VERSION "14.1.0"

NS_ :

BS_:

BU_: CUSTOMER_ECU PACMOD

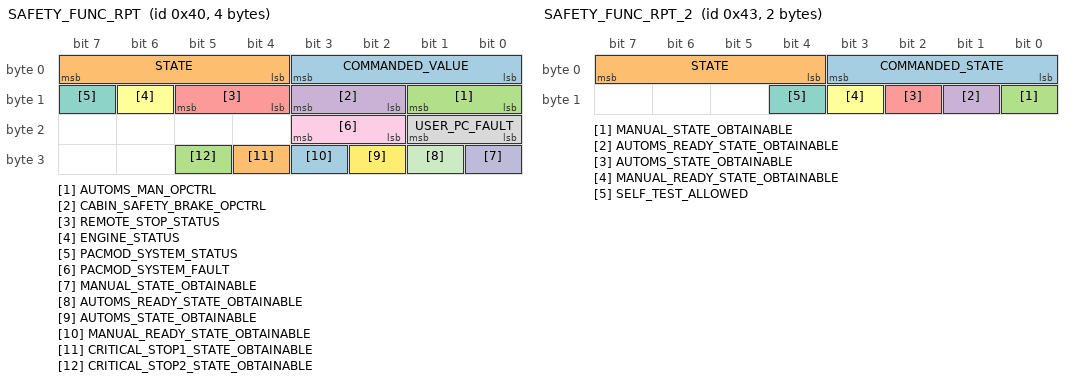
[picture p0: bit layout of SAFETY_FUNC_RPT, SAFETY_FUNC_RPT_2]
BO_ 64 SAFETY_FUNC_RPT: 4 PACMOD
 SG_ COMMANDED_VALUE : 3|4@0+ (1,0) [0|5] ""  CUSTOMER_ECU
 SG_ STATE : 7|4@0+ (1,0) [0|8] ""  CUSTOMER_ECU
 SG_ AUTOMS_MAN_OPCTRL : 9|2@0+ (1,0) [0|2] ""  CUSTOMER_ECU
 SG_ CABIN_SAFETY_BRAKE_OPCTRL : 11|2@0+ (1,0) [0|2] ""  CUSTOMER_ECU
 SG_ REMOTE_STOP_STATUS : 13|2@0+ (1,0) [0|2] ""  CUSTOMER_ECU
 SG_ ENGINE_STATUS : 14|1@0+ (1,0) [0|1] ""  CUSTOMER_ECU
 SG_ PACMOD_SYSTEM_STATUS : 15|1@0+ (1,0) [0|1] ""  CUSTOMER_ECU
 SG_ USER_PC_FAULT : 17|2@0+ (1,0) [0|2] ""  CUSTOMER_ECU
 SG_ PACMOD_SYSTEM_FAULT : 19|2@0+ (1,0) [0|2] ""  CUSTOMER_ECU
 SG_ MANUAL_STATE_OBTAINABLE : 24|1@0+ (1,0) [0|1] ""  CUSTOMER_ECU
 SG_ AUTOMS_READY_STATE_OBTAINABLE : 25|1@0+ (1,0) [0|1] ""  CUSTOMER_ECU
 SG_ AUTOMS_STATE_OBTAINABLE : 26|1@0+ (1,0) [0|1] ""  CUSTOMER_ECU
 SG_ MANUAL_READY_STATE_OBTAINABLE : 27|1@0+ (1,0) [0|1] ""  CUSTOMER_ECU
 SG_ CRITICAL_STOP1_STATE_OBTAINABLE : 28|1@0+ (1,0) [0|1] ""  CUSTOMER_ECU
 SG_ CRITICAL_STOP2_STATE_OBTAINABLE : 29|1@0+ (1,0) [0|1] ""  CUSTOMER_ECU

BO_ 67 SAFETY_FUNC_RPT_2: 2 PACMOD
 SG_ COMMANDED_STATE : 3|4@0+ (1,0) [0|3] ""  CUSTOMER_ECU
 SG_ STATE : 7|4@0+ (1,0) [0|15] ""  CUSTOMER_ECU
 SG_ MANUAL_STATE_OBTAINABLE : 8|1@0+ (1,0) [0|1] ""  CUSTOMER_ECU
 SG_ AUTOMS_READY_STATE_OBTAINABLE : 9|1@0+ (1,0) [0|1] ""  CUSTOMER_ECU
 SG_ AUTOMS_STATE_OBTAINABLE : 10|1@0+ (1,0) [0|1] ""  CUSTOMER_ECU
 SG_ MANUAL_READY_STATE_OBTAINABLE : 11|1@0+ (1,0) [0|1] ""  CUSTOMER_ECU
 SG_ SELF_TEST_ALLOWED : 12|1@0+ (1,0) [0|1] ""  CUSTOMER_ECU

BO_ 68 SAFETY_RESPONSE_RPT: 1 PACMOD
 SG_ SAFETY_RESPONSE : 3|4@0+ (1,0) [0|3] ""  CUSTOMER_ECU

BO_ 808 SHIFT_AUX_RPT: 7 PACMOD
 SG_ BETWEEN_GEARS : 0|1@0+ (1,0) [0|1] ""  CUSTOMER_ECU
 SG_ STAY_IN_NEUTRAL_MODE : 1|1@0+ (1,0) [0|1] ""  CUSTOMER_ECU
 SG_ BRAKE_INTERLOCK_ACTIVE : 2|1@0+ (1,0) [0|1] ""  CUSTOMER_ECU
 SG_ SPEED_INTERLOCK_ACTIVE : 3|1@0+ (1,0) [0|1] ""  CUSTOMER_ECU
 SG_ WRITE_TO_CONFIG : 4|1@0+ (1,0) [0|1] ""  CUSTOMER_ECU
 SG_ CALIBRATION_STATUS : 7|3@0+ (1,0) [0|3] ""  CUSTOMER_ECU
 SG_ BETWEEN_GEARS_AVAIL : 8|1@0+ (1,0) [0|1] ""  CUSTOMER_ECU
 SG_ STAY_IN_NEUTRAL_MODE_AVAIL : 9|1@0+ (1,0) [0|1] ""  CUSTOMER_ECU
 SG_ BRAKE_INTERLOCK_ACTIVE_AVAIL : 10|1@0+ (1,0) [0|1] ""  CUSTOMER_ECU
 SG_ SPEED_INTERLOCK_ACTIVE_AVAIL : 11|1@0+ (1,0) [0|1] ""  CUSTOMER_ECU
 SG_ WRITE_TO_CONFIG_IS_VALID : 12|1@0+ (1,0) [0|1] ""  CUSTOMER_ECU
 SG_ GEAR_NUMBER_AVAIL : 13|1@0+ (1,0) [0|1] ""  CUSTOMER_ECU
 SG_ SHIFT_MODE_AVAIL : 14|1@0+ (1,0) [0|1] ""  CUSTOMER_ECU
 SG_ SHIFT_IN_PROGRESS_AVAIL : 15|1@0+ (1,0) [0|1] ""  CUSTOMER_ECU
 SG_ GEAR_NUMBER : 21|6@0- (1,0) [-32|26] ""  CUSTOMER_ECU
 SG_ SHIFT_MODE : 23|2@0+ (1,0) [0|1] ""  CUSTOMER_ECU
 SG_ SHIFT_IN_PROGRESS : 25|2@0+ (1,0) [0|1] ""  CUSTOMER_ECU
 SG_ DRIVELINE_ENGAGED : 27|2@0+ (1,0) [0|1] ""  CUSTOMER_ECU
 SG_ ACTUAL_GEAR_RATIO : 39|16@0+ (0.001,0) [0|65.53] ""  CUSTOMER_ECU
 SG_ DRIVELINE_ENGAGED_AVAIL : 48|1@0+ (1,0) [0|1] ""  CUSTOMER_ECU
 SG_ ACTUAL_GEAR_RATIO_AVAIL : 49|1@0+ (1,0) [0|1] ""  CUSTOMER_ECU

BO_ 296 SHIFT_CMD: 2 CUSTOMER_ECU
 SG_ ENABLE : 0|1@0+ (1,0) [0|1] ""  PACMOD
 SG_ IGNORE_OVERRIDES : 1|1@0+ (1,0) [0|1] ""  PACMOD
 SG_ CLEAR_OVERRIDE : 2|1@0+ (1,0) [0|1] ""  PACMOD
 SG_ SHIFT_CMD : 15|8@0+ (1,0) [0|4] ""  PACMOD

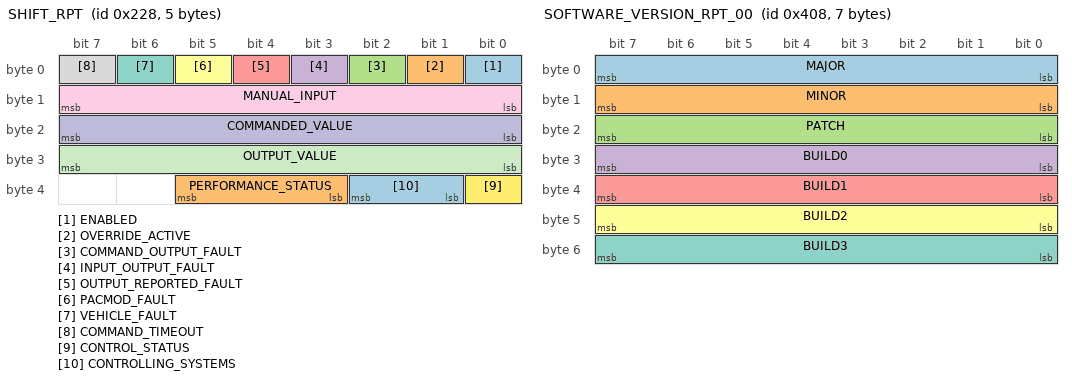
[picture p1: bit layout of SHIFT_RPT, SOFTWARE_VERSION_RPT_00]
BO_ 552 SHIFT_RPT: 5 PACMOD
 SG_ ENABLED : 0|1@0+ (1,0) [0|1] ""  CUSTOMER_ECU
 SG_ OVERRIDE_ACTIVE : 1|1@0+ (1,0) [0|1] ""  CUSTOMER_ECU
 SG_ COMMAND_OUTPUT_FAULT : 2|1@0+ (1,0) [0|1] ""  CUSTOMER_ECU
 SG_ INPUT_OUTPUT_FAULT : 3|1@0+ (1,0) [0|1] ""  CUSTOMER_ECU
 SG_ OUTPUT_REPORTED_FAULT : 4|1@0+ (1,0) [0|1] ""  CUSTOMER_ECU
 SG_ PACMOD_FAULT : 5|1@0+ (1,0) [0|1] ""  CUSTOMER_ECU
 SG_ VEHICLE_FAULT : 6|1@0+ (1,0) [0|1] ""  CUSTOMER_ECU
 SG_ COMMAND_TIMEOUT : 7|1@0+ (1,0) [0|1] ""  CUSTOMER_ECU
 SG_ MANUAL_INPUT : 15|8@0+ (1,0) [0|4] ""  CUSTOMER_ECU
 SG_ COMMANDED_VALUE : 23|8@0+ (1,0) [0|4] ""  CUSTOMER_ECU
 SG_ OUTPUT_VALUE : 31|8@0+ (1,0) [0|4] ""  CUSTOMER_ECU
 SG_ CONTROL_STATUS : 32|1@0+ (1,0) [0|1] ""  CUSTOMER_ECU
 SG_ CONTROLLING_SYSTEMS : 34|2@0+ (1,0) [0|3] ""  CUSTOMER_ECU
 SG_ PERFORMANCE_STATUS : 37|3@0+ (1,0) [0|4] ""  CUSTOMER_ECU

BO_ 1032 SOFTWARE_VERSION_RPT_00: 7 PACMOD
 SG_ MAJOR : 7|8@0+ (1,0) [0|255] ""  CUSTOMER_ECU
 SG_ MINOR : 15|8@0+ (1,0) [0|255] ""  CUSTOMER_ECU
 SG_ PATCH : 23|8@0+ (1,0) [0|255] ""  CUSTOMER_ECU
 SG_ BUILD0 : 31|8@0+ (1,0) [0|255] "ASCII"  CUSTOMER_ECU
 SG_ BUILD1 : 39|8@0+ (1,0) [0|255] "ASCII"  CUSTOMER_ECU
 SG_ BUILD2 : 47|8@0+ (1,0) [0|255] "ASCII"  CUSTOMER_ECU
 SG_ BUILD3 : 55|8@0+ (1,0) [0|255] "ASCII"  CUSTOMER_ECU

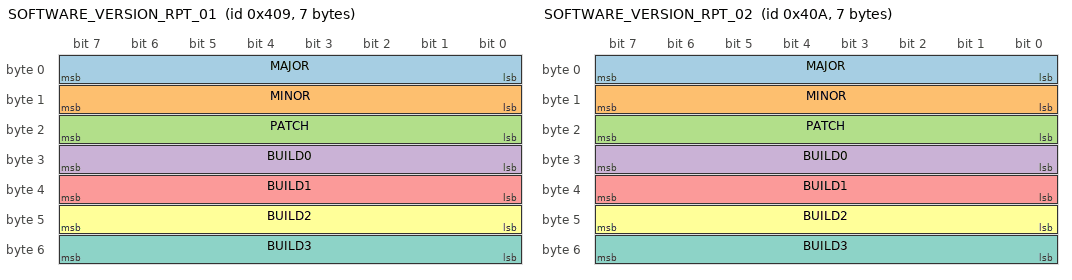
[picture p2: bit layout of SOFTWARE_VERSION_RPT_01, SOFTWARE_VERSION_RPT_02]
BO_ 1033 SOFTWARE_VERSION_RPT_01: 7 PACMOD
 SG_ MAJOR : 7|8@0+ (1,0) [0|255] ""  CUSTOMER_ECU
 SG_ MINOR : 15|8@0+ (1,0) [0|255] ""  CUSTOMER_ECU
 SG_ PATCH : 23|8@0+ (1,0) [0|255] ""  CUSTOMER_ECU
 SG_ BUILD0 : 31|8@0+ (1,0) [0|255] "ASCII"  CUSTOMER_ECU
 SG_ BUILD1 : 39|8@0+ (1,0) [0|255] "ASCII"  CUSTOMER_ECU
 SG_ BUILD2 : 47|8@0+ (1,0) [0|255] "ASCII"  CUSTOMER_ECU
 SG_ BUILD3 : 55|8@0+ (1,0) [0|255] "ASCII"  CUSTOMER_ECU

BO_ 1034 SOFTWARE_VERSION_RPT_02: 7 PACMOD
 SG_ MAJOR : 7|8@0+ (1,0) [0|255] ""  CUSTOMER_ECU
 SG_ MINOR : 15|8@0+ (1,0) [0|255] ""  CUSTOMER_ECU
 SG_ PATCH : 23|8@0+ (1,0) [0|255] ""  CUSTOMER_ECU
 SG_ BUILD0 : 31|8@0+ (1,0) [0|255] "ASCII"  CUSTOMER_ECU
 SG_ BUILD1 : 39|8@0+ (1,0) [0|255] "ASCII"  CUSTOMER_ECU
 SG_ BUILD2 : 47|8@0+ (1,0) [0|255] "ASCII"  CUSTOMER_ECU
 SG_ BUILD3 : 55|8@0+ (1,0) [0|255] "ASCII"  CUSTOMER_ECU

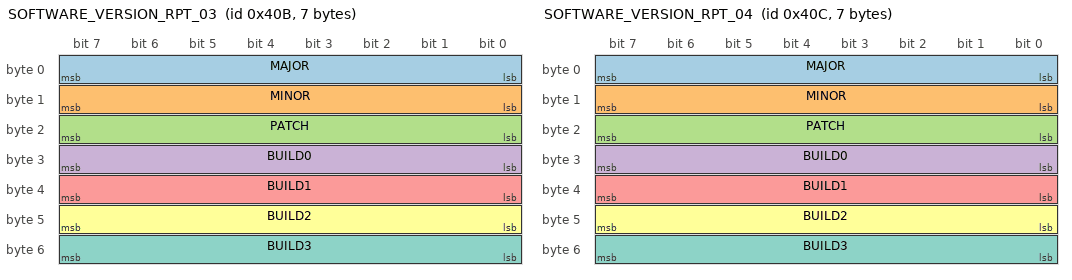
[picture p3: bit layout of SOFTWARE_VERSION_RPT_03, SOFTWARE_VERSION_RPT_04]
BO_ 1035 SOFTWARE_VERSION_RPT_03: 7 PACMOD
 SG_ MAJOR : 7|8@0+ (1,0) [0|255] ""  CUSTOMER_ECU
 SG_ MINOR : 15|8@0+ (1,0) [0|255] ""  CUSTOMER_ECU
 SG_ PATCH : 23|8@0+ (1,0) [0|255] ""  CUSTOMER_ECU
 SG_ BUILD0 : 31|8@0+ (1,0) [0|255] "ASCII"  CUSTOMER_ECU
 SG_ BUILD1 : 39|8@0+ (1,0) [0|255] "ASCII"  CUSTOMER_ECU
 SG_ BUILD2 : 47|8@0+ (1,0) [0|255] "ASCII"  CUSTOMER_ECU
 SG_ BUILD3 : 55|8@0+ (1,0) [0|255] "ASCII"  CUSTOMER_ECU

BO_ 1036 SOFTWARE_VERSION_RPT_04: 7 PACMOD
 SG_ MAJOR : 7|8@0+ (1,0) [0|255] ""  CUSTOMER_ECU
 SG_ MINOR : 15|8@0+ (1,0) [0|255] ""  CUSTOMER_ECU
 SG_ PATCH : 23|8@0+ (1,0) [0|255] ""  CUSTOMER_ECU
 SG_ BUILD0 : 31|8@0+ (1,0) [0|255] "ASCII"  CUSTOMER_ECU
 SG_ BUILD1 : 39|8@0+ (1,0) [0|255] "ASCII"  CUSTOMER_ECU
 SG_ BUILD2 : 47|8@0+ (1,0) [0|255] "ASCII"  CUSTOMER_ECU
 SG_ BUILD3 : 55|8@0+ (1,0) [0|255] "ASCII"  CUSTOMER_ECU

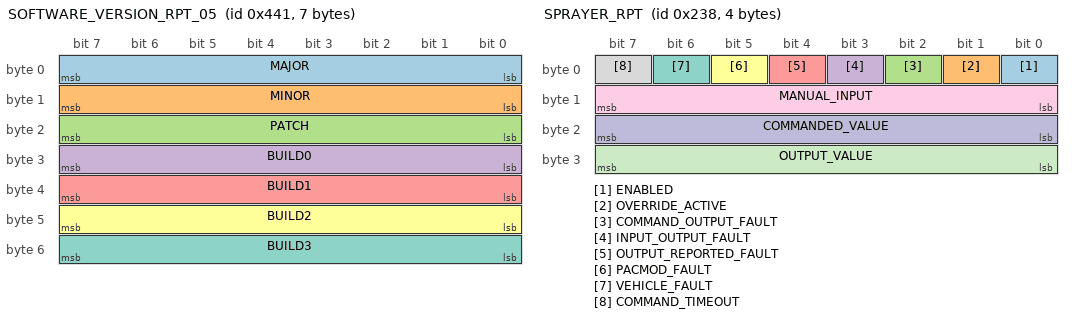
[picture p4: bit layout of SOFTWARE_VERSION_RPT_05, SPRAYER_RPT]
BO_ 1089 SOFTWARE_VERSION_RPT_05: 7 PACMOD
 SG_ MAJOR : 7|8@0+ (1,0) [0|255] ""  CUSTOMER_ECU
 SG_ MINOR : 15|8@0+ (1,0) [0|255] ""  CUSTOMER_ECU
 SG_ PATCH : 23|8@0+ (1,0) [0|255] ""  CUSTOMER_ECU
 SG_ BUILD0 : 31|8@0+ (1,0) [0|255] "ASCII"  CUSTOMER_ECU
 SG_ BUILD1 : 39|8@0+ (1,0) [0|255] "ASCII"  CUSTOMER_ECU
 SG_ BUILD2 : 47|8@0+ (1,0) [0|255] "ASCII"  CUSTOMER_ECU
 SG_ BUILD3 : 55|8@0+ (1,0) [0|255] "ASCII"  CUSTOMER_ECU

BO_ 312 SPRAYER_CMD: 2 CUSTOMER_ECU
 SG_ ENABLE : 0|1@0+ (1,0) [0|1] ""  PACMOD
 SG_ IGNORE_OVERRIDES : 1|1@0+ (1,0) [0|1] ""  PACMOD
 SG_ CLEAR_OVERRIDE : 2|1@0+ (1,0) [0|1] ""  PACMOD
 SG_ SPRAYER_CMD : 8|1@0+ (1,0) [0|1] ""  PACMOD

BO_ 568 SPRAYER_RPT: 4 PACMOD
 SG_ ENABLED : 0|1@0+ (1,0) [0|1] ""  CUSTOMER_ECU
 SG_ OVERRIDE_ACTIVE : 1|1@0+ (1,0) [0|1] ""  CUSTOMER_ECU
 SG_ COMMAND_OUTPUT_FAULT : 2|1@0+ (1,0) [0|1] ""  CUSTOMER_ECU
 SG_ INPUT_OUTPUT_FAULT : 3|1@0+ (1,0) [0|1] ""  CUSTOMER_ECU
 SG_ OUTPUT_REPORTED_FAULT : 4|1@0+ (1,0) [0|1] ""  CUSTOMER_ECU
 SG_ PACMOD_FAULT : 5|1@0+ (1,0) [0|1] ""  CUSTOMER_ECU
 SG_ VEHICLE_FAULT : 6|1@0+ (1,0) [0|1] ""  CUSTOMER_ECU
 SG_ COMMAND_TIMEOUT : 7|1@0+ (1,0) [0|1] ""  CUSTOMER_ECU
 SG_ MANUAL_INPUT : 15|8@0+ (1,0) [0|255] ""  CUSTOMER_ECU
 SG_ COMMANDED_VALUE : 23|8@0+ (1,0) [0|255] ""  CUSTOMER_ECU
 SG_ OUTPUT_VALUE : 31|8@0+ (1,0) [0|255] ""  CUSTOMER_ECU

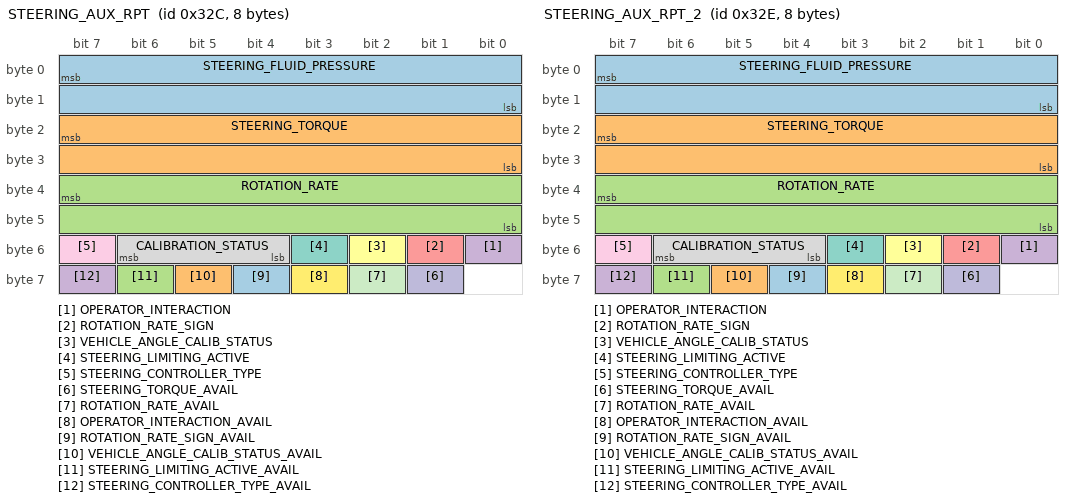
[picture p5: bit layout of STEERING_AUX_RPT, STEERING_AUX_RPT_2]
BO_ 812 STEERING_AUX_RPT: 8 PACMOD
 SG_ STEERING_FLUID_PRESSURE : 7|16@0+ (0.5,0) [0|32765] "kPa"  CUSTOMER_ECU
 SG_ STEERING_TORQUE : 23|16@0- (0.0001,0) [-2|2] "ratio"  CUSTOMER_ECU
 SG_ ROTATION_RATE : 39|16@0+ (0.001,0) [0|65.53] "rad/s"  CUSTOMER_ECU
 SG_ OPERATOR_INTERACTION : 48|1@0+ (1,0) [0|1] ""  CUSTOMER_ECU
 SG_ ROTATION_RATE_SIGN : 49|1@0+ (1,0) [0|1] ""  CUSTOMER_ECU
 SG_ VEHICLE_ANGLE_CALIB_STATUS : 50|1@0+ (1,0) [0|1] ""  CUSTOMER_ECU
 SG_ STEERING_LIMITING_ACTIVE : 51|1@0+ (1,0) [0|1] ""  CUSTOMER_ECU
 SG_ CALIBRATION_STATUS : 54|3@0+ (1,0) [0|3] ""  CUSTOMER_ECU
 SG_ STEERING_CONTROLLER_TYPE : 55|1@0+ (1,0) [0|1] ""  CUSTOMER_ECU
 SG_ STEERING_TORQUE_AVAIL : 57|1@0+ (1,0) [0|1] ""  CUSTOMER_ECU
 SG_ ROTATION_RATE_AVAIL : 58|1@0+ (1,0) [0|1] ""  CUSTOMER_ECU
 SG_ OPERATOR_INTERACTION_AVAIL : 59|1@0+ (1,0) [0|1] ""  CUSTOMER_ECU
 SG_ ROTATION_RATE_SIGN_AVAIL : 60|1@0+ (1,0) [0|1] ""  CUSTOMER_ECU
 SG_ VEHICLE_ANGLE_CALIB_STATUS_AVAIL : 61|1@0+ (1,0) [0|1] ""  CUSTOMER_ECU
 SG_ STEERING_LIMITING_ACTIVE_AVAIL : 62|1@0+ (1,0) [0|1] ""  CUSTOMER_ECU
 SG_ STEERING_CONTROLLER_TYPE_AVAIL : 63|1@0+ (1,0) [0|1] ""  CUSTOMER_ECU

BO_ 814 STEERING_AUX_RPT_2: 8 PACMOD
 SG_ STEERING_FLUID_PRESSURE : 7|16@0+ (0.5,0) [0|32765] "kPa"  CUSTOMER_ECU
 SG_ STEERING_TORQUE : 23|16@0- (0.0001,0) [-2|2] "ratio"  CUSTOMER_ECU
 SG_ ROTATION_RATE : 39|16@0+ (0.001,0) [0|65.53] "rad/s"  CUSTOMER_ECU
 SG_ OPERATOR_INTERACTION : 48|1@0+ (1,0) [0|1] ""  CUSTOMER_ECU
 SG_ ROTATION_RATE_SIGN : 49|1@0+ (1,0) [0|1] ""  CUSTOMER_ECU
 SG_ VEHICLE_ANGLE_CALIB_STATUS : 50|1@0+ (1,0) [0|1] ""  CUSTOMER_ECU
 SG_ STEERING_LIMITING_ACTIVE : 51|1@0+ (1,0) [0|1] ""  CUSTOMER_ECU
 SG_ CALIBRATION_STATUS : 54|3@0+ (1,0) [0|3] ""  CUSTOMER_ECU
 SG_ STEERING_CONTROLLER_TYPE : 55|1@0+ (1,0) [0|1] ""  CUSTOMER_ECU
 SG_ STEERING_TORQUE_AVAIL : 57|1@0+ (1,0) [0|1] ""  CUSTOMER_ECU
 SG_ ROTATION_RATE_AVAIL : 58|1@0+ (1,0) [0|1] ""  CUSTOMER_ECU
 SG_ OPERATOR_INTERACTION_AVAIL : 59|1@0+ (1,0) [0|1] ""  CUSTOMER_ECU
 SG_ ROTATION_RATE_SIGN_AVAIL : 60|1@0+ (1,0) [0|1] ""  CUSTOMER_ECU
 SG_ VEHICLE_ANGLE_CALIB_STATUS_AVAIL : 61|1@0+ (1,0) [0|1] ""  CUSTOMER_ECU
 SG_ STEERING_LIMITING_ACTIVE_AVAIL : 62|1@0+ (1,0) [0|1] ""  CUSTOMER_ECU
 SG_ STEERING_CONTROLLER_TYPE_AVAIL : 63|1@0+ (1,0) [0|1] ""  CUSTOMER_ECU

BO_ 300 STEERING_CMD: 5 CUSTOMER_ECU
 SG_ ENABLE : 0|1@0+ (1,0) [0|1] ""  PACMOD
 SG_ IGNORE_OVERRIDES : 1|1@0+ (1,0) [0|1] ""  PACMOD
 SG_ CLEAR_OVERRIDE : 2|1@0+ (1,0) [0|1] ""  PACMOD
 SG_ POSITION : 15|16@0- (0.001,0) [-32.768|32.767] "rad"  PACMOD
 SG_ ROTATION_RATE : 31|16@0+ (0.001,0) [0|65.535] "rad/s"  PACMOD

BO_ 557 STEERING_CMD_LIMIT_RPT: 8 PACMOD
 SG_ POSITION_CMD_LIMIT : 7|16@0- (0.001,0) [-32.768|32.767] "rad"  CUSTOMER_ECU
 SG_ LIMITED_POSITION_CMD : 23|16@0- (0.001,0) [-32.768|32.767] "rad"  CUSTOMER_ECU
 SG_ ROTATION_RATE_CMD_LIMIT : 39|16@0+ (0.001,0) [0|32.768] "rad/s"  CUSTOMER_ECU
 SG_ LIMITED_ROTATION_RATE : 55|16@0+ (0.001,0) [0|32.768] "rad/s"  CUSTOMER_ECU

BO_ 1028 STEERING_MOTOR_RPT_1: 8 PACMOD
 SG_ MOTOR_CURRENT : 7|32@0- (0.001,0) [-2048.0|2048.0] "amps"  CUSTOMER_ECU
 SG_ SHAFT_POSITION : 39|32@0- (0.001,0) [-2048.0|2048.0] "radians"  CUSTOMER_ECU

BO_ 1029 STEERING_MOTOR_RPT_2: 8 PACMOD
 SG_ ENCODER_TEMPERATURE : 7|16@0- (1,0) [-40|210] "deg_C"  CUSTOMER_ECU
 SG_ MOTOR_TEMPERATURE : 23|16@0- (1,0) [-40|210] "deg_C"  CUSTOMER_ECU
 SG_ ANGULAR_SPEED : 39|32@0- (0.001,0) [-12868.0|12868.0] "rad/s"  CUSTOMER_ECU

BO_ 1030 STEERING_MOTOR_RPT_3: 8 PACMOD
 SG_ TORQUE_OUTPUT : 7|32@0- (0.001,0) [-2048.0|2048.0] "N-m"  CUSTOMER_ECU
 SG_ TORQUE_INPUT : 39|32@0- (0.001,0) [-2048.0|2048.0] "N-m"  CUSTOMER_ECU

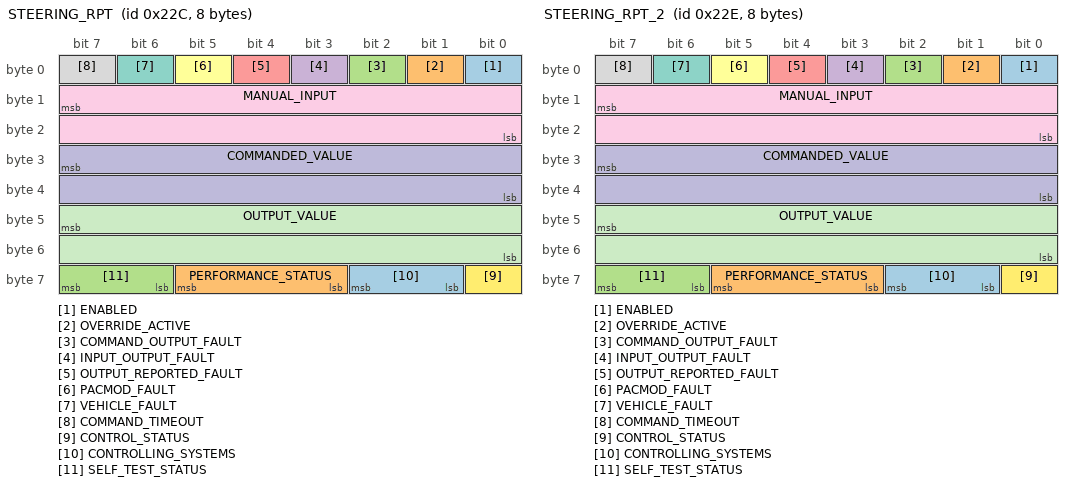
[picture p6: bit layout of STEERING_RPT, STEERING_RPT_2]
BO_ 556 STEERING_RPT: 8 PACMOD
 SG_ ENABLED : 0|1@0+ (1,0) [0|1] ""  CUSTOMER_ECU
 SG_ OVERRIDE_ACTIVE : 1|1@0+ (1,0) [0|1] ""  CUSTOMER_ECU
 SG_ COMMAND_OUTPUT_FAULT : 2|1@0+ (1,0) [0|1] ""  CUSTOMER_ECU
 SG_ INPUT_OUTPUT_FAULT : 3|1@0+ (1,0) [0|1] ""  CUSTOMER_ECU
 SG_ OUTPUT_REPORTED_FAULT : 4|1@0+ (1,0) [0|1] ""  CUSTOMER_ECU
 SG_ PACMOD_FAULT : 5|1@0+ (1,0) [0|1] ""  CUSTOMER_ECU
 SG_ VEHICLE_FAULT : 6|1@0+ (1,0) [0|1] ""  CUSTOMER_ECU
 SG_ COMMAND_TIMEOUT : 7|1@0+ (1,0) [0|1] ""  CUSTOMER_ECU
 SG_ MANUAL_INPUT : 15|16@0- (0.001,0) [-32.768|32.762] "rad"  CUSTOMER_ECU
 SG_ COMMANDED_VALUE : 31|16@0- (0.001,0) [-32.768|32.762] "rad"  CUSTOMER_ECU
 SG_ OUTPUT_VALUE : 47|16@0- (0.001,0) [-32.768|32.762] "rad"  CUSTOMER_ECU
 SG_ CONTROL_STATUS : 56|1@0+ (1,0) [0|1] ""  CUSTOMER_ECU
 SG_ CONTROLLING_SYSTEMS : 58|2@0+ (1,0) [0|3] ""  CUSTOMER_ECU
 SG_ PERFORMANCE_STATUS : 61|3@0+ (1,0) [0|4] ""  CUSTOMER_ECU
 SG_ SELF_TEST_STATUS : 63|2@0+ (1,0) [0|3] ""  CUSTOMER_ECU

BO_ 558 STEERING_RPT_2: 8 PACMOD
 SG_ ENABLED : 0|1@0+ (1,0) [0|1] ""  CUSTOMER_ECU
 SG_ OVERRIDE_ACTIVE : 1|1@0+ (1,0) [0|1] ""  CUSTOMER_ECU
 SG_ COMMAND_OUTPUT_FAULT : 2|1@0+ (1,0) [0|1] ""  CUSTOMER_ECU
 SG_ INPUT_OUTPUT_FAULT : 3|1@0+ (1,0) [0|1] ""  CUSTOMER_ECU
 SG_ OUTPUT_REPORTED_FAULT : 4|1@0+ (1,0) [0|1] ""  CUSTOMER_ECU
 SG_ PACMOD_FAULT : 5|1@0+ (1,0) [0|1] ""  CUSTOMER_ECU
 SG_ VEHICLE_FAULT : 6|1@0+ (1,0) [0|1] ""  CUSTOMER_ECU
 SG_ COMMAND_TIMEOUT : 7|1@0+ (1,0) [0|1] ""  CUSTOMER_ECU
 SG_ MANUAL_INPUT : 15|16@0- (0.001,0) [-32.768|32.762] "rad"  CUSTOMER_ECU
 SG_ COMMANDED_VALUE : 31|16@0- (0.001,0) [-32.768|32.762] "rad"  CUSTOMER_ECU
 SG_ OUTPUT_VALUE : 47|16@0- (0.001,0) [-32.768|32.762] "rad"  CUSTOMER_ECU
 SG_ CONTROL_STATUS : 56|1@0+ (1,0) [0|1] ""  CUSTOMER_ECU
 SG_ CONTROLLING_SYSTEMS : 58|2@0+ (1,0) [0|3] ""  CUSTOMER_ECU
 SG_ PERFORMANCE_STATUS : 61|3@0+ (1,0) [0|4] ""  CUSTOMER_ECU
 SG_ SELF_TEST_STATUS : 63|2@0+ (1,0) [0|3] ""  CUSTOMER_ECU

BO_ 1093 STEERING_TRQ_SENSOR_VOLTAGE_RPT: 8 PACMOD
 SG_ PACMOD_VOLTAGE_IN_1 : 7|16@0+ (0.001,0) [0|65] "V"  CUSTOMER_ECU
 SG_ PACMOD_VOLTAGE_IN_2 : 23|16@0+ (0.001,0) [0|65] "V"  CUSTOMER_ECU
 SG_ PACMOD_VOLTAGE_OUT_1 : 39|16@0+ (0.001,0) [0|65] "V"  CUSTOMER_ECU
 SG_ PACMOD_VOLTAGE_OUT_2 : 55|16@0+ (0.001,0) [0|65] "V"  CUSTOMER_ECU

BO_ 129 SUPERVISORY_CTRL: 2 CUSTOMER_ECU
 SG_ ENABLE : 0|1@0+ (1,0) [0|1] ""  PACMOD
 SG_ COUNTER : 11|4@0+ (1,0) [0|15] "" PACMOD
 SG_ COMPLEMENT : 15|4@0+ (1,0) [0|15] "" PACMOD

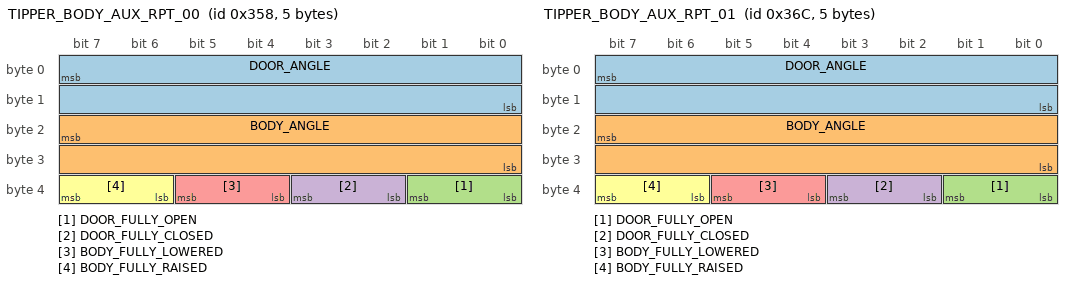
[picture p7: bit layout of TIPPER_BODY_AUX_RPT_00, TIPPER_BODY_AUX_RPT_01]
BO_ 856 TIPPER_BODY_AUX_RPT_00: 5 PACMOD
 SG_ DOOR_ANGLE : 7|16@0- (0.001,0) [-32.768|32.762] "rad"  CUSTOMER_ECU
 SG_ BODY_ANGLE : 23|16@0- (0.001,0) [-32.768|32.762] "rad"  CUSTOMER_ECU
 SG_ DOOR_FULLY_OPEN : 33|2@0+ (1,0) [0|3] ""  CUSTOMER_ECU
 SG_ DOOR_FULLY_CLOSED : 35|2@0+ (1,0) [0|3] ""  CUSTOMER_ECU
 SG_ BODY_FULLY_LOWERED : 37|2@0+ (1,0) [0|3] ""  CUSTOMER_ECU
 SG_ BODY_FULLY_RAISED : 39|2@0+ (1,0) [0|3] ""  CUSTOMER_ECU

BO_ 876 TIPPER_BODY_AUX_RPT_01: 5 PACMOD
 SG_ DOOR_ANGLE : 7|16@0- (0.001,0) [-32.768|32.762] "rad"  CUSTOMER_ECU
 SG_ BODY_ANGLE : 23|16@0- (0.001,0) [-32.768|32.762] "rad"  CUSTOMER_ECU
 SG_ DOOR_FULLY_OPEN : 33|2@0+ (1,0) [0|3] ""  CUSTOMER_ECU
 SG_ DOOR_FULLY_CLOSED : 35|2@0+ (1,0) [0|3] ""  CUSTOMER_ECU
 SG_ BODY_FULLY_LOWERED : 37|2@0+ (1,0) [0|3] ""  CUSTOMER_ECU
 SG_ BODY_FULLY_RAISED : 39|2@0+ (1,0) [0|3] ""  CUSTOMER_ECU

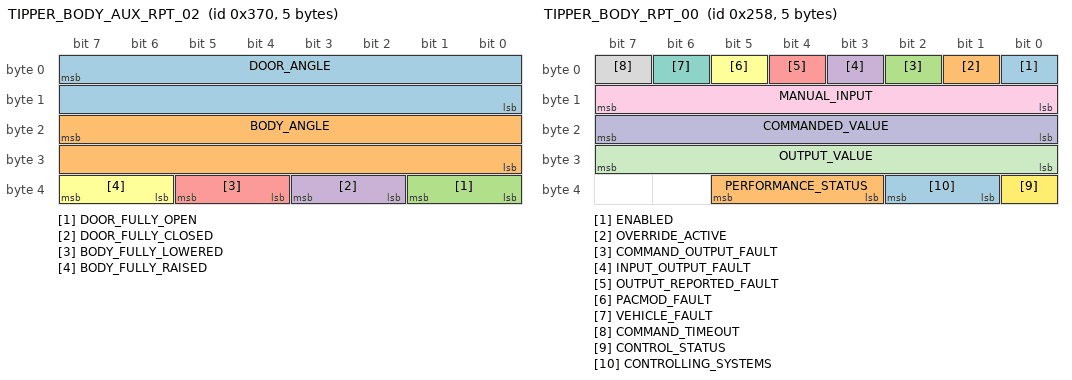
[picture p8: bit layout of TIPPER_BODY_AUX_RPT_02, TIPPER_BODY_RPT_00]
BO_ 880 TIPPER_BODY_AUX_RPT_02: 5 PACMOD
 SG_ DOOR_ANGLE : 7|16@0- (0.001,0) [-32.768|32.762] "rad"  CUSTOMER_ECU
 SG_ BODY_ANGLE : 23|16@0- (0.001,0) [-32.768|32.762] "rad"  CUSTOMER_ECU
 SG_ DOOR_FULLY_OPEN : 33|2@0+ (1,0) [0|3] ""  CUSTOMER_ECU
 SG_ DOOR_FULLY_CLOSED : 35|2@0+ (1,0) [0|3] ""  CUSTOMER_ECU
 SG_ BODY_FULLY_LOWERED : 37|2@0+ (1,0) [0|3] ""  CUSTOMER_ECU
 SG_ BODY_FULLY_RAISED : 39|2@0+ (1,0) [0|3] ""  CUSTOMER_ECU

BO_ 344 TIPPER_BODY_CMD_00: 2 CUSTOMER_ECU
 SG_ ENABLE : 0|1@0+ (1,0) [0|1] ""  PACMOD
 SG_ IGNORE_OVERRIDES : 1|1@0+ (1,0) [0|1] ""  PACMOD
 SG_ CLEAR_OVERRIDE : 2|1@0+ (1,0) [0|1] ""  PACMOD
 SG_ TIPPER_CONTROL_CMD : 15|8@0+ (1,0) [0|2] ""  PACMOD

BO_ 364 TIPPER_BODY_CMD_01: 2 CUSTOMER_ECU
 SG_ ENABLE : 0|1@0+ (1,0) [0|1] ""  PACMOD
 SG_ IGNORE_OVERRIDES : 1|1@0+ (1,0) [0|1] ""  PACMOD
 SG_ CLEAR_OVERRIDE : 2|1@0+ (1,0) [0|1] ""  PACMOD
 SG_ TIPPER_CONTROL_CMD : 15|8@0+ (1,0) [0|2] ""  PACMOD

BO_ 368 TIPPER_BODY_CMD_02: 2 CUSTOMER_ECU
 SG_ ENABLE : 0|1@0+ (1,0) [0|1] ""  PACMOD
 SG_ IGNORE_OVERRIDES : 1|1@0+ (1,0) [0|1] ""  PACMOD
 SG_ CLEAR_OVERRIDE : 2|1@0+ (1,0) [0|1] ""  PACMOD
 SG_ TIPPER_CONTROL_CMD : 15|8@0+ (1,0) [0|2] ""  PACMOD

BO_ 600 TIPPER_BODY_RPT_00: 5 PACMOD
 SG_ ENABLED : 0|1@0+ (1,0) [0|1] ""  CUSTOMER_ECU
 SG_ OVERRIDE_ACTIVE : 1|1@0+ (1,0) [0|1] ""  CUSTOMER_ECU
 SG_ COMMAND_OUTPUT_FAULT : 2|1@0+ (1,0) [0|1] ""  CUSTOMER_ECU
 SG_ INPUT_OUTPUT_FAULT : 3|1@0+ (1,0) [0|1] ""  CUSTOMER_ECU
 SG_ OUTPUT_REPORTED_FAULT : 4|1@0+ (1,0) [0|1] ""  CUSTOMER_ECU
 SG_ PACMOD_FAULT : 5|1@0+ (1,0) [0|1] ""  CUSTOMER_ECU
 SG_ VEHICLE_FAULT : 6|1@0+ (1,0) [0|1] ""  CUSTOMER_ECU
 SG_ COMMAND_TIMEOUT : 7|1@0+ (1,0) [0|1] ""  CUSTOMER_ECU
 SG_ MANUAL_INPUT : 15|8@0+ (1,0) [0|255] ""  CUSTOMER_ECU
 SG_ COMMANDED_VALUE : 23|8@0+ (1,0) [0|255] ""  CUSTOMER_ECU
 SG_ OUTPUT_VALUE : 31|8@0+ (1,0) [0|255] ""  CUSTOMER_ECU
 SG_ CONTROL_STATUS : 32|1@0+ (1,0) [0|1] ""  CUSTOMER_ECU
 SG_ CONTROLLING_SYSTEMS : 34|2@0+ (1,0) [0|3] ""  CUSTOMER_ECU
 SG_ PERFORMANCE_STATUS : 37|3@0+ (1,0) [0|4] ""  CUSTOMER_ECU

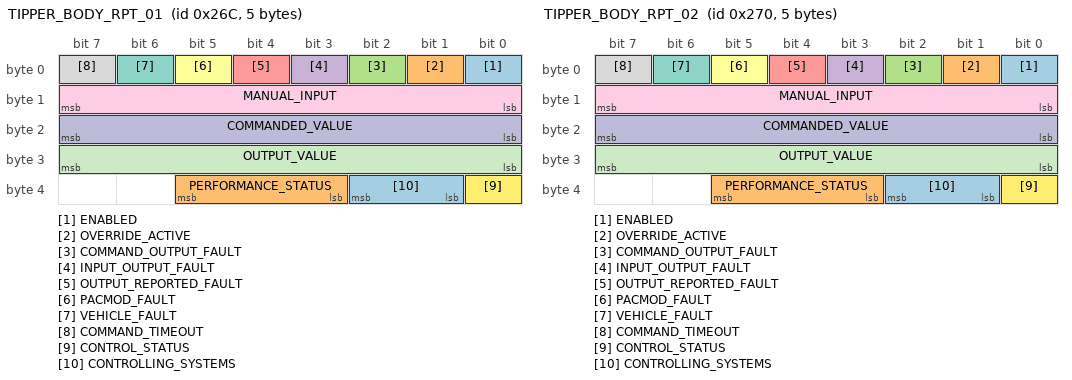
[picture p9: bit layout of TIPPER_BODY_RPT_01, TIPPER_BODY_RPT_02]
BO_ 620 TIPPER_BODY_RPT_01: 5 PACMOD
 SG_ ENABLED : 0|1@0+ (1,0) [0|1] ""  CUSTOMER_ECU
 SG_ OVERRIDE_ACTIVE : 1|1@0+ (1,0) [0|1] ""  CUSTOMER_ECU
 SG_ COMMAND_OUTPUT_FAULT : 2|1@0+ (1,0) [0|1] ""  CUSTOMER_ECU
 SG_ INPUT_OUTPUT_FAULT : 3|1@0+ (1,0) [0|1] ""  CUSTOMER_ECU
 SG_ OUTPUT_REPORTED_FAULT : 4|1@0+ (1,0) [0|1] ""  CUSTOMER_ECU
 SG_ PACMOD_FAULT : 5|1@0+ (1,0) [0|1] ""  CUSTOMER_ECU
 SG_ VEHICLE_FAULT : 6|1@0+ (1,0) [0|1] ""  CUSTOMER_ECU
 SG_ COMMAND_TIMEOUT : 7|1@0+ (1,0) [0|1] ""  CUSTOMER_ECU
 SG_ MANUAL_INPUT : 15|8@0+ (1,0) [0|255] ""  CUSTOMER_ECU
 SG_ COMMANDED_VALUE : 23|8@0+ (1,0) [0|255] ""  CUSTOMER_ECU
 SG_ OUTPUT_VALUE : 31|8@0+ (1,0) [0|255] ""  CUSTOMER_ECU
 SG_ CONTROL_STATUS : 32|1@0+ (1,0) [0|1] ""  CUSTOMER_ECU
 SG_ CONTROLLING_SYSTEMS : 34|2@0+ (1,0) [0|3] ""  CUSTOMER_ECU
 SG_ PERFORMANCE_STATUS : 37|3@0+ (1,0) [0|4] ""  CUSTOMER_ECU

BO_ 624 TIPPER_BODY_RPT_02: 5 PACMOD
 SG_ ENABLED : 0|1@0+ (1,0) [0|1] ""  CUSTOMER_ECU
 SG_ OVERRIDE_ACTIVE : 1|1@0+ (1,0) [0|1] ""  CUSTOMER_ECU
 SG_ COMMAND_OUTPUT_FAULT : 2|1@0+ (1,0) [0|1] ""  CUSTOMER_ECU
 SG_ INPUT_OUTPUT_FAULT : 3|1@0+ (1,0) [0|1] ""  CUSTOMER_ECU
 SG_ OUTPUT_REPORTED_FAULT : 4|1@0+ (1,0) [0|1] ""  CUSTOMER_ECU
 SG_ PACMOD_FAULT : 5|1@0+ (1,0) [0|1] ""  CUSTOMER_ECU
 SG_ VEHICLE_FAULT : 6|1@0+ (1,0) [0|1] ""  CUSTOMER_ECU
 SG_ COMMAND_TIMEOUT : 7|1@0+ (1,0) [0|1] ""  CUSTOMER_ECU
 SG_ MANUAL_INPUT : 15|8@0+ (1,0) [0|255] ""  CUSTOMER_ECU
 SG_ COMMANDED_VALUE : 23|8@0+ (1,0) [0|255] ""  CUSTOMER_ECU
 SG_ OUTPUT_VALUE : 31|8@0+ (1,0) [0|255] ""  CUSTOMER_ECU
 SG_ CONTROL_STATUS : 32|1@0+ (1,0) [0|1] ""  CUSTOMER_ECU
 SG_ CONTROLLING_SYSTEMS : 34|2@0+ (1,0) [0|3] ""  CUSTOMER_ECU
 SG_ PERFORMANCE_STATUS : 37|3@0+ (1,0) [0|4] ""  CUSTOMER_ECU

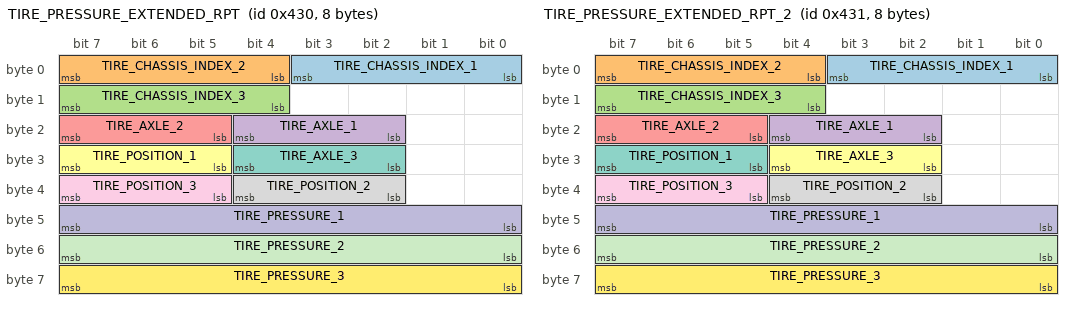
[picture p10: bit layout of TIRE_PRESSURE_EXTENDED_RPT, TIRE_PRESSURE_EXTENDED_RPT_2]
BO_ 1072 TIRE_PRESSURE_EXTENDED_RPT: 8 PACMOD
 SG_ TIRE_CHASSIS_INDEX_1 : 3|4@0+ (1,0) [0|15] ""  CUSTOMER_ECU
 SG_ TIRE_CHASSIS_INDEX_2 : 7|4@0+ (1,0) [0|15] ""  CUSTOMER_ECU
 SG_ TIRE_CHASSIS_INDEX_3 : 15|4@0+ (1,0) [0|15] ""  CUSTOMER_ECU
 SG_ TIRE_AXLE_1 : 20|3@0+ (1,0) [0|7] ""  CUSTOMER_ECU
 SG_ TIRE_AXLE_2 : 23|3@0+ (1,0) [0|7] ""  CUSTOMER_ECU
 SG_ TIRE_POSITION_1 : 31|3@0+ (1,0) [0|7] ""  CUSTOMER_ECU
 SG_ TIRE_AXLE_3 : 28|3@0+ (1,0) [0|7] ""  CUSTOMER_ECU
 SG_ TIRE_POSITION_2 : 36|3@0+ (1,0) [0|7] ""  CUSTOMER_ECU
 SG_ TIRE_POSITION_3 : 39|3@0+ (1,0) [0|7] ""  CUSTOMER_ECU
 SG_ TIRE_PRESSURE_1 : 47|8@0+ (10,0) [0|2500] "kPa"  CUSTOMER_ECU
 SG_ TIRE_PRESSURE_2 : 55|8@0+ (10,0) [0|2500] "kPa"  CUSTOMER_ECU
 SG_ TIRE_PRESSURE_3 : 63|8@0+ (10,0) [0|2500] "kPa"  CUSTOMER_ECU

BO_ 1073 TIRE_PRESSURE_EXTENDED_RPT_2: 8 PACMOD
 SG_ TIRE_CHASSIS_INDEX_1 : 3|4@0+ (1,0) [0|15] ""  CUSTOMER_ECU
 SG_ TIRE_CHASSIS_INDEX_2 : 7|4@0+ (1,0) [0|15] ""  CUSTOMER_ECU
 SG_ TIRE_CHASSIS_INDEX_3 : 15|4@0+ (1,0) [0|15] ""  CUSTOMER_ECU
 SG_ TIRE_AXLE_1 : 20|3@0+ (1,0) [0|7] ""  CUSTOMER_ECU
 SG_ TIRE_AXLE_2 : 23|3@0+ (1,0) [0|7] ""  CUSTOMER_ECU
 SG_ TIRE_AXLE_3 : 28|3@0+ (1,0) [0|7] ""  CUSTOMER_ECU
 SG_ TIRE_POSITION_1 : 31|3@0+ (1,0) [0|7] ""  CUSTOMER_ECU
 SG_ TIRE_POSITION_2 : 36|3@0+ (1,0) [0|7] ""  CUSTOMER_ECU
 SG_ TIRE_POSITION_3 : 39|3@0+ (1,0) [0|7] ""  CUSTOMER_ECU
 SG_ TIRE_PRESSURE_1 : 47|8@0+ (10,0) [0|2500] "kPa"  CUSTOMER_ECU
 SG_ TIRE_PRESSURE_2 : 55|8@0+ (10,0) [0|2500] "kPa"  CUSTOMER_ECU
 SG_ TIRE_PRESSURE_3 : 63|8@0+ (10,0) [0|2500] "kPa"  CUSTOMER_ECU

BO_ 1054 TIRE_PRESSURE_RPT: 4 PACMOD
 SG_ FRONT_LEFT_TIRE_PRESSURE : 7|8@0+ (4,0) [0|1020] "kPa"  CUSTOMER_ECU
 SG_ FRONT_RIGHT_TIRE_PRESSURE : 15|8@0+ (4,0) [0|1020] "kPa"  CUSTOMER_ECU
 SG_ REAR_LEFT_TIRE_PRESSURE : 23|8@0+ (4,0) [0|1020] "kPa"  CUSTOMER_ECU
 SG_ REAR_RIGHT_TIRE_PRESSURE : 31|8@0+ (4,0) [0|1020] "kPa"  CUSTOMER_ECU

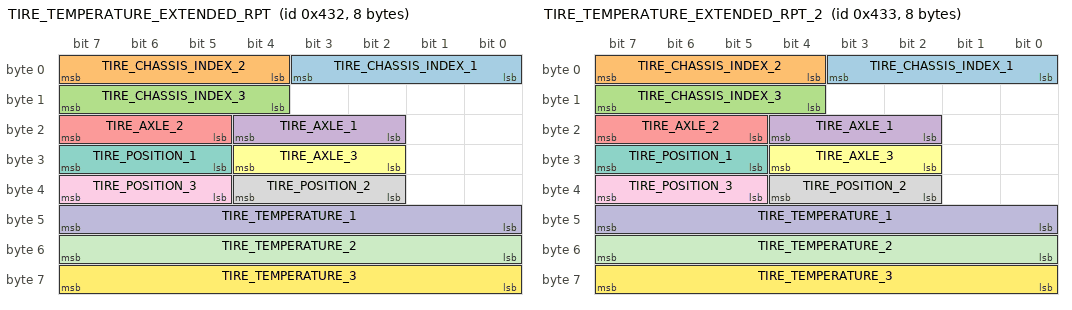
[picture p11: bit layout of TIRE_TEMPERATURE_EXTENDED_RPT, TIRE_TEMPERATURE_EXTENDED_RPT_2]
BO_ 1074 TIRE_TEMPERATURE_EXTENDED_RPT: 8 PACMOD
 SG_ TIRE_CHASSIS_INDEX_1 : 3|4@0+ (1,0) [0|15] ""  CUSTOMER_ECU
 SG_ TIRE_CHASSIS_INDEX_2 : 7|4@0+ (1,0) [0|15] ""  CUSTOMER_ECU
 SG_ TIRE_CHASSIS_INDEX_3 : 15|4@0+ (1,0) [0|15] ""  CUSTOMER_ECU
 SG_ TIRE_AXLE_1 : 20|3@0+ (1,0) [0|7] ""  CUSTOMER_ECU
 SG_ TIRE_AXLE_2 : 23|3@0+ (1,0) [0|7] ""  CUSTOMER_ECU
 SG_ TIRE_AXLE_3 : 28|3@0+ (1,0) [0|7] ""  CUSTOMER_ECU
 SG_ TIRE_POSITION_1 : 31|3@0+ (1,0) [0|7] ""  CUSTOMER_ECU
 SG_ TIRE_POSITION_2 : 36|3@0+ (1,0) [0|7] ""  CUSTOMER_ECU
 SG_ TIRE_POSITION_3 : 39|3@0+ (1,0) [0|7] ""  CUSTOMER_ECU
 SG_ TIRE_TEMPERATURE_1 : 47|8@0+ (1,-50) [0|200] "C"  CUSTOMER_ECU
 SG_ TIRE_TEMPERATURE_2 : 55|8@0+ (1,-50) [0|200] "C"  CUSTOMER_ECU
 SG_ TIRE_TEMPERATURE_3 : 63|8@0+ (1,-50) [0|200] "C"  CUSTOMER_ECU

BO_ 1075 TIRE_TEMPERATURE_EXTENDED_RPT_2: 8 PACMOD
 SG_ TIRE_CHASSIS_INDEX_1 : 3|4@0+ (1,0) [0|15] ""  CUSTOMER_ECU
 SG_ TIRE_CHASSIS_INDEX_2 : 7|4@0+ (1,0) [0|15] ""  CUSTOMER_ECU
 SG_ TIRE_CHASSIS_INDEX_3 : 15|4@0+ (1,0) [0|15] ""  CUSTOMER_ECU
 SG_ TIRE_AXLE_1 : 20|3@0+ (1,0) [0|7] ""  CUSTOMER_ECU
 SG_ TIRE_AXLE_2 : 23|3@0+ (1,0) [0|7] ""  CUSTOMER_ECU
 SG_ TIRE_AXLE_3 : 28|3@0+ (1,0) [0|7] ""  CUSTOMER_ECU
 SG_ TIRE_POSITION_1 : 31|3@0+ (1,0) [0|7] ""  CUSTOMER_ECU
 SG_ TIRE_POSITION_2 : 36|3@0+ (1,0) [0|7] ""  CUSTOMER_ECU
 SG_ TIRE_POSITION_3 : 39|3@0+ (1,0) [0|7] ""  CUSTOMER_ECU
 SG_ TIRE_TEMPERATURE_1 : 47|8@0+ (1,-50) [0|200] "C"  CUSTOMER_ECU
 SG_ TIRE_TEMPERATURE_2 : 55|8@0+ (1,-50) [0|200] "C"  CUSTOMER_ECU
 SG_ TIRE_TEMPERATURE_3 : 63|8@0+ (1,-50) [0|200] "C"  CUSTOMER_ECU

BO_ 356 TRAILER_AIR_SUPPLY_CMD: 2 CUSTOMER_ECU
 SG_ ENABLE : 0|1@0+ (1,0) [0|1] ""  PACMOD
 SG_ IGNORE_OVERRIDES : 1|1@0+ (1,0) [0|1] ""  PACMOD
 SG_ CLEAR_OVERRIDE : 2|1@0+ (1,0) [0|1] ""  PACMOD
 SG_ TRAILER_AIR_SUPPLY_CMD : 8|1@0+ (1,0) [0|1] ""  PACMOD

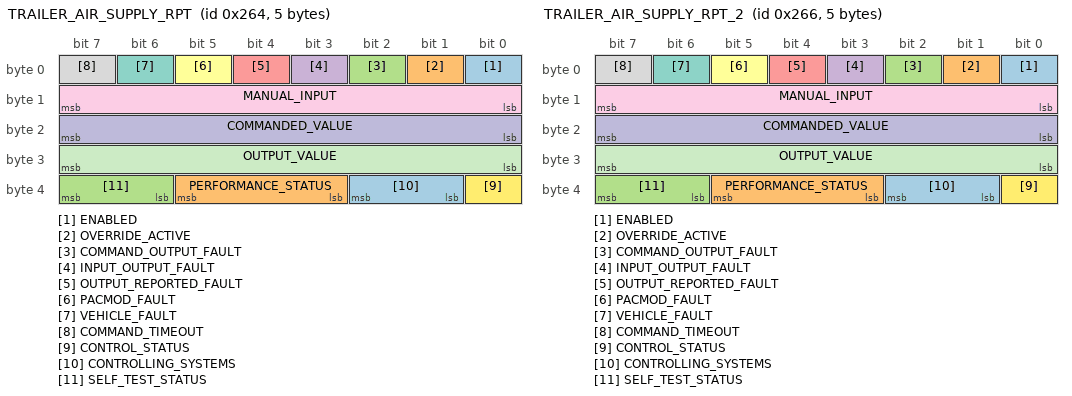
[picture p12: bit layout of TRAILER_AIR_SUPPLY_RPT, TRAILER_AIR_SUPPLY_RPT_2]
BO_ 612 TRAILER_AIR_SUPPLY_RPT: 5 PACMOD
 SG_ ENABLED : 0|1@0+ (1,0) [0|1] ""  CUSTOMER_ECU
 SG_ OVERRIDE_ACTIVE : 1|1@0+ (1,0) [0|1] ""  CUSTOMER_ECU
 SG_ COMMAND_OUTPUT_FAULT : 2|1@0+ (1,0) [0|1] ""  CUSTOMER_ECU
 SG_ INPUT_OUTPUT_FAULT : 3|1@0+ (1,0) [0|1] ""  CUSTOMER_ECU
 SG_ OUTPUT_REPORTED_FAULT : 4|1@0+ (1,0) [0|1] ""  CUSTOMER_ECU
 SG_ PACMOD_FAULT : 5|1@0+ (1,0) [0|1] ""  CUSTOMER_ECU
 SG_ VEHICLE_FAULT : 6|1@0+ (1,0) [0|1] ""  CUSTOMER_ECU
 SG_ COMMAND_TIMEOUT : 7|1@0+ (1,0) [0|1] ""  CUSTOMER_ECU
 SG_ MANUAL_INPUT : 15|8@0+ (1,0) [0|255] ""  CUSTOMER_ECU
 SG_ COMMANDED_VALUE : 23|8@0+ (1,0) [0|255] ""  CUSTOMER_ECU
 SG_ OUTPUT_VALUE : 31|8@0+ (1,0) [0|255] ""  CUSTOMER_ECU
 SG_ CONTROL_STATUS : 32|1@0+ (1,0) [0|1] ""  CUSTOMER_ECU
 SG_ CONTROLLING_SYSTEMS : 34|2@0+ (1,0) [0|3] ""  CUSTOMER_ECU
 SG_ PERFORMANCE_STATUS : 37|3@0+ (1,0) [0|4] ""  CUSTOMER_ECU
 SG_ SELF_TEST_STATUS : 39|2@0+ (1,0) [0|3] ""  CUSTOMER_ECU

BO_ 614 TRAILER_AIR_SUPPLY_RPT_2: 5 PACMOD
 SG_ ENABLED : 0|1@0+ (1,0) [0|1] ""  CUSTOMER_ECU
 SG_ OVERRIDE_ACTIVE : 1|1@0+ (1,0) [0|1] ""  CUSTOMER_ECU
 SG_ COMMAND_OUTPUT_FAULT : 2|1@0+ (1,0) [0|1] ""  CUSTOMER_ECU
 SG_ INPUT_OUTPUT_FAULT : 3|1@0+ (1,0) [0|1] ""  CUSTOMER_ECU
 SG_ OUTPUT_REPORTED_FAULT : 4|1@0+ (1,0) [0|1] ""  CUSTOMER_ECU
 SG_ PACMOD_FAULT : 5|1@0+ (1,0) [0|1] ""  CUSTOMER_ECU
 SG_ VEHICLE_FAULT : 6|1@0+ (1,0) [0|1] ""  CUSTOMER_ECU
 SG_ COMMAND_TIMEOUT : 7|1@0+ (1,0) [0|1] ""  CUSTOMER_ECU
 SG_ MANUAL_INPUT : 15|8@0+ (1,0) [0|255] ""  CUSTOMER_ECU
 SG_ COMMANDED_VALUE : 23|8@0+ (1,0) [0|255] ""  CUSTOMER_ECU
 SG_ OUTPUT_VALUE : 31|8@0+ (1,0) [0|255] ""  CUSTOMER_ECU
 SG_ CONTROL_STATUS : 32|1@0+ (1,0) [0|1] ""  CUSTOMER_ECU
 SG_ CONTROLLING_SYSTEMS : 34|2@0+ (1,0) [0|3] ""  CUSTOMER_ECU
 SG_ PERFORMANCE_STATUS : 37|3@0+ (1,0) [0|4] ""  CUSTOMER_ECU
 SG_ SELF_TEST_STATUS : 39|2@0+ (1,0) [0|3] ""  CUSTOMER_ECU

BO_ 352 TRAILER_BRAKE_CMD: 3 CUSTOMER_ECU
 SG_ ENABLE : 0|1@0+ (1,0) [0|1] ""  PACMOD
 SG_ IGNORE_OVERRIDES : 1|1@0+ (1,0) [0|1] ""  PACMOD
 SG_ CLEAR_OVERRIDE : 2|1@0+ (1,0) [0|1] ""  PACMOD
 SG_ TRAILER_BRAKE_CMD : 15|16@0+ (0.001,0) [0|1] "ratio"  PACMOD

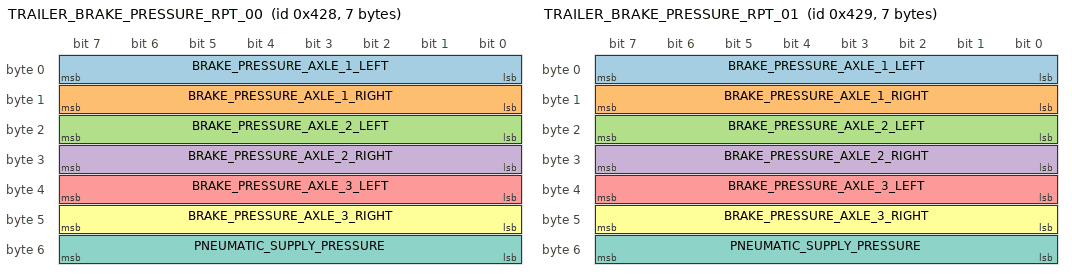
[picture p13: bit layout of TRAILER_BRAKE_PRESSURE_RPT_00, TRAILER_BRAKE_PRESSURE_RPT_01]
BO_ 1064 TRAILER_BRAKE_PRESSURE_RPT_00: 7 PACMOD
 SG_ BRAKE_PRESSURE_AXLE_1_LEFT : 7|8@0+ (5,0) [0|1250] "kPa"  CUSTOMER_ECU
 SG_ BRAKE_PRESSURE_AXLE_1_RIGHT : 15|8@0+ (5,0) [0|1250] "kPa"  CUSTOMER_ECU
 SG_ BRAKE_PRESSURE_AXLE_2_LEFT : 23|8@0+ (5,0) [0|1250] "kPa"  CUSTOMER_ECU
 SG_ BRAKE_PRESSURE_AXLE_2_RIGHT : 31|8@0+ (5,0) [0|1250] "kPa"  CUSTOMER_ECU
 SG_ BRAKE_PRESSURE_AXLE_3_LEFT : 39|8@0+ (5,0) [0|1250] "kPa"  CUSTOMER_ECU
 SG_ BRAKE_PRESSURE_AXLE_3_RIGHT : 47|8@0+ (5,0) [0|1250] "kPa"  CUSTOMER_ECU
 SG_ PNEUMATIC_SUPPLY_PRESSURE : 55|8@0+ (5,0) [0|1250] "kPa"  CUSTOMER_ECU

BO_ 1065 TRAILER_BRAKE_PRESSURE_RPT_01: 7 PACMOD
 SG_ BRAKE_PRESSURE_AXLE_1_LEFT : 7|8@0+ (5,0) [0|1250] "kPa"  CUSTOMER_ECU
 SG_ BRAKE_PRESSURE_AXLE_1_RIGHT : 15|8@0+ (5,0) [0|1250] "kPa"  CUSTOMER_ECU
 SG_ BRAKE_PRESSURE_AXLE_2_LEFT : 23|8@0+ (5,0) [0|1250] "kPa"  CUSTOMER_ECU
 SG_ BRAKE_PRESSURE_AXLE_2_RIGHT : 31|8@0+ (5,0) [0|1250] "kPa"  CUSTOMER_ECU
 SG_ BRAKE_PRESSURE_AXLE_3_LEFT : 39|8@0+ (5,0) [0|1250] "kPa"  CUSTOMER_ECU
 SG_ BRAKE_PRESSURE_AXLE_3_RIGHT : 47|8@0+ (5,0) [0|1250] "kPa"  CUSTOMER_ECU
 SG_ PNEUMATIC_SUPPLY_PRESSURE : 55|8@0+ (5,0) [0|1250] "kPa"  CUSTOMER_ECU

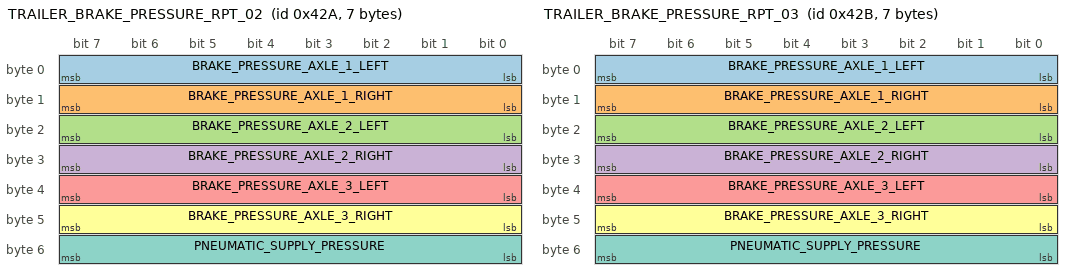
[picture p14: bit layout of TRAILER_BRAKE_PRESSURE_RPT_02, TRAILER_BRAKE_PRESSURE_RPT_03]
BO_ 1066 TRAILER_BRAKE_PRESSURE_RPT_02: 7 PACMOD
 SG_ BRAKE_PRESSURE_AXLE_1_LEFT : 7|8@0+ (5,0) [0|1250] "kPa"  CUSTOMER_ECU
 SG_ BRAKE_PRESSURE_AXLE_1_RIGHT : 15|8@0+ (5,0) [0|1250] "kPa"  CUSTOMER_ECU
 SG_ BRAKE_PRESSURE_AXLE_2_LEFT : 23|8@0+ (5,0) [0|1250] "kPa"  CUSTOMER_ECU
 SG_ BRAKE_PRESSURE_AXLE_2_RIGHT : 31|8@0+ (5,0) [0|1250] "kPa"  CUSTOMER_ECU
 SG_ BRAKE_PRESSURE_AXLE_3_LEFT : 39|8@0+ (5,0) [0|1250] "kPa"  CUSTOMER_ECU
 SG_ BRAKE_PRESSURE_AXLE_3_RIGHT : 47|8@0+ (5,0) [0|1250] "kPa"  CUSTOMER_ECU
 SG_ PNEUMATIC_SUPPLY_PRESSURE : 55|8@0+ (5,0) [0|1250] "kPa"  CUSTOMER_ECU

BO_ 1067 TRAILER_BRAKE_PRESSURE_RPT_03: 7 PACMOD
 SG_ BRAKE_PRESSURE_AXLE_1_LEFT : 7|8@0+ (5,0) [0|1250] "kPa"  CUSTOMER_ECU
 SG_ BRAKE_PRESSURE_AXLE_1_RIGHT : 15|8@0+ (5,0) [0|1250] "kPa"  CUSTOMER_ECU
 SG_ BRAKE_PRESSURE_AXLE_2_LEFT : 23|8@0+ (5,0) [0|1250] "kPa"  CUSTOMER_ECU
 SG_ BRAKE_PRESSURE_AXLE_2_RIGHT : 31|8@0+ (5,0) [0|1250] "kPa"  CUSTOMER_ECU
 SG_ BRAKE_PRESSURE_AXLE_3_LEFT : 39|8@0+ (5,0) [0|1250] "kPa"  CUSTOMER_ECU
 SG_ BRAKE_PRESSURE_AXLE_3_RIGHT : 47|8@0+ (5,0) [0|1250] "kPa"  CUSTOMER_ECU
 SG_ PNEUMATIC_SUPPLY_PRESSURE : 55|8@0+ (5,0) [0|1250] "kPa"  CUSTOMER_ECU

BO_ 1068 TRAILER_BRAKE_PRESSURE_RPT_04: 7 PACMOD
 SG_ BRAKE_PRESSURE_AXLE_1_LEFT : 7|8@0+ (5,0) [0|1250] "kPa"  CUSTOMER_ECU
 SG_ BRAKE_PRESSURE_AXLE_1_RIGHT : 15|8@0+ (5,0) [0|1250] "kPa"  CUSTOMER_ECU
 SG_ BRAKE_PRESSURE_AXLE_2_LEFT : 23|8@0+ (5,0) [0|1250] "kPa"  CUSTOMER_ECU
 SG_ BRAKE_PRESSURE_AXLE_2_RIGHT : 31|8@0+ (5,0) [0|1250] "kPa"  CUSTOMER_ECU
 SG_ BRAKE_PRESSURE_AXLE_3_LEFT : 39|8@0+ (5,0) [0|1250] "kPa"  CUSTOMER_ECU
 SG_ BRAKE_PRESSURE_AXLE_3_RIGHT : 47|8@0+ (5,0) [0|1250] "kPa"  CUSTOMER_ECU
 SG_ PNEUMATIC_SUPPLY_PRESSURE : 55|8@0+ (5,0) [0|1250] "kPa"  CUSTOMER_ECU

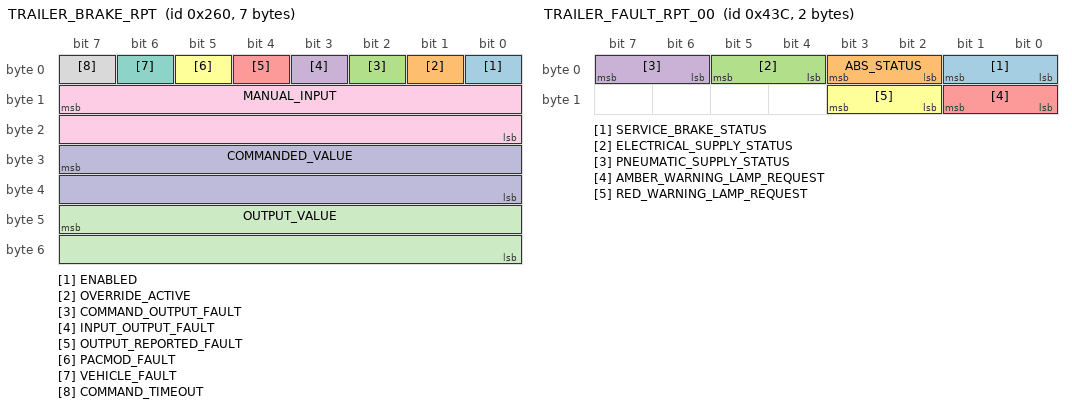
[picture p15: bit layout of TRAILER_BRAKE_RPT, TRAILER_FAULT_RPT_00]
BO_ 608 TRAILER_BRAKE_RPT: 7 PACMOD
 SG_ ENABLED : 0|1@0+ (1,0) [0|1] ""  CUSTOMER_ECU
 SG_ OVERRIDE_ACTIVE : 1|1@0+ (1,0) [0|1] ""  CUSTOMER_ECU
 SG_ COMMAND_OUTPUT_FAULT : 2|1@0+ (1,0) [0|1] ""  CUSTOMER_ECU
 SG_ INPUT_OUTPUT_FAULT : 3|1@0+ (1,0) [0|1] ""  CUSTOMER_ECU
 SG_ OUTPUT_REPORTED_FAULT : 4|1@0+ (1,0) [0|1] ""  CUSTOMER_ECU
 SG_ PACMOD_FAULT : 5|1@0+ (1,0) [0|1] ""  CUSTOMER_ECU
 SG_ VEHICLE_FAULT : 6|1@0+ (1,0) [0|1] ""  CUSTOMER_ECU
 SG_ COMMAND_TIMEOUT : 7|1@0+ (1,0) [0|1] ""  CUSTOMER_ECU
 SG_ MANUAL_INPUT : 15|16@0+ (0.001,0) [0|1] "ratio"  CUSTOMER_ECU
 SG_ COMMANDED_VALUE : 31|16@0+ (0.001,0) [0|1] "ratio"  CUSTOMER_ECU
 SG_ OUTPUT_VALUE : 47|16@0+ (0.001,0) [0|1] "ratio"  CUSTOMER_ECU

BO_ 1084 TRAILER_FAULT_RPT_00: 2 PACMOD
 SG_ SERVICE_BRAKE_STATUS : 1|2@0+ (1,0) [0|3] ""  CUSTOMER_ECU
 SG_ ABS_STATUS : 3|2@0+ (1,0) [0|3] ""  CUSTOMER_ECU
 SG_ ELECTRICAL_SUPPLY_STATUS : 5|2@0+ (1,0) [0|3] ""  CUSTOMER_ECU
 SG_ PNEUMATIC_SUPPLY_STATUS : 7|2@0+ (1,0) [0|3] ""  CUSTOMER_ECU
 SG_ AMBER_WARNING_LAMP_REQUEST : 9|2@0+ (1,0) [0|3] ""  CUSTOMER_ECU
 SG_ RED_WARNING_LAMP_REQUEST : 11|2@0+ (1,0) [0|3] ""  CUSTOMER_ECU

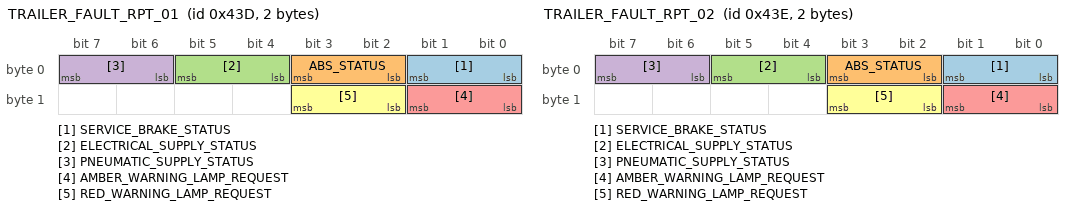
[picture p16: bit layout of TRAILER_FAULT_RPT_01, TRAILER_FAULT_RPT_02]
BO_ 1085 TRAILER_FAULT_RPT_01: 2 PACMOD
 SG_ SERVICE_BRAKE_STATUS : 1|2@0+ (1,0) [0|3] ""  CUSTOMER_ECU
 SG_ ABS_STATUS : 3|2@0+ (1,0) [0|3] ""  CUSTOMER_ECU
 SG_ ELECTRICAL_SUPPLY_STATUS : 5|2@0+ (1,0) [0|3] ""  CUSTOMER_ECU
 SG_ PNEUMATIC_SUPPLY_STATUS : 7|2@0+ (1,0) [0|3] ""  CUSTOMER_ECU
 SG_ AMBER_WARNING_LAMP_REQUEST : 9|2@0+ (1,0) [0|3] ""  CUSTOMER_ECU
 SG_ RED_WARNING_LAMP_REQUEST : 11|2@0+ (1,0) [0|3] ""  CUSTOMER_ECU

BO_ 1086 TRAILER_FAULT_RPT_02: 2 PACMOD
 SG_ SERVICE_BRAKE_STATUS : 1|2@0+ (1,0) [0|3] ""  CUSTOMER_ECU
 SG_ ABS_STATUS : 3|2@0+ (1,0) [0|3] ""  CUSTOMER_ECU
 SG_ ELECTRICAL_SUPPLY_STATUS : 5|2@0+ (1,0) [0|3] ""  CUSTOMER_ECU
 SG_ PNEUMATIC_SUPPLY_STATUS : 7|2@0+ (1,0) [0|3] ""  CUSTOMER_ECU
 SG_ AMBER_WARNING_LAMP_REQUEST : 9|2@0+ (1,0) [0|3] ""  CUSTOMER_ECU
 SG_ RED_WARNING_LAMP_REQUEST : 11|2@0+ (1,0) [0|3] ""  CUSTOMER_ECU

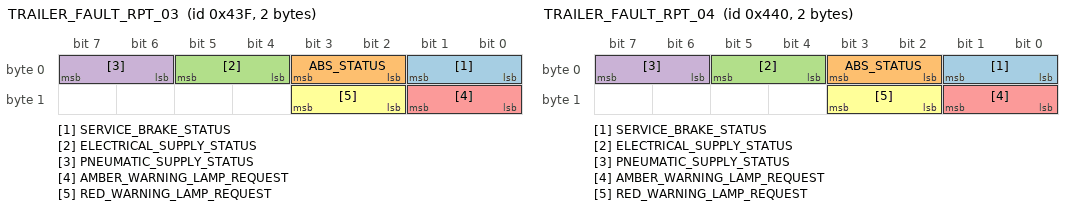
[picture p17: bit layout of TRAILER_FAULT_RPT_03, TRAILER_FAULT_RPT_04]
BO_ 1087 TRAILER_FAULT_RPT_03: 2 PACMOD
 SG_ SERVICE_BRAKE_STATUS : 1|2@0+ (1,0) [0|3] ""  CUSTOMER_ECU
 SG_ ABS_STATUS : 3|2@0+ (1,0) [0|3] ""  CUSTOMER_ECU
 SG_ ELECTRICAL_SUPPLY_STATUS : 5|2@0+ (1,0) [0|3] ""  CUSTOMER_ECU
 SG_ PNEUMATIC_SUPPLY_STATUS : 7|2@0+ (1,0) [0|3] ""  CUSTOMER_ECU
 SG_ AMBER_WARNING_LAMP_REQUEST : 9|2@0+ (1,0) [0|3] ""  CUSTOMER_ECU
 SG_ RED_WARNING_LAMP_REQUEST : 11|2@0+ (1,0) [0|3] ""  CUSTOMER_ECU

BO_ 1088 TRAILER_FAULT_RPT_04: 2 PACMOD
 SG_ SERVICE_BRAKE_STATUS : 1|2@0+ (1,0) [0|3] ""  CUSTOMER_ECU
 SG_ ABS_STATUS : 3|2@0+ (1,0) [0|3] ""  CUSTOMER_ECU
 SG_ ELECTRICAL_SUPPLY_STATUS : 5|2@0+ (1,0) [0|3] ""  CUSTOMER_ECU
 SG_ PNEUMATIC_SUPPLY_STATUS : 7|2@0+ (1,0) [0|3] ""  CUSTOMER_ECU
 SG_ AMBER_WARNING_LAMP_REQUEST : 9|2@0+ (1,0) [0|3] ""  CUSTOMER_ECU
 SG_ RED_WARNING_LAMP_REQUEST : 11|2@0+ (1,0) [0|3] ""  CUSTOMER_ECU

BO_ 1095 TRAILER_IDENTIFIER_RPT_00: 4 PACMOD
 SG_ TRAILER_IDENTIFIER : 7|32@0+ (1,0) [0|4294967295] ""  CUSTOMER_ECU

BO_ 1096 TRAILER_IDENTIFIER_RPT_01: 4 PACMOD
 SG_ TRAILER_IDENTIFIER : 7|32@0+ (1,0) [0|4294967295] ""  CUSTOMER_ECU

BO_ 1097 TRAILER_IDENTIFIER_RPT_02: 4 PACMOD
 SG_ TRAILER_IDENTIFIER : 7|32@0+ (1,0) [0|4294967295] ""  CUSTOMER_ECU

BO_ 1098 TRAILER_IDENTIFIER_RPT_03: 4 PACMOD
 SG_ TRAILER_IDENTIFIER : 7|32@0+ (1,0) [0|4294967295] ""  CUSTOMER_ECU

BO_ 1099 TRAILER_IDENTIFIER_RPT_04: 4 PACMOD
 SG_ TRAILER_IDENTIFIER : 7|32@0+ (1,0) [0|4294967295] ""  CUSTOMER_ECU

BO_ 1106 TRAILER_IDENTIFIER_RPT_05: 4 PACMOD
 SG_ TRAILER_IDENTIFIER : 7|32@0+ (1,0) [0|4294967295] ""  CUSTOMER_ECU

BO_ 1080 TRAILER_PAYLOAD_RPT_02: 8 PACMOD
 SG_ PAYLOAD_00 : 7|16@0- (10,0) [-327680|327610] "Kg"  CUSTOMER_ECU
 SG_ TARE_00 : 23|16@0+ (10,0) [0|655300] "Kg"  CUSTOMER_ECU
 SG_ PAYLOAD_01 : 39|16@0- (10,0) [-327680|327610] "Kg"  CUSTOMER_ECU
 SG_ TARE_01 : 55|16@0+ (10,0) [0|655300] "Kg"  CUSTOMER_ECU

BO_ 1079 TRAILER_PAYLOAD_RPT_01: 8 PACMOD
 SG_ PAYLOAD_00 : 7|16@0- (10,0) [-327680|327610] "Kg"  CUSTOMER_ECU
 SG_ TARE_00 : 23|16@0+ (10,0) [0|655300] "Kg"  CUSTOMER_ECU
 SG_ PAYLOAD_01 : 39|16@0- (10,0) [-327680|327610] "Kg"  CUSTOMER_ECU
 SG_ TARE_01 : 55|16@0+ (10,0) [0|655300] "Kg"  CUSTOMER_ECU

BO_ 1078 TRAILER_PAYLOAD_RPT_00: 8 PACMOD
 SG_ PAYLOAD_00 : 7|16@0- (10,0) [-327680|327610] "Kg"  CUSTOMER_ECU
 SG_ TARE_00 : 23|16@0+ (10,0) [0|655300] "Kg"  CUSTOMER_ECU
 SG_ PAYLOAD_01 : 39|16@0- (10,0) [-327680|327610] "Kg"  CUSTOMER_ECU
 SG_ TARE_01 : 55|16@0+ (10,0) [0|655300] "Kg"  CUSTOMER_ECU

BO_ 1069 TRAILER_WHEEL_SPEED_RPT_00: 4 PACMOD
 SG_ WHEEL_BASED_VEHICLE_SPEED : 7|16@0+ (0.00390625,0) [0|250] "km/h"  CUSTOMER_ECU
 SG_ WHEEL_SPEED_DIFFERENCE_MAIN_AXLE : 23|16@0+ (0.00390625,-125) [-125|125] "km/h"  CUSTOMER_ECU

BO_ 816 TURN_AUX_RPT: 2 PACMOD
 SG_ DRIVER_BLINKER_BULB_ON : 0|1@0+ (1,0) [0|1] ""  CUSTOMER_ECU
 SG_ PASS_BLINKER_BULB_ON : 1|1@0+ (1,0) [0|1] ""  CUSTOMER_ECU
 SG_ DRIVER_BLINKER_BULB_ON_AVAIL : 8|1@0+ (1,0) [0|1] ""  CUSTOMER_ECU
 SG_ PASS_BLINKER_BULB_ON_AVAIL : 9|1@0+ (1,0) [0|1] ""  CUSTOMER_ECU

BO_ 304 TURN_CMD: 2 CUSTOMER_ECU
 SG_ ENABLE : 0|1@0+ (1,0) [0|1] ""  PACMOD
 SG_ IGNORE_OVERRIDES : 1|1@0+ (1,0) [0|1] ""  PACMOD
 SG_ CLEAR_OVERRIDE : 2|1@0+ (1,0) [0|1] ""  PACMOD
 SG_ TURN_SIGNAL_CMD : 15|8@0+ (1,0) [0|3] ""  PACMOD

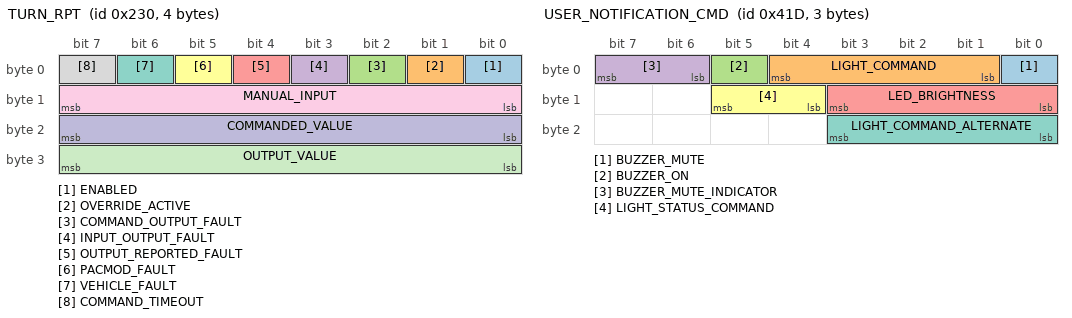
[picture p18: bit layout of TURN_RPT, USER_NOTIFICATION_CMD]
BO_ 560 TURN_RPT: 4 PACMOD
 SG_ ENABLED : 0|1@0+ (1,0) [0|1] ""  CUSTOMER_ECU
 SG_ OVERRIDE_ACTIVE : 1|1@0+ (1,0) [0|1] ""  CUSTOMER_ECU
 SG_ COMMAND_OUTPUT_FAULT : 2|1@0+ (1,0) [0|1] ""  CUSTOMER_ECU
 SG_ INPUT_OUTPUT_FAULT : 3|1@0+ (1,0) [0|1] ""  CUSTOMER_ECU
 SG_ OUTPUT_REPORTED_FAULT : 4|1@0+ (1,0) [0|1] ""  CUSTOMER_ECU
 SG_ PACMOD_FAULT : 5|1@0+ (1,0) [0|1] ""  CUSTOMER_ECU
 SG_ VEHICLE_FAULT : 6|1@0+ (1,0) [0|1] ""  CUSTOMER_ECU
 SG_ COMMAND_TIMEOUT : 7|1@0+ (1,0) [0|1] ""  CUSTOMER_ECU
 SG_ MANUAL_INPUT : 15|8@0+ (1,0) [0|255] ""  CUSTOMER_ECU
 SG_ COMMANDED_VALUE : 23|8@0+ (1,0) [0|255] ""  CUSTOMER_ECU
 SG_ OUTPUT_VALUE : 31|8@0+ (1,0) [0|255] ""  CUSTOMER_ECU

BO_ 1053 USER_NOTIFICATION_CMD: 3 CUSTOMER_ECU
 SG_ BUZZER_MUTE : 0|1@0+ (1,0) [0|1] ""  PACMOD
 SG_ LIGHT_COMMAND : 4|4@0+ (1,0) [0|10] ""  PACMOD
 SG_ BUZZER_ON : 5|1@0+ (1,0) [0|1] "" PACMOD
 SG_ BUZZER_MUTE_INDICATOR : 7|2@0+ (1,0) [0|3] "" PACMOD
 SG_ LED_BRIGHTNESS : 11|4@0+ (1,0) [0|15] "" PACMOD
 SG_ LIGHT_STATUS_COMMAND : 13|2@0+ (1,0) [0|3] ""  PACMOD
 SG_ LIGHT_COMMAND_ALTERNATE : 19|4@0+ (1,0) [0|10] ""  PACMOD

BO_ 37 USER_PC_HEALTH_RPT_00: 3 CUSTOMER_ECU
 SG_ COUNTER : 7|8@0+ (1,0) [0|255] ""  PACMOD
 SG_ CHECKSUM : 15|8@0+ (1,0) [0|255] ""  PACMOD
 SG_ USER_PC_APPLICATION_FAULT : 16|1@0+ (1,0) [0|1] ""  PACMOD

BO_ 38 USER_PC_HEALTH_RPT_01: 3 CUSTOMER_ECU
 SG_ COUNTER : 7|8@0+ (1,0) [0|255] ""  PACMOD
 SG_ CHECKSUM : 15|8@0+ (1,0) [0|255] ""  PACMOD
 SG_ USER_PC_APPLICATION_FAULT : 16|1@0+ (1,0) [0|1] ""  PACMOD

BO_ 1043 VEH_DYNAMICS_RPT: 1 PACMOD
 SG_ VEH_G_FORCES : 7|8@0+ (0.001,0) [-32.768|32.767] "m/s^2"  CUSTOMER_ECU

BO_ 66 VEHICLE_FAULT_RPT: 4  PACMOD
 SG_ ENGINE_CHECK_LIGHT : 0|1@0+ (1,0) [0|1] ""  CUSTOMER_ECU
 SG_ ENGINE_CHECK_LIGHT_AVAIL : 1|1@0+ (1,0) [0|1] ""  CUSTOMER_ECU
 SG_ TRC_FAULT_LIGHT : 2|1@0+ (1,0) [0|1] ""  CUSTOMER_ECU
 SG_ TRC_FAULT_LIGHT_AVAIL : 3|1@0+ (1,0) [0|1] ""  CUSTOMER_ECU
 SG_ TRC_OFF_FAULT_LIGHT : 4|1@0+ (1,0) [0|1] ""  CUSTOMER_ECU
 SG_ TRC_OFF_FAULT_LIGHT_AVAIL : 5|1@0+ (1,0) [0|1] ""  CUSTOMER_ECU
 SG_ ANTILOCK_BRAKE_FAULT_LIGHT : 6|1@0+ (1,0) [0|1] ""  CUSTOMER_ECU
 SG_ ANTILOCK_BRAKE_FAULT_LIGHT_AVAIL : 7|1@0+ (1,0) [0|1] ""  CUSTOMER_ECU
 SG_ TIRE_FAULT_LIGHT : 8|1@0+ (1,0) [0|1] ""  CUSTOMER_ECU
 SG_ TIRE_FAULT_LIGHT_AVAIL : 9|1@0+ (1,0) [0|1] ""  CUSTOMER_ECU
 SG_ AIR_BAGS_FAULT_LIGHT : 10|1@0+ (1,0) [0|1] ""  CUSTOMER_ECU
 SG_ AIR_BAGS_FAULT_LIGHT_AVAIL : 11|1@0+ (1,0) [0|1] ""  CUSTOMER_ECU
 SG_ LOW_ENGINE_OIL_PRESSURE : 12|1@0+ (1,0) [0|1] ""  CUSTOMER_ECU
 SG_ LOW_ENGINE_OIL_PRESSURE_AVAIL : 13|1@0+ (1,0) [0|1] ""  CUSTOMER_ECU
 SG_ BRAKE_FAULT : 14|1@0+ (1,0) [0|1] ""  CUSTOMER_ECU
 SG_ BRAKE_FAULT_AVAIL : 15|1@0+ (1,0) [0|1] ""  CUSTOMER_ECU
 SG_ BRK_APPLIED_POWER_REDUCED : 16|1@0+ (1,0) [0|1] ""  CUSTOMER_ECU
 SG_ BRK_APPLIED_POWER_REDUCED_AVAIL : 17|1@0+ (1,0) [0|1] ""  CUSTOMER_ECU
 SG_ STEERING_LOSS_STOP_SAFELY : 18|1@0+ (1,0) [0|1] ""  CUSTOMER_ECU
 SG_ STEERING_LOSS_STOP_SAFELY_AVAIL : 19|1@0+ (1,0) [0|1] ""  CUSTOMER_ECU
 SG_ STEERING_FAULT_SERVICE_NOW : 20|1@0+ (1,0) [0|1] ""  CUSTOMER_ECU
 SG_ STEERING_FAULT_SERVICE_NOW_AVAIL : 21|1@0+ (1,0) [0|1] ""  CUSTOMER_ECU
 SG_ XMSN_FAULT_SERVICE_NOW : 22|1@0+ (1,0) [0|1] ""  CUSTOMER_ECU
 SG_ XMSN_FAULT_SERVICE_NOW_AVAIL : 23|1@0+ (1,0) [0|1] ""  CUSTOMER_ECU
 SG_ XMSN_OVER_TEMP_STOP_SAFELY : 24|1@0+ (1,0) [0|1] ""  CUSTOMER_ECU
 SG_ XMSN_OVER_TEMP_STOP_SAFELY_AVAIL : 25|1@0+ (1,0) [0|1] ""  CUSTOMER_ECU
 SG_ LOW_BATTERY_FEATURES_OFF : 26|1@0+ (1,0) [0|1] ""  CUSTOMER_ECU
 SG_ LOW_BATTERY_FEATURES_OFF_AVAIL : 27|1@0+ (1,0) [0|1] ""  CUSTOMER_ECU
 SG_ CHARGING_SYSTEM_FAULT : 28|1@0+ (1,0) [0|1] ""  CUSTOMER_ECU
 SG_ CHARGING_SYSTEM_FAULT_AVAIL : 29|1@0+ (1,0) [0|1] ""  CUSTOMER_ECU

BO_ 1083 VEHICLE_FAULT_RPT_2: 5 PACMOD
 SG_ BRAKES_AMBER_LAMP : 1|2@0+ (1,0) [0|3] ""  CUSTOMER_ECU
 SG_ BRAKES_RED_LAMP : 3|2@0+ (1,0) [0|3] ""  CUSTOMER_ECU
 SG_ CHASSIS_AMBER_LAMP : 5|2@0+ (1,0) [0|3] ""  CUSTOMER_ECU
 SG_ CHASSIS_RED_LAMP : 7|2@0+ (1,0) [0|3] ""  CUSTOMER_ECU
 SG_ ELECTRONIC_BRAKES_AMBER_LAMP : 9|2@0+ (1,0) [0|3] ""  CUSTOMER_ECU
 SG_ ELECTRONIC_BRAKES_RED_LAMP : 11|2@0+ (1,0) [0|3] ""  CUSTOMER_ECU
 SG_ ENGINE_AMBER_LAMP : 13|2@0+ (1,0) [0|3] ""  CUSTOMER_ECU
 SG_ ENGINE_RED_LAMP : 15|2@0+ (1,0) [0|3] ""  CUSTOMER_ECU
 SG_ ENGINE_BRAKE_AMBER_LAMP : 17|2@0+ (1,0) [0|3] ""  CUSTOMER_ECU
 SG_ ENGINE_BRAKE_RED_LAMP : 19|2@0+ (1,0) [0|3] ""  CUSTOMER_ECU
 SG_ MANAGEMENT_ECU_AMBER_LAMP : 21|2@0+ (1,0) [0|3] ""  CUSTOMER_ECU
 SG_ MANAGEMENT_ECU_RED_LAMP : 23|2@0+ (1,0) [0|3] ""  CUSTOMER_ECU
 SG_ PNEUMATIC_AMBER_LAMP : 25|2@0+ (1,0) [0|3] ""  CUSTOMER_ECU
 SG_ PNEUMATIC_RED_LAMP : 27|2@0+ (1,0) [0|3] ""  CUSTOMER_ECU
 SG_ RESTRAINTS_AMBER_LAMP : 29|2@0+ (1,0) [0|3] ""  CUSTOMER_ECU
 SG_ RESTRAINTS_RED_LAMP : 31|2@0+ (1,0) [0|3] ""  CUSTOMER_ECU
 SG_ TRAILER_ABS_AMBER_LAMP : 33|2@0+ (1,0) [0|3] ""  CUSTOMER_ECU
 SG_ TRAILER_ABS_RED_LAMP : 35|2@0+ (1,0) [0|3] ""  CUSTOMER_ECU
 SG_ TRANSMISSION_AMBER_LAMP : 37|2@0+ (1,0) [0|3] ""  CUSTOMER_ECU
 SG_ TRANSMISSION_RED_LAMP : 39|2@0+ (1,0) [0|3] ""  CUSTOMER_ECU

BO_ 1024 VEHICLE_SPEED_RPT: 2 PACMOD
 SG_ VEHICLE_SPEED : 7|16@0- (0.01,0) [-327.68|327.62] "m/s"  CUSTOMER_ECU

BO_ 1044 VIN_RPT: 7 PACMOD
 SG_ VEH_MFG_CODE : 7|24@0+ (1,0) [0|0] ""  CUSTOMER_ECU
 SG_ VEH_MY_CODE : 31|8@0+ (1,0) [0|0] ""  CUSTOMER_ECU
 SG_ VEH_SERIAL : 39|24@0+ (1,0) [0|0] ""  CUSTOMER_ECU

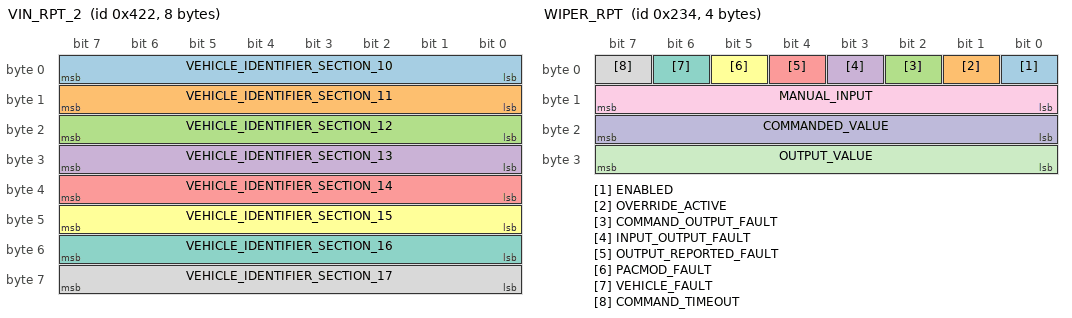
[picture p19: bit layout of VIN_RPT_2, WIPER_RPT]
BO_ 1058 VIN_RPT_2: 8 PACMOD
 SG_ VEHICLE_IDENTIFIER_SECTION_10 : 7|8@0+ (1,0) [0|255] "ASCII"  CUSTOMER_ECU
 SG_ VEHICLE_IDENTIFIER_SECTION_11 : 15|8@0+ (1,0) [0|255] "ASCII"  CUSTOMER_ECU
 SG_ VEHICLE_IDENTIFIER_SECTION_12 : 23|8@0+ (1,0) [0|255] "ASCII"  CUSTOMER_ECU
 SG_ VEHICLE_IDENTIFIER_SECTION_13 : 31|8@0+ (1,0) [0|255] "ASCII"  CUSTOMER_ECU
 SG_ VEHICLE_IDENTIFIER_SECTION_14 : 39|8@0+ (1,0) [0|255] "ASCII"  CUSTOMER_ECU
 SG_ VEHICLE_IDENTIFIER_SECTION_15 : 47|8@0+ (1,0) [0|255] "ASCII"  CUSTOMER_ECU
 SG_ VEHICLE_IDENTIFIER_SECTION_16 : 55|8@0+ (1,0) [0|255] "ASCII"  CUSTOMER_ECU
 SG_ VEHICLE_IDENTIFIER_SECTION_17 : 63|8@0+ (1,0) [0|255] "ASCII"  CUSTOMER_ECU

BO_ 1536 WATCHDOG_RPT: 8 PACMOD
 SG_ GLOBAL_ENABLE_FLAG : 0|1@0+ (1,0) [0|1] ""  CUSTOMER_ECU
 SG_ GLOBAL_OVERRIDE_ACTIVE : 1|1@0+ (1,0) [0|1] ""  CUSTOMER_ECU
 SG_ GLOBAL_COMMAND_TIMEOUT_ERROR : 2|1@0+ (1,0) [0|1] ""  CUSTOMER_ECU
 SG_ GLOBAL_PACMOD_SUBSYSTEM_TIMEOUT : 3|1@0+ (1,0) [0|1] ""  CUSTOMER_ECU
 SG_ GLOBAL_VEHICLE_CAN_TIMEOUT : 4|1@0+ (1,0) [0|1] ""  CUSTOMER_ECU
 SG_ GLOBAL_PACMOD_SYS_FAULT_ACTIVE : 5|1@0+ (1,0) [0|1] ""  CUSTOMER_ECU
 SG_ GLOBAL_CONFIG_FAULT_ACTIVE : 6|1@0+ (1,0) [0|1] ""  CUSTOMER_ECU
 SG_ GLOBAL_TIMEOUT : 7|1@0+ (1,0) [0|1] ""  CUSTOMER_ECU
 SG_ ACCEL_ENABLED : 8|1@0+ (1,0) [0|1] ""  CUSTOMER_ECU
 SG_ ACCEL_OVERRIDE_ACTIVE : 9|1@0+ (1,0) [0|1] ""  CUSTOMER_ECU
 SG_ ACCEL_COMMAND_OUTPUT_FAULT : 10|1@0+ (1,0) [0|1] ""  CUSTOMER_ECU
 SG_ ACCEL_INPUT_OUTPUT_FAULT : 11|1@0+ (1,0) [0|1] ""  CUSTOMER_ECU
 SG_ ACCEL_OUTPUT_REPORTED_FAULT : 12|1@0+ (1,0) [0|1] ""  CUSTOMER_ECU
 SG_ ACCEL_PACMOD_FAULT : 13|1@0+ (1,0) [0|1] ""  CUSTOMER_ECU
 SG_ ACCEL_VEHICLE_FAULT : 14|1@0+ (1,0) [0|1] ""  CUSTOMER_ECU
 SG_ ACCEL_TIMEOUT : 15|1@0+ (1,0) [0|1] ""  CUSTOMER_ECU
 SG_ BRAKE_ENABLED : 16|1@0+ (1,0) [0|1] ""  CUSTOMER_ECU
 SG_ BRAKE_OVERRIDE_ACTIVE : 17|1@0+ (1,0) [0|1] ""  CUSTOMER_ECU
 SG_ BRAKE_COMMAND_OUTPUT_FAULT : 18|1@0+ (1,0) [0|1] ""  CUSTOMER_ECU
 SG_ BRAKE_INPUT_OUTPUT_FAULT : 19|1@0+ (1,0) [0|1] ""  CUSTOMER_ECU
 SG_ BRAKE_OUTPUT_REPORTED_FAULT : 20|1@0+ (1,0) [0|1] ""  CUSTOMER_ECU
 SG_ BRAKE_PACMOD_FAULT : 21|1@0+ (1,0) [0|1] ""  CUSTOMER_ECU
 SG_ BRAKE_VEHICLE_FAULT : 22|1@0+ (1,0) [0|1] ""  CUSTOMER_ECU
 SG_ BRAKE_TIMEOUT : 23|1@0+ (1,0) [0|1] ""  CUSTOMER_ECU
 SG_ SHIFT_ENABLED : 24|1@0+ (1,0) [0|1] ""  CUSTOMER_ECU
 SG_ SHIFT_OVERRIDE_ACTIVE : 25|1@0+ (1,0) [0|1] ""  CUSTOMER_ECU
 SG_ SHIFT_COMMAND_OUTPUT_FAULT : 26|1@0+ (1,0) [0|1] ""  CUSTOMER_ECU
 SG_ SHIFT_INPUT_OUTPUT_FAULT : 27|1@0+ (1,0) [0|1] ""  CUSTOMER_ECU
 SG_ SHIFT_OUTPUT_REPORTED_FAULT : 28|1@0+ (1,0) [0|1] ""  CUSTOMER_ECU
 SG_ SHIFT_PACMOD_FAULT : 29|1@0+ (1,0) [0|1] ""  CUSTOMER_ECU
 SG_ SHIFT_VEHICLE_FAULT : 30|1@0+ (1,0) [0|1] ""  CUSTOMER_ECU
 SG_ SHIFT_TIMEOUT : 31|1@0+ (1,0) [0|1] ""  CUSTOMER_ECU
 SG_ STEER_ENABLED : 32|1@0+ (1,0) [0|1] ""  CUSTOMER_ECU
 SG_ STEER_OVERRIDE_ACTIVE : 33|1@0+ (1,0) [0|1] ""  CUSTOMER_ECU
 SG_ STEER_COMMAND_OUTPUT_FAULT : 34|1@0+ (1,0) [0|1] ""  CUSTOMER_ECU
 SG_ STEER_INPUT_OUTPUT_FAULT : 35|1@0+ (1,0) [0|1] ""  CUSTOMER_ECU
 SG_ STEER_OUTPUT_REPORTED_FAULT : 36|1@0+ (1,0) [0|1] ""  CUSTOMER_ECU
 SG_ STEER_PACMOD_FAULT : 37|1@0+ (1,0) [0|1] ""  CUSTOMER_ECU
 SG_ STEER_VEHICLE_FAULT : 38|1@0+ (1,0) [0|1] ""  CUSTOMER_ECU
 SG_ STEER_TIMEOUT : 39|1@0+ (1,0) [0|1] ""  CUSTOMER_ECU
 SG_ PACMOD1_CONFIG_FAULT : 40|1@0+ (1,0) [0|1] ""  CUSTOMER_ECU
 SG_ PACMOD1_CAN_TIMEOUT : 41|1@0+ (1,0) [0|1] ""  CUSTOMER_ECU
 SG_ PACMOD1_COUNTER_FAULT : 42|1@0+ (1,0) [0|1] ""  CUSTOMER_ECU
 SG_ PACMOD2_CONFIG_FAULT : 43|1@0+ (1,0) [0|1] ""  CUSTOMER_ECU
 SG_ PACMOD2_CAN_TIMEOUT : 44|1@0+ (1,0) [0|1] ""  CUSTOMER_ECU
 SG_ PACMOD2_COUNTER_FAULT : 45|1@0+ (1,0) [0|1] ""  CUSTOMER_ECU
 SG_ PACMOD3_CONFIG_FAULT : 46|1@0+ (1,0) [0|1] ""  CUSTOMER_ECU
 SG_ PACMOD3_CAN_TIMEOUT : 47|1@0+ (1,0) [0|1] ""  CUSTOMER_ECU
 SG_ PACMOD3_COUNTER_FAULT : 48|1@0+ (1,0) [0|1] ""  CUSTOMER_ECU
 SG_ PACMINI1_RPT_TIMEOUT : 49|1@0+ (1,0) [0|1] ""  CUSTOMER_ECU
 SG_ PACMINI1_CONFIG_FAULT : 50|1@0+ (1,0) [0|1] ""  CUSTOMER_ECU
 SG_ PACMINI1_CAN_TIMEOUT : 51|1@0+ (1,0) [0|1] ""  CUSTOMER_ECU
 SG_ PACMINI1_COUNTER_FAULT : 52|1@0+ (1,0) [0|1] ""  CUSTOMER_ECU
 SG_ PACMINI2_RPT_TIMEOUT : 53|1@0+ (1,0) [0|1] ""  CUSTOMER_ECU
 SG_ PACMINI2_CONFIG_FAULT : 54|1@0+ (1,0) [0|1] ""  CUSTOMER_ECU
 SG_ PACMINI2_CAN_TIMEOUT : 55|1@0+ (1,0) [0|1] ""  CUSTOMER_ECU
 SG_ PACMINI2_COUNTER_FAULT : 56|1@0+ (1,0) [0|1] ""  CUSTOMER_ECU
 SG_ PACMINI3_RPT_TIMEOUT : 57|1@0+ (1,0) [0|1] ""  CUSTOMER_ECU
 SG_ PACMINI3_CONFIG_FAULT : 58|1@0+ (1,0) [0|1] ""  CUSTOMER_ECU
 SG_ PACMINI3_CAN_TIMEOUT : 59|1@0+ (1,0) [0|1] ""  CUSTOMER_ECU
 SG_ PACMINI3_COUNTER_FAULT : 60|1@0+ (1,0) [0|1] ""  CUSTOMER_ECU
 SG_ PACMOD_SYSTEM_PRESENT_FAULT : 61|1@0+ (1,0) [0|1] ""  CUSTOMER_ECU
 SG_ PACMINI_SYSTEM_PRESENT_FAULT : 62|1@0+ (1,0) [0|1] ""  CUSTOMER_ECU
 SG_ GLOBAL_INT_POWER_SUPPLY_FAULT : 63|1@0+ (1,0) [0|1] ""  CUSTOMER_ECU

BO_ 1057 WATCHDOG_RPT_2: 7  PACMOD
 SG_ ACCEL_RPT_TIMEOUT : 0|1@0+ (1,0) [0|1] ""  CUSTOMER_ECU
 SG_ BRAKE_RPT_TIMEOUT : 1|1@0+ (1,0) [0|1] ""  CUSTOMER_ECU
 SG_ BRAKE_DECEL_RPT_TIMEOUT : 2|1@0+ (1,0) [0|1] ""  CUSTOMER_ECU
 SG_ CABIN_CLIMATE_RPT_TIMEOUT : 3|1@0+ (1,0) [0|1] ""  CUSTOMER_ECU
 SG_ CABIN_FAN_SPEED_RPT_TIMEOUT : 4|1@0+ (1,0) [0|1] ""  CUSTOMER_ECU
 SG_ CABIN_TEMP_RPT_TIMEOUT : 5|1@0+ (1,0) [0|1] ""  CUSTOMER_ECU
 SG_ CRUISE_CONTROL_RPT_TIMEOUT : 6|1@0+ (1,0) [0|1] ""  CUSTOMER_ECU
 SG_ DASH_LEFT_RPT_TIMEOUT : 7|1@0+ (1,0) [0|1] ""  CUSTOMER_ECU
 SG_ DASH_RIGHT_RPT_TIMEOUT : 8|1@0+ (1,0) [0|1] ""  CUSTOMER_ECU
 SG_ ENGINE_BRAKE_RPT_TIMEOUT : 9|1@0+ (1,0) [0|1] ""  CUSTOMER_ECU
 SG_ HAZARD_LIGHTS_RPT_TIMEOUT : 10|1@0+ (1,0) [0|1] ""  CUSTOMER_ECU
 SG_ HEADLIGHT_RPT_TIMEOUT : 11|1@0+ (1,0) [0|1] ""  CUSTOMER_ECU
 SG_ HORN_RPT_TIMEOUT : 12|1@0+ (1,0) [0|1] ""  CUSTOMER_ECU
 SG_ MARKER_LAMP_RPT_TIMEOUT : 13|1@0+ (1,0) [0|1] ""  CUSTOMER_ECU
 SG_ MEDIA_CONTROLS_RPT_TIMEOUT : 14|1@0+ (1,0) [0|1] ""  CUSTOMER_ECU
 SG_ PARKING_BRAKE_RPT_TIMEOUT : 15|1@0+ (1,0) [0|1] ""  CUSTOMER_ECU
 SG_ REAR_PASS_DOOR_RPT_TIMEOUT : 16|1@0+ (1,0) [0|1] ""  CUSTOMER_ECU
 SG_ SHIFT_RPT_TIMEOUT : 17|1@0+ (1,0) [0|1] ""  CUSTOMER_ECU
 SG_ SPRAYER_RPT_TIMEOUT : 18|1@0+ (1,0) [0|1] ""  CUSTOMER_ECU
 SG_ STEERING_RPT_TIMEOUT : 19|1@0+ (1,0) [0|1] ""  CUSTOMER_ECU
 SG_ TURN_RPT_TIMEOUT : 20|1@0+ (1,0) [0|1] ""  CUSTOMER_ECU
 SG_ WIPER_RPT_TIMEOUT : 21|1@0+ (1,0) [0|1] ""  CUSTOMER_ECU
 SG_ PACMOD1_SANITY_FAULT : 22|1@0+ (1,0) [0|1] ""  CUSTOMER_ECU
 SG_ PACMOD2_SANITY_FAULT : 23|1@0+ (1,0) [0|1] ""  CUSTOMER_ECU
 SG_ PACMOD3_SANITY_FAULT : 24|1@0+ (1,0) [0|1] ""  CUSTOMER_ECU
 SG_ PACMINI1_SANITY_FAULT : 25|1@0+ (1,0) [0|1] ""  CUSTOMER_ECU
 SG_ PACMINI2_SANITY_FAULT : 26|1@0+ (1,0) [0|1] ""  CUSTOMER_ECU
 SG_ PACMINI3_SANITY_FAULT : 27|1@0+ (1,0) [0|1] ""  CUSTOMER_ECU
 SG_ PACMOD1_COMPONENT_RPT_TIMEOUT : 28|1@0+ (1,0) [0|1] ""  CUSTOMER_ECU
 SG_ PACMOD2_COMPONENT_RPT_TIMEOUT : 29|1@0+ (1,0) [0|1] ""  CUSTOMER_ECU
 SG_ PACMOD3_COMPONENT_RPT_TIMEOUT : 30|1@0+ (1,0) [0|1] ""  CUSTOMER_ECU
 SG_ PACMINI1_COMPONENT_RPT_TIMEOUT : 31|1@0+ (1,0) [0|1] ""  CUSTOMER_ECU
 SG_ PACMINI2_COMPONENT_RPT_TIMEOUT : 32|1@0+ (1,0) [0|1] ""  CUSTOMER_ECU
 SG_ PACMINI3_COMPONENT_RPT_TIMEOUT : 33|1@0+ (1,0) [0|1] ""  CUSTOMER_ECU
 SG_ PACMOD1_SYSTEM_PRESENT_FAULT : 34|1@0+ (1,0) [0|1] ""  CUSTOMER_ECU
 SG_ PACMOD2_SYSTEM_PRESENT_FAULT : 35|1@0+ (1,0) [0|1] ""  CUSTOMER_ECU
 SG_ PACMOD3_SYSTEM_PRESENT_FAULT : 36|1@0+ (1,0) [0|1] ""  CUSTOMER_ECU
 SG_ PACMINI1_SYSTEM_PRESENT_FAULT : 37|1@0+ (1,0) [0|1] ""  CUSTOMER_ECU
 SG_ PACMINI2_SYSTEM_PRESENT_FAULT : 38|1@0+ (1,0) [0|1] ""  CUSTOMER_ECU
 SG_ PACMINI3_SYSTEM_PRESENT_FAULT : 39|1@0+ (1,0) [0|1] ""  CUSTOMER_ECU
 SG_ DRIVE_MODE_INVALID : 40|1@0+ (1,0) [0|1] ""  CUSTOMER_ECU
 SG_ GLOBAL_CMD_SANITY_FAULT : 41|1@0+ (1,0) [0|1] ""  CUSTOMER_ECU
 SG_ GLOBAL_CMD_TIMEOUT : 42|1@0+ (1,0) [0|1] ""  CUSTOMER_ECU
 SG_ EXHAUST_BRAKE_RPT_TIMEOUT : 43|1@0+ (1,0) [0|1] ""  CUSTOMER_ECU
 SG_ POWER_TAKE_OFF_RPT_TIMEOUT : 44|1@0+ (1,0) [0|1] ""  CUSTOMER_ECU
 SG_ TIPPER_BODY_00_RPT_TIMEOUT : 45|1@0+ (1,0) [0|1] ""  CUSTOMER_ECU
 SG_ TRAILER_AIR_SUPPLY_RPT_TIMEOUT : 46|1@0+ (1,0) [0|1] ""  CUSTOMER_ECU
 SG_ TRAILER_BRAKE_RPT_TIMEOUT : 47|1@0+ (1,0) [0|1] ""  CUSTOMER_ECU
 SG_ ENGINE_RPT_TIMEOUT : 48|1@0+ (1,0) [0|1] ""  CUSTOMER_ECU
 SG_ TIPPER_BODY_01_RPT_TIMEOUT : 49|1@0+ (1,0) [0|1] ""  CUSTOMER_ECU
 SG_ TIPPER_BODY_02_RPT_TIMEOUT : 50|1@0+ (1,0) [0|1] ""  CUSTOMER_ECU
 SG_ DIFFERENTIAL_LOCKS_RPT_TIMEOUT : 51|1@0+ (1,0) [0|1] ""  CUSTOMER_ECU

BO_ 1031 WHEEL_SPEED_RPT: 8 PACMOD
 SG_ WHEEL_SPD_AXLE_1_LEFT : 7|16@0- (0.01,0) [-327.68|327.62] "rad/s"  CUSTOMER_ECU
 SG_ WHEEL_SPD_AXLE_1_RIGHT : 23|16@0- (0.01,0) [-327.68|327.62] "rad/s"  CUSTOMER_ECU
 SG_ WHEEL_SPD_AXLE_2_LEFT : 39|16@0- (0.01,0) [-327.68|327.62] "rad/s"  CUSTOMER_ECU
 SG_ WHEEL_SPD_AXLE_2_RIGHT : 55|16@0- (0.01,0) [-327.68|327.62] "rad/s"  CUSTOMER_ECU

BO_ 1062 WHEEL_SPEED_RPT_2: 8 PACMOD
 SG_ WHEEL_SPD_AXLE_3_LEFT : 7|16@0- (0.01,0) [-327.68|327.62] "rad/s"  CUSTOMER_ECU
 SG_ WHEEL_SPD_AXLE_3_RIGHT : 23|16@0- (0.01,0) [-327.68|327.62] "rad/s"  CUSTOMER_ECU
 SG_ WHEEL_SPD_AXLE_4_LEFT : 39|16@0- (0.01,0) [-327.68|327.62] "rad/s"  CUSTOMER_ECU
 SG_ WHEEL_SPD_AXLE_4_RIGHT : 55|16@0- (0.01,0) [-327.68|327.62] "rad/s"  CUSTOMER_ECU

BO_ 820 WIPER_AUX_RPT: 1 PACMOD
 SG_ FRONT_WIPING : 1|2@0+ (1,0) [0|3] ""  CUSTOMER_ECU
 SG_ REAR_WIPING : 3|2@0+ (1,0) [0|3] ""  CUSTOMER_ECU

BO_ 308 WIPER_CMD: 2 CUSTOMER_ECU
 SG_ ENABLE : 0|1@0+ (1,0) [0|1] ""  PACMOD
 SG_ IGNORE_OVERRIDES : 1|1@0+ (1,0) [0|1] ""  PACMOD
 SG_ CLEAR_OVERRIDE : 2|1@0+ (1,0) [0|1] ""  PACMOD
 SG_ WIPER_CMD : 15|8@0+ (1,0) [0|255] ""  PACMOD

BO_ 564 WIPER_RPT: 4 PACMOD
 SG_ ENABLED : 0|1@0+ (1,0) [0|1] ""  CUSTOMER_ECU
 SG_ OVERRIDE_ACTIVE : 1|1@0+ (1,0) [0|1] ""  CUSTOMER_ECU
 SG_ COMMAND_OUTPUT_FAULT : 2|1@0+ (1,0) [0|1] ""  CUSTOMER_ECU
 SG_ INPUT_OUTPUT_FAULT : 3|1@0+ (1,0) [0|1] ""  CUSTOMER_ECU
 SG_ OUTPUT_REPORTED_FAULT : 4|1@0+ (1,0) [0|1] ""  CUSTOMER_ECU
 SG_ PACMOD_FAULT : 5|1@0+ (1,0) [0|1] ""  CUSTOMER_ECU
 SG_ VEHICLE_FAULT : 6|1@0+ (1,0) [0|1] ""  CUSTOMER_ECU
 SG_ COMMAND_TIMEOUT : 7|1@0+ (1,0) [0|1] ""  CUSTOMER_ECU
 SG_ MANUAL_INPUT : 15|8@0+ (1,0) [0|255] ""  CUSTOMER_ECU
 SG_ COMMANDED_VALUE : 23|8@0+ (1,0) [0|255] ""  CUSTOMER_ECU
 SG_ OUTPUT_VALUE : 31|8@0+ (1,0) [0|255] ""  CUSTOMER_ECU

// TIPPER_BODY_AUX_RPT_00 MESSAGE COMMENT
CM_ BO_ 856 "Trailer number increments from the front most trailer and is indicated by the report index.";

// TIPPER_BODY_AUX_RPT_01 MESSAGE COMMENT
CM_ BO_ 876 "Trailer number increments from the front most trailer and is indicated by the report index.";

// TIPPER_BODY_AUX_RPT_02 MESSAGE COMMENT
CM_ BO_ 880 "Trailer number increments from the front most trailer and is indicated by the report index.";

// TRAILER_BRAKE_PRESSURE_RPT_00 MESSAGE COMMENT
CM_ BO_ 1064 "Chassis number increments from the front most trailer and is indicated by the report index.";

// TRAILER_BRAKE_PRESSURE_RPT_01 MESSAGE COMMENT
CM_ BO_ 1065 "Chassis number increments from the front most trailer and is indicated by the report index.";

// TRAILER_BRAKE_PRESSURE_RPT_02 MESSAGE COMMENT
CM_ BO_ 1066 "Chassis number increments from the front most trailer and is indicated by the report index.";

// TRAILER_BRAKE_PRESSURE_RPT_03 MESSAGE COMMENT
CM_ BO_ 1067 "Chassis number increments from the front most trailer and is indicated by the report index.";

// TRAILER_BRAKE_PRESSURE_RPT_04 MESSAGE COMMENT
CM_ BO_ 1068 "Chassis number increments from the front most trailer and is indicated by the report index.";

// TRAILER_FAULT_RPT_00 MESSAGE COMMENT
CM_ BO_ 1084 "Chassis number increments from the front most trailer and is indicated by the report index.";

// TRAILER_FAULT_RPT_01 MESSAGE COMMENT
CM_ BO_ 1085 "Chassis number increments from the front most trailer and is indicated by the report index.";

// TRAILER_FAULT_RPT_02 MESSAGE COMMENT
CM_ BO_ 1086 "Chassis number increments from the front most trailer and is indicated by the report index.";

// TRAILER_FAULT_RPT_03 MESSAGE COMMENT
CM_ BO_ 1087 "Chassis number increments from the front most trailer and is indicated by the report index.";

// TRAILER_FAULT_RPT_04 MESSAGE COMMENT
CM_ BO_ 1088 "Chassis number increments from the front most trailer and is indicated by the report index.";

// TRAILER_IDENTIFIER_RPT_00 MESSAGE COMMENT
CM_ BO_ 1095 "Chassis number increments from the front most trailer (including prime mover) and is indicated by the report index.";

// TRAILER_IDENTIFIER_RPT_01 MESSAGE COMMENT
CM_ BO_ 1096 "Chassis number increments from the front most trailer (including prime mover) and is indicated by the report index.";

// TRAILER_IDENTIFIER_RPT_02 MESSAGE COMMENT
CM_ BO_ 1097 "Chassis number increments from the front most trailer (including prime mover) and is indicated by the report index.";

// TRAILER_IDENTIFIER_RPT_03 MESSAGE COMMENT
CM_ BO_ 1098 "Chassis number increments from the front most trailer (including prime mover) and is indicated by the report index.";

// TRAILER_IDENTIFIER_RPT_04 MESSAGE COMMENT
CM_ BO_ 1099 "Chassis number increments from the front most trailer (including prime mover) and is indicated by the report index.";

// TRAILER_IDENTIFIER_RPT_05 MESSAGE COMMENT
CM_ BO_ 1106 "Chassis number increments from the front most trailer (including prime mover) and is indicated by the report index.";

// TRAILER_PAYLOAD_RPT_00 MESSAGE COMMENT
CM_ BO_ 1078 "Tipper body number increments from the front most trailer and is indicated by the report index.";

// TRAILER_PAYLOAD_RPT_01 MESSAGE COMMENT
CM_ BO_ 1079 "Tipper body number increments from the front most trailer and is indicated by the report index.";

// TRAILER_PAYLOAD_RPT_02 MESSAGE COMMENT
CM_ BO_ 1080 "Tipper body number increments from the front most trailer and is indicated by the report index.";

// TRAILER_WHEEL_SPEED_RPT_00 MESSAGE COMMENT
CM_ BO_ 1069 "Chassis number increments from the front most trailer and is indicated by the report index.";

// USER_NOTIFICATION_CMD MESSAGE COMMENT
CM_ BO_ 1053 "Commands follow the list of priorities listed in user_can_protocol.md.";

// VIN_RPT MESSAGE COMMENT
CM_ BO_ 1044 "Not for new development.";

// WATCHDOG_RPT MESSAGE COMMENT
CM_ BO_ 1536 "Not for new development.";

//SAFETY_RESPONSE_RPT COMMENTS
CM_ SG_ 68 SAFETY_RESPONSE "A value of 1 indicates PACMod is operating normally or is in a safe state. Values 2 or 3 indicate an automated PACMod response.";

// SHIFT_AUX_RPT COMMENTS
CM_ SG_ 808 CALIBRATION_STATUS "CALIBRATION_STATUS shall indicate the status of a calibration of this system. If this system has more than one calibration, then those calibrations are INACTIVE.";
CM_ SG_ 808 SPEED_INTERLOCK_ACTIVE_AVAIL "PACMod sets this value as a function of which vehicle platform is under test and, therefore, this value does not change during operation.";
CM_ SG_ 808 BRAKE_INTERLOCK_ACTIVE_AVAIL "PACMod sets this value as a function of which vehicle platform is under test and, therefore, this value does not change during operation.";
CM_ SG_ 808 STAY_IN_NEUTRAL_MODE_AVAIL "PACMod sets this value as a function of which vehicle platform is under test and, therefore, this value does not change during operation.";
CM_ SG_ 808 BETWEEN_GEARS_AVAIL "PACMod sets this value as a function of which vehicle platform is under test and, therefore, this value does not change during operation.";
CM_ SG_ 808 SHIFT_MODE_AVAIL "PACMod sets this value as a function of which vehicle platform is under test and, therefore, this value does not change during operation.";
CM_ SG_ 808 GEAR_NUMBER "Gear number is positive for forward gears.";
CM_ SG_ 808 SHIFT_IN_PROGRESS "Indicates if the vehicle transmission is in process of shifting from the current gear to the destination gear.";
CM_ SG_ 808 DRIVELINE_ENGAGED "Indicates the transmission is engaged sufficiently to allow a transfer of torque through the transmission.";
CM_ SG_ 808 ACTUAL_GEAR_RATIO "Actual ratio of the input shaft speed to output shaft speed at current GEAR_NUMBER.";
CM_ SG_ 808 BETWEEN_GEARS "Indicates that the operator control interface is not commanding a specific transmission range.";

// SHIFT_CMD COMMENTS
CM_ SG_ 296 SHIFT_CMD "FORWARD is also HIGH on vehicles with LOW/HIGH, PARK and LOW only available on certain Vehicles.";

// SHIFT_RPT COMMENTS
CM_ SG_ 552 CONTROLLING_SYSTEMS "Number of systems in control.";

// SOFTWARE_VERSION_RPT_00 COMMENTS
CM_ SG_ 1032 MAJOR "MAJOR, MINOR, and PATCH shall be the software version number and shall be defined by Sematic Versioning 2.0.  For build numbers other than 0000, it shall be the most recent software release.";
CM_ SG_ 1032 MINOR "MAJOR, MINOR, and PATCH shall be the software version number and shall be defined by Sematic Versioning 2.0.  For build numbers other than 0000, it shall be the most recent software release.";
CM_ SG_ 1032 PATCH "MAJOR, MINOR, and PATCH shall be the software version number and shall be defined by Sematic Versioning 2.0.  For build numbers other than 0000, it shall be the most recent software release.";
CM_ SG_ 1032 BUILD0 "BUILD0-BUILD3 shall represent the software build number and shall be constrained to characters A-Z and 0-9.";
CM_ SG_ 1032 BUILD1 "BUILD0-BUILD3 shall represent the software build number and shall be constrained to characters A-Z and 0-9.";
CM_ SG_ 1032 BUILD2 "BUILD0-BUILD3 shall represent the software build number and shall be constrained to characters A-Z and 0-9.";
CM_ SG_ 1032 BUILD3 "BUILD0-BUILD3 shall represent the software build number and shall be constrained to characters A-Z and 0-9.";

// SOFTWARE_VERSION_RPT_01 COMMENTS
CM_ SG_ 1033 MAJOR "MAJOR, MINOR, and PATCH shall be the software version number and shall be defined by Sematic Versioning 2.0.  For build numbers other than 0000, it shall be the most recent software release.";
CM_ SG_ 1033 MINOR "MAJOR, MINOR, and PATCH shall be the software version number and shall be defined by Sematic Versioning 2.0.  For build numbers other than 0000, it shall be the most recent software release.";
CM_ SG_ 1033 PATCH "MAJOR, MINOR, and PATCH shall be the software version number and shall be defined by Sematic Versioning 2.0.  For build numbers other than 0000, it shall be the most recent software release.";
CM_ SG_ 1033 BUILD0 "BUILD0-BUILD3 shall represent the software build number and shall be constrained to characters A-Z and 0-9.";
CM_ SG_ 1033 BUILD1 "BUILD0-BUILD3 shall represent the software build number and shall be constrained to characters A-Z and 0-9.";
CM_ SG_ 1033 BUILD2 "BUILD0-BUILD3 shall represent the software build number and shall be constrained to characters A-Z and 0-9.";
CM_ SG_ 1033 BUILD3 "BUILD0-BUILD3 shall represent the software build number and shall be constrained to characters A-Z and 0-9.";

// SOFTWARE_VERSION_RPT_02 COMMENTS
CM_ SG_ 1034 MAJOR "MAJOR, MINOR, and PATCH shall be the software version number and shall be defined by Sematic Versioning 2.0.  For build numbers other than 0000, it shall be the most recent software release.";
CM_ SG_ 1034 MINOR "MAJOR, MINOR, and PATCH shall be the software version number and shall be defined by Sematic Versioning 2.0.  For build numbers other than 0000, it shall be the most recent software release.";
CM_ SG_ 1034 PATCH "MAJOR, MINOR, and PATCH shall be the software version number and shall be defined by Sematic Versioning 2.0.  For build numbers other than 0000, it shall be the most recent software release.";
CM_ SG_ 1034 BUILD0 "BUILD0-BUILD3 shall represent the software build number and shall be constrained to characters A-Z and 0-9.";
CM_ SG_ 1034 BUILD1 "BUILD0-BUILD3 shall represent the software build number and shall be constrained to characters A-Z and 0-9.";
CM_ SG_ 1034 BUILD2 "BUILD0-BUILD3 shall represent the software build number and shall be constrained to characters A-Z and 0-9.";
CM_ SG_ 1034 BUILD3 "BUILD0-BUILD3 shall represent the software build number and shall be constrained to characters A-Z and 0-9.";

// SOFTWARE_VERSION_RPT_03 COMMENTS
CM_ SG_ 1035 MAJOR "MAJOR, MINOR, and PATCH shall be the software version number and shall be defined by Sematic Versioning 2.0.  For build numbers other than 0000, it shall be the most recent software release.";
CM_ SG_ 1035 MINOR "MAJOR, MINOR, and PATCH shall be the software version number and shall be defined by Sematic Versioning 2.0.  For build numbers other than 0000, it shall be the most recent software release.";
CM_ SG_ 1035 PATCH "MAJOR, MINOR, and PATCH shall be the software version number and shall be defined by Sematic Versioning 2.0.  For build numbers other than 0000, it shall be the most recent software release.";
CM_ SG_ 1035 BUILD0 "BUILD0-BUILD3 shall represent the software build number and shall be constrained to characters A-Z and 0-9.";
CM_ SG_ 1035 BUILD1 "BUILD0-BUILD3 shall represent the software build number and shall be constrained to characters A-Z and 0-9.";
CM_ SG_ 1035 BUILD2 "BUILD0-BUILD3 shall represent the software build number and shall be constrained to characters A-Z and 0-9.";
CM_ SG_ 1035 BUILD3 "BUILD0-BUILD3 shall represent the software build number and shall be constrained to characters A-Z and 0-9.";

// SOFTWARE_VERSION_RPT_04 COMMENTS
CM_ SG_ 1036 MAJOR "MAJOR, MINOR, and PATCH shall be the software version number and shall be defined by Sematic Versioning 2.0.  For build numbers other than 0000, it shall be the most recent software release.";
CM_ SG_ 1036 MINOR "MAJOR, MINOR, and PATCH shall be the software version number and shall be defined by Sematic Versioning 2.0.  For build numbers other than 0000, it shall be the most recent software release.";
CM_ SG_ 1036 PATCH "MAJOR, MINOR, and PATCH shall be the software version number and shall be defined by Sematic Versioning 2.0.  For build numbers other than 0000, it shall be the most recent software release.";
CM_ SG_ 1036 BUILD0 "BUILD0-BUILD3 shall represent the software build number and shall be constrained to characters A-Z and 0-9.";
CM_ SG_ 1036 BUILD1 "BUILD0-BUILD3 shall represent the software build number and shall be constrained to characters A-Z and 0-9.";
CM_ SG_ 1036 BUILD2 "BUILD0-BUILD3 shall represent the software build number and shall be constrained to characters A-Z and 0-9.";
CM_ SG_ 1036 BUILD3 "BUILD0-BUILD3 shall represent the software build number and shall be constrained to characters A-Z and 0-9.";

// SOFTWARE_VERSION_RPT_05 COMMENTS
CM_ SG_ 1089 MAJOR "MAJOR, MINOR, and PATCH shall be the software version number and shall be defined by Sematic Versioning 2.0.  For build numbers other than 0000, it shall be the most recent software release.";
CM_ SG_ 1089 MINOR "MAJOR, MINOR, and PATCH shall be the software version number and shall be defined by Sematic Versioning 2.0.  For build numbers other than 0000, it shall be the most recent software release.";
CM_ SG_ 1089 PATCH "MAJOR, MINOR, and PATCH shall be the software version number and shall be defined by Sematic Versioning 2.0.  For build numbers other than 0000, it shall be the most recent software release.";
CM_ SG_ 1089 BUILD0 "BUILD0-BUILD3 shall represent the software build number and shall be constrained to characters A-Z and 0-9.";
CM_ SG_ 1089 BUILD1 "BUILD0-BUILD3 shall represent the software build number and shall be constrained to characters A-Z and 0-9.";
CM_ SG_ 1089 BUILD2 "BUILD0-BUILD3 shall represent the software build number and shall be constrained to characters A-Z and 0-9.";
CM_ SG_ 1089 BUILD3 "BUILD0-BUILD3 shall represent the software build number and shall be constrained to characters A-Z and 0-9.";

// STEERING_AUX_RPT COMMENTS
CM_ SG_ 812 STEERING_TORQUE "Ratio of full-scale value of signal from -1 to 1 (i.e. percent from -1 to 1) possibly exceeding -1 and 1.";
CM_ SG_ 812 OPERATOR_INTERACTION "OPERATOR_INTERACTION shall have the value of 1 if the driver is moving, changing, or otherwise touching the operator control(s) that relates to this signal to an extent that is detectable. Otherwise, the value shall be 0.";
CM_ SG_ 812 OPERATOR_INTERACTION_AVAIL "PACMod sets this value as a function of which vehicle platform is under test and, therefore, this value does not change during operation.";
CM_ SG_ 812 STEERING_LIMITING_ACTIVE "STEERING_LIMITING_ACTIVE shall have the value of 1 if a limiting function is reducing an excessive command.  Otherwise, the value shall be 0.";
CM_ SG_ 812 CALIBRATION_STATUS "CALIBRATION_STATUS shall indicate the status of a calibration of this system. If this system has more than one calibration, then those calibrations are INACTIVE.";
CM_ SG_ 812 STEERING_CONTROLLER_TYPE "STEERING_CONTROLER_TYPE indicates which steering controller is the PACMod System is using.";
CM_ SG_ 812 ROTATION_RATE_AVAIL "PACMod sets this value as a function of which vehicle platform is under test and, therefore, this value does not change during operation.";
CM_ SG_ 812 STEERING_TORQUE_AVAIL "PACMod sets this value as a function of which vehicle platform is under test and, therefore, this value does not change during operation.";
CM_ SG_ 812 ROTATION_RATE_SIGN_AVAIL "PACMod sets this value as a function of which vehicle platform is under test and, therefore, this value does not change during operation.";
CM_ SG_ 812 ROTATION_RATE_SIGN "Counterclockwise rotation is positive according to the right-hand rule.";
CM_ SG_ 812 STEERING_LIMITING_ACTIVE_AVAIL "PACMod sets this value as a function of which vehicle platform is under test and, therefore, this value does not change during operation.";
CM_ SG_ 812 STEERING_CONTROLLER_TYPE_AVAIL "PACMod sets this value as a function of which vehicle platform is under test and, therefore, this value does not change during operation.";

// STEERING_AUX_RPT_2 COMMENTS
CM_ SG_ 814 STEERING_TORQUE "Ratio of full-scale value of signal from -1 to 1 (i.e. percent from -1 to 1) possibly exceeding -1 and 1.";
CM_ SG_ 814 OPERATOR_INTERACTION "OPERATOR_INTERACTION shall have the value of 1 if the driver is moving, changing, or otherwise touching the operator control(s) that relates to this signal to an extent that is detectable. Otherwise, the value shall be 0.";
CM_ SG_ 814 OPERATOR_INTERACTION_AVAIL "PACMod sets this value as a function of which vehicle platform is under test and, therefore, this value does not change during operation.";
CM_ SG_ 814 STEERING_LIMITING_ACTIVE "STEERING_LIMITING_ACTIVE shall have the value of 1 if a limiting function is reducing an excessive command.  Otherwise, the value shall be 0.";
CM_ SG_ 814 CALIBRATION_STATUS "CALIBRATION_STATUS shall indicate the status of a calibration of this system. If this system has more than one calibration, then those calibrations are INACTIVE.";
CM_ SG_ 814 STEERING_CONTROLLER_TYPE "STEERING_CONTROLER_TYPE indicates which steering controller is the PACMod System is using.";
CM_ SG_ 814 ROTATION_RATE_AVAIL "PACMod sets this value as a function of which vehicle platform is under test and, therefore, this value does not change during operation.";
CM_ SG_ 814 STEERING_TORQUE_AVAIL "PACMod sets this value as a function of which vehicle platform is under test and, therefore, this value does not change during operation.";
CM_ SG_ 814 ROTATION_RATE_SIGN_AVAIL "PACMod sets this value as a function of which vehicle platform is under test and, therefore, this value does not change during operation.";
CM_ SG_ 814 ROTATION_RATE_SIGN "Counterclockwise rotation is positive according to the right-hand rule.";
CM_ SG_ 814 STEERING_LIMITING_ACTIVE_AVAIL "PACMod sets this value as a function of which vehicle platform is under test and, therefore, this value does not change during operation.";
CM_ SG_ 814 STEERING_CONTROLLER_TYPE_AVAIL "PACMod sets this value as a function of which vehicle platform is under test and, therefore, this value does not change during operation.";

// STEERING_CMD_LIMIT_RPT COMMENTS
CM_ SG_ 557 POSITION_CMD_LIMIT "The POSITION_CMD_LIMIT shall have the value of the limit imposed on the command associated with this system.";
CM_ SG_ 557 LIMITED_POSITION_CMD "The LIMITED_POSITION_CMD shall have the value of command associated with this system constrained by the STEERING_CMD_LIMIT.";
CM_ SG_ 557 ROTATION_RATE_CMD_LIMIT "The ROTATION_RATE_CMD_LIMIT shall have the value of the limit imposed on the command associated with this system.";
CM_ SG_ 557 LIMITED_ROTATION_RATE "The LIMITED_ROTATION_RATE_CMD shall have the value of command associated with this system constrained by the ROTATION_RATE_CMD_LIMIT.";

// STEERING_MOTOR_RPT_1 COMMENTS
CM_ SG_ 1028 MOTOR_CURRENT "As reported by the motor.";
CM_ SG_ 1028 SHAFT_POSITION "As reported by the motor.";

// STEERING_MOTOR_RPT_2 COMMENTS
CM_ SG_ 1029 ANGULAR_SPEED "As reported by the motor.";

// STEERING_MOTOR_RPT_3 COMMENTS
CM_ SG_ 1030 TORQUE_OUTPUT "As reported by the motor.";
CM_ SG_ 1030 TORQUE_INPUT "As reported by the motor.";

// STEERING_RPT COMMENTS
CM_ SG_ 556 CONTROLLING_SYSTEMS "Number of systems in control.";

// STEERING_RPT_2 COMMENTS
CM_ SG_ 558 CONTROLLING_SYSTEMS "Number of systems in control.";

// SUPERVISORY_CTRL COMMENTS
CM_ SG_ 129 ENABLE "A system shall enable only if the supervisory enablement rules are met.  See user_can_protocol.md.";
CM_ SG_ 129 COUNTER "Counter shall have the value of 0 with the first message transmission.  It shall increase by 1 with each subsequent message transmission up to and including the value of 0xF.  The next message transmission shall be 0, and this pattern shall repeat.";
CM_ SG_ 129 COMPLEMENT "The COMPLEMENT shall be the complement of the COUNTER.  For example, if COUNTER is 0x1011, then the COMPLEMENT is 0x0100." ;

// TIPPER_BODY_AUX_RPT_00 COMMENTS
CM_ SG_ 856 DOOR_ANGLE "Door angle is zero when closed and increases as it opens.";
CM_ SG_ 856 BODY_ANGLE "Body angle is zero in haul position and increases as it dumps.";

// TIPPER_BODY_AUX_RPT_01 COMMENTS
CM_ SG_ 876 DOOR_ANGLE "Door angle is zero when closed and increases as it opens.";
CM_ SG_ 876 BODY_ANGLE "Body angle is zero in haul position and increases as it dumps.";

// TIPPER_BODY_AUX_RPT_02 COMMENTS
CM_ SG_ 880 DOOR_ANGLE "Door angle is zero when closed and increases as it opens.";
CM_ SG_ 880 BODY_ANGLE "Body angle is zero in haul position and increases as it dumps.";

// TIPPER_BODY_CMD_00 COMMENTS
CM_ SG_ 344 TIPPER_CONTROL_CMD "RAISE moves towards dump position, LOWER moves towards haul position.";

// TIPPER_BODY_CMD_01 COMMENTS
CM_ SG_ 364 TIPPER_CONTROL_CMD "RAISE moves towards dump position, LOWER moves towards haul position.";

// TIPPER_BODY_CMD_02 COMMENTS
CM_ SG_ 368 TIPPER_CONTROL_CMD "RAISE moves towards dump position, LOWER moves towards haul position.";

// TIPPER_BODY_RPT_00 COMMENTS
CM_ SG_ 600 MANUAL_INPUT "RAISE moves towards dump position, LOWER moves towards haul position.";
CM_ SG_ 600 COMMANDED_VALUE "RAISE moves towards dump position, LOWER moves towards haul position.";
CM_ SG_ 600 OUTPUT_VALUE "RAISE moves towards dump position, LOWER moves towards haul position.";
CM_ SG_ 600 CONTROLLING_SYSTEMS "Number of systems in control.";

// TIPPER_BODY_RPT_01 COMMENTS
CM_ SG_ 620 MANUAL_INPUT "RAISE moves towards dump position, LOWER moves towards haul position.";
CM_ SG_ 620 COMMANDED_VALUE "RAISE moves towards dump position, LOWER moves towards haul position.";
CM_ SG_ 620 OUTPUT_VALUE "RAISE moves towards dump position, LOWER moves towards haul position.";
CM_ SG_ 620 CONTROLLING_SYSTEMS "Number of systems in control.";

// TIPPER_BODY_RPT_02 COMMENTS
CM_ SG_ 624 MANUAL_INPUT "RAISE moves towards dump position, LOWER moves towards haul position.";
CM_ SG_ 624 COMMANDED_VALUE "RAISE moves towards dump position, LOWER moves towards haul position.";
CM_ SG_ 624 OUTPUT_VALUE "RAISE moves towards dump position, LOWER moves towards haul position.";
CM_ SG_ 624 CONTROLLING_SYSTEMS "Number of systems in control.";

// TIRE_PRESSURE_EXTENDED_RPT COMMENTS
CM_ SG_ 1072 TIRE_CHASSIS_INDEX_1 "The value 0 represents the towing vehicle and all subsequent numbers represent their location behind the towing vehicle.";
CM_ SG_ 1072 TIRE_AXLE_1 "Axle number starting from the front of the respective chassis number (a).";
CM_ SG_ 1072 TIRE_POSITION_1 "Tire location starting from the left and moving sequentially to the right.";
CM_ SG_ 1072 TIRE_PRESSURE_1 "Values 0 to 250 represent valid measured data.";
CM_ SG_ 1072 TIRE_CHASSIS_INDEX_2 "The value 0 represents the towing vehicle and all subsequent numbers represent their location behind the towing vehicle.";
CM_ SG_ 1072 TIRE_AXLE_2 "Axle number starting from the front of the respective chassis number (a).";
CM_ SG_ 1072 TIRE_POSITION_2 "Tire location starting from the left and moving sequentially to the right.";
CM_ SG_ 1072 TIRE_PRESSURE_2 "Values 0 to 250 represent valid measured data.";
CM_ SG_ 1072 TIRE_CHASSIS_INDEX_3 "The value 0 represents the towing vehicle and all subsequent numbers represent their location behind the towing vehicle.";
CM_ SG_ 1072 TIRE_AXLE_3 "Axle number starting from the front of the respective chassis number (a).";
CM_ SG_ 1072 TIRE_POSITION_3 "Tire location starting from the left and moving sequentially to the right.";
CM_ SG_ 1072 TIRE_PRESSURE_3 "Values 0 to 250 represent valid measured data.";

// TIRE_PRESSURE_EXTENDED_RPT_2 COMMENTS
CM_ SG_ 1073 TIRE_CHASSIS_INDEX_1 "The value 0 represents the towing vehicle and all subsequent numbers represent their location behind the towing vehicle.";
CM_ SG_ 1073 TIRE_AXLE_1 "Axle number starting from the front of the respective chassis number (a).";
CM_ SG_ 1073 TIRE_POSITION_1 "Tire location starting from the left and moving sequentially to the right.";
CM_ SG_ 1073 TIRE_PRESSURE_1 "Values 0 to 250 represent valid measured data.";
CM_ SG_ 1073 TIRE_CHASSIS_INDEX_2 "The value 0 represents the towing vehicle and all subsequent numbers represent their location behind the towing vehicle.";
CM_ SG_ 1073 TIRE_AXLE_2 "Axle number starting from the front of the respective chassis number (a).";
CM_ SG_ 1073 TIRE_POSITION_2 "Tire location starting from the left and moving sequentially to the right.";
CM_ SG_ 1073 TIRE_PRESSURE_2 "Values 0 to 250 represent valid measured data.";
CM_ SG_ 1073 TIRE_CHASSIS_INDEX_3 "The value 0 represents the towing vehicle and all subsequent numbers represent their location behind the towing vehicle.";
CM_ SG_ 1073 TIRE_AXLE_3 "Axle number starting from the front of the respective chassis number (a).";
CM_ SG_ 1073 TIRE_POSITION_3 "Tire location starting from the left and moving sequentially to the right.";
CM_ SG_ 1073 TIRE_PRESSURE_3 "Values 0 to 250 represent valid measured data.";

// TIRE_TEMPERATURE_EXTENDED_RPT COMMENTS
CM_ SG_ 1074 TIRE_CHASSIS_INDEX_1 "The value 0 represents the towing vehicle and all subsequent numbers represent their location behind the towing vehicle.";
CM_ SG_ 1074 TIRE_AXLE_1 "Axle number starting from the front of the respective chassis number (a).";
CM_ SG_ 1074 TIRE_POSITION_1 "Tire location starting from the left and moving sequentially to the right.";
CM_ SG_ 1074 TIRE_TEMPERATURE_1 "Values 0 to 250 represent valid measured data.";
CM_ SG_ 1074 TIRE_CHASSIS_INDEX_2 "The value 0 represents the towing vehicle and all subsequent numbers represent their location behind the towing vehicle.";
CM_ SG_ 1074 TIRE_AXLE_2 "Axle number starting from the front of the respective chassis number (a).";
CM_ SG_ 1074 TIRE_POSITION_2 "Tire location starting from the left and moving sequentially to the right.";
CM_ SG_ 1074 TIRE_TEMPERATURE_2 "Values 0 to 250 represent valid measured data.";
CM_ SG_ 1074 TIRE_CHASSIS_INDEX_3 "The value 0 represents the towing vehicle and all subsequent numbers represent their location behind the towing vehicle.";
CM_ SG_ 1074 TIRE_AXLE_3 "Axle number starting from the front of the respective chassis number (a).";
CM_ SG_ 1074 TIRE_POSITION_3 "Tire location starting from the left and moving sequentially to the right.";
CM_ SG_ 1074 TIRE_TEMPERATURE_3 "Values 0 to 250 represent valid measured data.";

// TIRE_TEMPERATURE_EXTENDED_RPT_2 COMMENTS
CM_ SG_ 1075 TIRE_CHASSIS_INDEX_1 "The value 0 represents the towing vehicle and all subsequent numbers represent their location behind the towing vehicle.";
CM_ SG_ 1075 TIRE_AXLE_1 "Axle number starting from the front of the respective chassis number (a).";
CM_ SG_ 1075 TIRE_POSITION_1 "Tire location starting from the left and moving sequentially to the right.";
CM_ SG_ 1075 TIRE_TEMPERATURE_1 "Values 0 to 250 represent valid measured data.";
CM_ SG_ 1075 TIRE_CHASSIS_INDEX_2 "The value 0 represents the towing vehicle and all subsequent numbers represent their location behind the towing vehicle.";
CM_ SG_ 1075 TIRE_AXLE_2 "Axle number starting from the front of the respective chassis number (a).";
CM_ SG_ 1075 TIRE_POSITION_2 "Tire location starting from the left and moving sequentially to the right.";
CM_ SG_ 1075 TIRE_TEMPERATURE_2 "Values 0 to 250 represent valid measured data.";
CM_ SG_ 1075 TIRE_CHASSIS_INDEX_3 "The value 0 represents the towing vehicle and all subsequent numbers represent their location behind the towing vehicle.";
CM_ SG_ 1075 TIRE_AXLE_3 "Axle number starting from the front of the respective chassis number (a).";
CM_ SG_ 1075 TIRE_POSITION_3 "Tire location starting from the left and moving sequentially to the right.";
CM_ SG_ 1075 TIRE_TEMPERATURE_3 "Values 0 to 250 represent valid measured data.";

// TRAILER_AIR_SUPPLY_RPT COMMENTS
CM_ SG_ 612 CONTROLLING_SYSTEMS "Number of systems in control.";

// TRAILER_AIR_SUPPLY_RPT_2 COMMENTS
CM_ SG_ 614 CONTROLLING_SYSTEMS "Number of systems in control.";

// TRAILER_BRAKE_PRESSURE_RPT_00 COMMENTS
CM_ SG_ 1064 BRAKE_PRESSURE_AXLE_1_LEFT "Axle number starting from the front of the respective chassis number (described in message comment).";
CM_ SG_ 1064 BRAKE_PRESSURE_AXLE_1_RIGHT "Axle number starting from the front of the respective chassis number (described in message comment).";
CM_ SG_ 1064 BRAKE_PRESSURE_AXLE_2_LEFT "Axle number starting from the front of the respective chassis number (described in message comment).";
CM_ SG_ 1064 BRAKE_PRESSURE_AXLE_2_RIGHT "Axle number starting from the front of the respective chassis number (described in message comment).";
CM_ SG_ 1064 BRAKE_PRESSURE_AXLE_3_LEFT "Axle number starting from the front of the respective chassis number (described in message comment).";
CM_ SG_ 1064 BRAKE_PRESSURE_AXLE_3_RIGHT "Axle number starting from the front of the respective chassis number (described in message comment).";

// TRAILER_BRAKE_PRESSURE_RPT_01 COMMENTS
CM_ SG_ 1065 BRAKE_PRESSURE_AXLE_1_LEFT "Axle number starting from the front of the respective chassis number (described in message comment).";
CM_ SG_ 1065 BRAKE_PRESSURE_AXLE_1_RIGHT "Axle number starting from the front of the respective chassis number (described in message comment).";
CM_ SG_ 1065 BRAKE_PRESSURE_AXLE_2_LEFT "Axle number starting from the front of the respective chassis number (described in message comment).";
CM_ SG_ 1065 BRAKE_PRESSURE_AXLE_2_RIGHT "Axle number starting from the front of the respective chassis number (described in message comment).";
CM_ SG_ 1065 BRAKE_PRESSURE_AXLE_3_LEFT "Axle number starting from the front of the respective chassis number (described in message comment).";
CM_ SG_ 1065 BRAKE_PRESSURE_AXLE_3_RIGHT "Axle number starting from the front of the respective chassis number (described in message comment).";

// TRAILER_BRAKE_PRESSURE_RPT_02 COMMENTS
CM_ SG_ 1066 BRAKE_PRESSURE_AXLE_1_LEFT "Axle number starting from the front of the respective chassis number (described in message comment).";
CM_ SG_ 1066 BRAKE_PRESSURE_AXLE_1_RIGHT "Axle number starting from the front of the respective chassis number (described in message comment).";
CM_ SG_ 1066 BRAKE_PRESSURE_AXLE_2_LEFT "Axle number starting from the front of the respective chassis number (described in message comment).";
CM_ SG_ 1066 BRAKE_PRESSURE_AXLE_2_RIGHT "Axle number starting from the front of the respective chassis number (described in message comment).";
CM_ SG_ 1066 BRAKE_PRESSURE_AXLE_3_LEFT "Axle number starting from the front of the respective chassis number (described in message comment).";
CM_ SG_ 1066 BRAKE_PRESSURE_AXLE_3_RIGHT "Axle number starting from the front of the respective chassis number (described in message comment).";

// TRAILER_BRAKE_PRESSURE_RPT_03 COMMENTS
CM_ SG_ 1067 BRAKE_PRESSURE_AXLE_1_LEFT "Axle number starting from the front of the respective chassis number (described in message comment).";
CM_ SG_ 1067 BRAKE_PRESSURE_AXLE_1_RIGHT "Axle number starting from the front of the respective chassis number (described in message comment).";
CM_ SG_ 1067 BRAKE_PRESSURE_AXLE_2_LEFT "Axle number starting from the front of the respective chassis number (described in message comment).";
CM_ SG_ 1067 BRAKE_PRESSURE_AXLE_2_RIGHT "Axle number starting from the front of the respective chassis number (described in message comment).";
CM_ SG_ 1067 BRAKE_PRESSURE_AXLE_3_LEFT "Axle number starting from the front of the respective chassis number (described in message comment).";
CM_ SG_ 1067 BRAKE_PRESSURE_AXLE_3_RIGHT "Axle number starting from the front of the respective chassis number (described in message comment).";

// TRAILER_BRAKE_PRESSURE_RPT_04 COMMENTS
CM_ SG_ 1068 BRAKE_PRESSURE_AXLE_1_LEFT "Axle number starting from the front of the respective chassis number (described in message comment).";
CM_ SG_ 1068 BRAKE_PRESSURE_AXLE_1_RIGHT "Axle number starting from the front of the respective chassis number (described in message comment).";
CM_ SG_ 1068 BRAKE_PRESSURE_AXLE_2_LEFT "Axle number starting from the front of the respective chassis number (described in message comment).";
CM_ SG_ 1068 BRAKE_PRESSURE_AXLE_2_RIGHT "Axle number starting from the front of the respective chassis number (described in message comment).";
CM_ SG_ 1068 BRAKE_PRESSURE_AXLE_3_LEFT "Axle number starting from the front of the respective chassis number (described in message comment).";
CM_ SG_ 1068 BRAKE_PRESSURE_AXLE_3_RIGHT "Axle number starting from the front of the respective chassis number (described in message comment).";

// TRAILER_IDENTIFIER_RPT_00 COMMENTS
CM_ SG_ 1095 TRAILER_IDENTIFIER "Exact definition varies across vehicles - See platform guide.";

// TRAILER_IDENTIFIER_RPT_01 COMMENTS
CM_ SG_ 1096 TRAILER_IDENTIFIER "Exact definition varies across vehicles - See platform guide.";

// TRAILER_IDENTIFIER_RPT_02 COMMENTS
CM_ SG_ 1097 TRAILER_IDENTIFIER "Exact definition varies across vehicles - See platform guide.";

// TRAILER_IDENTIFIER_RPT_03 COMMENTS
CM_ SG_ 1098 TRAILER_IDENTIFIER "Exact definition varies across vehicles - See platform guide.";

// TRAILER_IDENTIFIER_RPT_04 COMMENTS
CM_ SG_ 1099 TRAILER_IDENTIFIER "Exact definition varies across vehicles - See platform guide.";

// TRAILER_IDENTIFIER_RPT_05 COMMENTS
CM_ SG_ 1106 TRAILER_IDENTIFIER "Exact definition varies across vehicles - See platform guide.";

// TRAILER_PAYLOAD_RPT_00 COMMENTS
CM_ SG_ 1078 PAYLOAD_00 "Axle group number starting from the front of the respective trailer number and is indicated by the signal index. This value represents only the contents of the trailer.";
CM_ SG_ 1078 TARE_00 "Axle group number starting from the front of the respective trailer number and is indicated by the signal index. This value represents only an empty trailer.";
CM_ SG_ 1078 PAYLOAD_01 "Axle group number starting from the front of the respective trailer number and is indicated by the signal index. This value represents only the contents of the trailer.";
CM_ SG_ 1078 TARE_01 "Axle group number starting from the front of the respective trailer number and is indicated by the signal index. This value represents only an empty trailer.";

// TRAILER_PAYLOAD_RPT_01 COMMENTS
CM_ SG_ 1079 PAYLOAD_00 "Axle group number starting from the front of the respective trailer number and is indicated by the signal index. This value represents only the contents of the trailer.";
CM_ SG_ 1079 TARE_00 "Axle group number starting from the front of the respective trailer number and is indicated by the signal index. This value represents only an empty trailer.";
CM_ SG_ 1079 PAYLOAD_01 "Axle group number starting from the front of the respective trailer number and is indicated by the signal index. This value represents only the contents of the trailer.";
CM_ SG_ 1079 TARE_01 "Axle group number starting from the front of the respective trailer number and is indicated by the signal index. This value represents only an empty trailer.";

// TRAILER_PAYLOAD_RPT_02 COMMENTS
CM_ SG_ 1080 PAYLOAD_00 "Axle group number starting from the front of the respective trailer number and is indicated by the signal index. This value represents only the contents of the trailer.";
CM_ SG_ 1080 TARE_00 "Axle group number starting from the front of the respective trailer number and is indicated by the signal index. This value represents only an empty trailer.";
CM_ SG_ 1080 PAYLOAD_01 "Axle group number starting from the front of the respective trailer number and is indicated by the signal index. This value represents only the contents of the trailer.";
CM_ SG_ 1080 TARE_01 "Axle group number starting from the front of the respective trailer number and is indicated by the signal index. This value represents only an empty trailer.";

// TRAILER_WHEEL_SPEED_RPT_00 COMMENTS
CM_ SG_ 1069 WHEEL_BASED_VEHICLE_SPEED "Absolute value of the average of wheel speeds for one trailer axle.";
CM_ SG_ 1069 WHEEL_SPEED_DIFFERENCE_MAIN_AXLE "Difference = speed right - speed left";

// TURN_AUX_RPT COMMENTS
CM_ SG_ 816 PASS_BLINKER_BULB_ON_AVAIL "PACMod sets this value as a function of which vehicle platform is under test and, therefore, this value does not change during operation.";
CM_ SG_ 816 DRIVER_BLINKER_BULB_ON_AVAIL "PACMod sets this value as a function of which vehicle platform is under test and, therefore, this value does not change during operation.";

// USER_PC_HEALTH_RPT_00 COMMENTS
CM_ SG_ 37 COUNTER "The COUNTER shall have the value of 0 with the first message transmission. It shall increase by 1 with each subsequent message transmission up to and including the value of 0xFF. The next message transmission shall be 0, and this pattern shall repeat.";
CM_ SG_ 37 CHECKSUM "The CHECKSUM shall be the least significant byte of the sum of the message ID and the COUNTER. For example, if COUNTER is 0xFB and the message ID is 0x25, then the sum is 0x0120 and the checksum is 0x20.";
CM_ SG_ 37 USER_PC_APPLICATION_FAULT "This signal allows the User PC application to report a fault in its operation.";

// USER_PC_HEALTH_RPT_01 COMMENTS
CM_ SG_ 38 COUNTER "The COUNTER shall have the value of 0 with the first message transmission. It shall increase by 1 with each subsequent message transmission up to and including the value of 0xFF. The next message transmission shall be 0, and this pattern shall repeat.";
CM_ SG_ 38 CHECKSUM "The CHECKSUM shall be the least significant byte of the sum of the message ID and the COUNTER. For example, if COUNTER is 0xFB and the message ID is 0x25, then the sum is 0x0120 and the checksum is 0x20.";
CM_ SG_ 38 USER_PC_APPLICATION_FAULT "This signal allows the User PC application to report a fault in its operation.";

// VEH_DYNAMICS_RPT COMMENTS
CM_ SG_ 1043 VEH_G_FORCES "G forces are positive in the forward direction.";

// VEHICLE_FAULT_RPT COMMENTS
CM_ SG_ 66 ENGINE_CHECK_LIGHT_AVAIL "PACMod sets this value as a function of which vehicle platform is under test and, therefore, this value does not change during operation.";
CM_ SG_ 66 TRC_FAULT_LIGHT_AVAIL "PACMod sets this value as a function of which vehicle platform is under test and, therefore, this value does not change during operation.";
CM_ SG_ 66 TRC_OFF_FAULT_LIGHT_AVAIL "PACMod sets this value as a function of which vehicle platform is under test and, therefore, this value does not change during operation.";
CM_ SG_ 66 ANTILOCK_BRAKE_FAULT_LIGHT_AVAIL "PACMod sets this value as a function of which vehicle platform is under test and, therefore, this value does not change during operation.";
CM_ SG_ 66 TIRE_FAULT_LIGHT_AVAIL "PACMod sets this value as a function of which vehicle platform is under test and, therefore, this value does not change during operation.";
CM_ SG_ 66 AIR_BAGS_FAULT_LIGHT_AVAIL "PACMod sets this value as a function of which vehicle platform is under test and, therefore, this value does not change during operation.";
CM_ SG_ 66 LOW_ENGINE_OIL_PRESSURE_AVAIL "PACMod sets this value as a function of which vehicle platform is under test and, therefore, this value does not change during operation.";
CM_ SG_ 66 BRAKE_FAULT_AVAIL "PACMod sets this value as a function of which vehicle platform is under test and, therefore, this value does not change during operation.";
CM_ SG_ 66 BRK_APPLIED_POWER_REDUCED_AVAIL "PACMod sets this value as a function of which vehicle platform is under test and, therefore, this value does not change during operation.";
CM_ SG_ 66 STEERING_LOSS_STOP_SAFELY_AVAIL "PACMod sets this value as a function of which vehicle platform is under test and, therefore, this value does not change during operation.";
CM_ SG_ 66 STEERING_FAULT_SERVICE_NOW_AVAIL "PACMod sets this value as a function of which vehicle platform is under test and, therefore, this value does not change during operation.";
CM_ SG_ 66 XMSN_FAULT_SERVICE_NOW_AVAIL "PACMod sets this value as a function of which vehicle platform is under test and, therefore, this value does not change during operation.";
CM_ SG_ 66 XMSN_OVER_TEMP_STOP_SAFELY_AVAIL "PACMod sets this value as a function of which vehicle platform is under test and, therefore, this value does not change during operation.";
CM_ SG_ 66 LOW_BATTERY_FEATURES_OFF_AVAIL "PACMod sets this value as a function of which vehicle platform is under test and, therefore, this value does not change during operation.";
CM_ SG_ 66 CHARGING_SYSTEM_FAULT_AVAIL "PACMod sets this value as a function of which vehicle platform is under test and, therefore, this value does not change during operation.";

// VEHICLE_SPEED_RPT COMMENTS
CM_ SG_ 1024 VEHICLE_SPEED "Wheel speed is positive in the forward direction.";

// WHEEL_SPEED_RPT COMMENTS
CM_ SG_ 1031 WHEEL_SPD_AXLE_1_LEFT "Wheel speed is positive in the forward direction.";
CM_ SG_ 1031 WHEEL_SPD_AXLE_1_RIGHT "Wheel speed is positive in the forward direction.";
CM_ SG_ 1031 WHEEL_SPD_AXLE_2_LEFT "Wheel speed is positive in the forward direction.";
CM_ SG_ 1031 WHEEL_SPD_AXLE_2_RIGHT "Wheel speed is positive in the forward direction.";

// WHEEL_SPEED_RPT_2 COMMENTS
CM_ SG_ 1062 WHEEL_SPD_AXLE_3_LEFT "Wheel speed is positive in the forward direction.";
CM_ SG_ 1062 WHEEL_SPD_AXLE_3_RIGHT "Wheel speed is positive in the forward direction.";
CM_ SG_ 1062 WHEEL_SPD_AXLE_4_LEFT "Wheel speed is positive in the forward direction.";
CM_ SG_ 1062 WHEEL_SPD_AXLE_4_RIGHT "Wheel speed is positive in the forward direction.";

/////////////////////////////
//                         //
//  Attribute Definitions  //
//                         //
/////////////////////////////
BA_DEF_ BO_  "GenMsgCycleTime" INT 0 60000;
BA_DEF_ SG_  "GenSigCycleTime" INT 0 60000;
BA_DEF_ SG_  "GenSigSendType" ENUM  "Cyclic ","OnWrite ","OnWriteWithRepetition ","OnChange ","OnChangeWithRepetition ","IfActive ","IfActiveWithRepetition ","NoSigSendType";
BA_DEF_ BO_  "GenMsgSendType" ENUM  "Cyclic ","NotUsed ","NotUsed ","NotUsed ","NotUsed ","NotUsed ","NotUsed ","IfActive ","NoMsgSendType ";
BA_DEF_ BO_  "Component_Address_Type" ENUM  "NO_COMPONENT_ADDRESS","COMPONENT_ADDRESS";
BA_DEF_ BO_  "Component_Address" INT 0 255;

////////////////////////////////
//                            //
//  Attribute Default Values  //
//                            //
////////////////////////////////
BA_DEF_DEF_  "GenSigCycleTime" 33;
BA_DEF_DEF_  "GenMsgCycleTime" 33;
BA_DEF_DEF_  "GenSigSendType" "NoSigSendType";
BA_DEF_DEF_  "GenMsgSendType" "Cyclic ";
BA_DEF_DEF_  "Component_Address_Type" "NO_COMPONENT_ADDRESS";
BA_DEF_DEF_  "Component_Address" 0;

// SAFETY_RESPONSE_RPT ATTRIBUTES
BA_ "GenMsgCycleTime" BO_ 68 250;
BA_ "GenSigCycleTime" SG_ 68 SAFETY_RESPONSE 250;

// SOFTWARE_VERSION_RPT_00 ATTRIBUTES
BA_ "Component_Address_Type" BO_ 1032 1;
BA_ "GenMsgCycleTime" BO_ 1032 1000;
BA_ "GenSigCycleTime" SG_ 1032 MAJOR 1000;
BA_ "GenSigCycleTime" SG_ 1032 MINOR 1000;
BA_ "GenSigCycleTime" SG_ 1032 PATCH 1000;
BA_ "GenSigCycleTime" SG_ 1032 BUILD0 1000;
BA_ "GenSigCycleTime" SG_ 1032 BUILD1 1000;
BA_ "GenSigCycleTime" SG_ 1032 BUILD2 1000;
BA_ "GenSigCycleTime" SG_ 1032 BUILD3 1000;

// SOFTWARE_VERSION_RPT_01 ATTRIBUTES
BA_ "Component_Address" BO_ 1033 1;
BA_ "Component_Address_Type" BO_ 1033 1;
BA_ "GenMsgCycleTime" BO_ 1033 1000;
BA_ "GenSigCycleTime" SG_ 1033 MAJOR 1000;
BA_ "GenSigCycleTime" SG_ 1033 MINOR 1000;
BA_ "GenSigCycleTime" SG_ 1033 PATCH 1000;
BA_ "GenSigCycleTime" SG_ 1033 BUILD0 1000;
BA_ "GenSigCycleTime" SG_ 1033 BUILD1 1000;
BA_ "GenSigCycleTime" SG_ 1033 BUILD2 1000;
BA_ "GenSigCycleTime" SG_ 1033 BUILD3 1000;

// SOFTWARE_VERSION_RPT_02 ATTRIBUTES
BA_ "Component_Address" BO_ 1034 2;
BA_ "Component_Address_Type" BO_ 1034 1;
BA_ "GenMsgCycleTime" BO_ 1034 1000;
BA_ "GenSigCycleTime" SG_ 1034 MAJOR 1000;
BA_ "GenSigCycleTime" SG_ 1034 MINOR 1000;
BA_ "GenSigCycleTime" SG_ 1034 PATCH 1000;
BA_ "GenSigCycleTime" SG_ 1034 BUILD0 1000;
BA_ "GenSigCycleTime" SG_ 1034 BUILD1 1000;
BA_ "GenSigCycleTime" SG_ 1034 BUILD2 1000;
BA_ "GenSigCycleTime" SG_ 1034 BUILD3 1000;

// SOFTWARE_VERSION_RPT_03 ATTRIBUTES
BA_ "Component_Address" BO_ 1035 3;
BA_ "Component_Address_Type" BO_ 1035 1;
BA_ "GenMsgCycleTime" BO_ 1035 1000;
BA_ "GenSigCycleTime" SG_ 1035 MAJOR 1000;
BA_ "GenSigCycleTime" SG_ 1035 MINOR 1000;
BA_ "GenSigCycleTime" SG_ 1035 PATCH 1000;
BA_ "GenSigCycleTime" SG_ 1035 BUILD0 1000;
BA_ "GenSigCycleTime" SG_ 1035 BUILD1 1000;
BA_ "GenSigCycleTime" SG_ 1035 BUILD2 1000;
BA_ "GenSigCycleTime" SG_ 1035 BUILD3 1000;

// SOFTWARE_VERSION_RPT_04 ATTRIBUTES
BA_ "Component_Address" BO_ 1036 4;
BA_ "Component_Address_Type" BO_ 1036 1;
BA_ "GenMsgCycleTime" BO_ 1036 1000;
BA_ "GenSigCycleTime" SG_ 1036 MAJOR 1000;
BA_ "GenSigCycleTime" SG_ 1036 MINOR 1000;
BA_ "GenSigCycleTime" SG_ 1036 PATCH 1000;
BA_ "GenSigCycleTime" SG_ 1036 BUILD0 1000;
BA_ "GenSigCycleTime" SG_ 1036 BUILD1 1000;
BA_ "GenSigCycleTime" SG_ 1036 BUILD2 1000;
BA_ "GenSigCycleTime" SG_ 1036 BUILD3 1000;

// SOFTWARE_VERSION_RPT_05 ATTRIBUTES
BA_ "Component_Address" BO_ 1089 4;
BA_ "Component_Address_Type" BO_ 1089 1;
BA_ "GenMsgCycleTime" BO_ 1089 1000;
BA_ "GenSigCycleTime" SG_ 1089 MAJOR 1000;
BA_ "GenSigCycleTime" SG_ 1089 MINOR 1000;
BA_ "GenSigCycleTime" SG_ 1089 PATCH 1000;
BA_ "GenSigCycleTime" SG_ 1089 BUILD0 1000;
BA_ "GenSigCycleTime" SG_ 1089 BUILD1 1000;
BA_ "GenSigCycleTime" SG_ 1089 BUILD2 1000;
BA_ "GenSigCycleTime" SG_ 1089 BUILD3 1000;

// SPRAYER_CMD ATTRIBUTES
BA_ "GenMsgCycleTime" BO_ 312 100;
BA_ "GenSigCycleTime" SG_ 312 ENABLE 100;
BA_ "GenSigCycleTime" SG_ 312 IGNORE_OVERRIDES 100;
BA_ "GenSigCycleTime" SG_ 312 CLEAR_OVERRIDE 100;
BA_ "GenSigCycleTime" SG_ 312 SPRAYER_CMD 100;

// SPRAYER_RPT ATTRIBUTES
BA_ "GenMsgCycleTime" BO_ 568 100;
BA_ "GenSigCycleTime" SG_ 568 ENABLED 100;
BA_ "GenSigCycleTime" SG_ 568 OVERRIDE_ACTIVE 100;
BA_ "GenSigCycleTime" SG_ 568 COMMAND_OUTPUT_FAULT 100;
BA_ "GenSigCycleTime" SG_ 568 INPUT_OUTPUT_FAULT 100;
BA_ "GenSigCycleTime" SG_ 568 OUTPUT_REPORTED_FAULT 100;
BA_ "GenSigCycleTime" SG_ 568 PACMOD_FAULT 100;
BA_ "GenSigCycleTime" SG_ 568 VEHICLE_FAULT 100;
BA_ "GenSigCycleTime" SG_ 568 COMMAND_TIMEOUT 100;
BA_ "GenSigCycleTime" SG_ 568 MANUAL_INPUT 100;
BA_ "GenSigCycleTime" SG_ 568 COMMANDED_VALUE 100;
BA_ "GenSigCycleTime" SG_ 568 OUTPUT_VALUE 100;

// TIPPER_BODY_AUX_RPT_00 ATTRIBUTES
BA_ "GenMsgCycleTime" BO_ 856 250;
BA_ "GenSigCycleTime" SG_ 856 DOOR_ANGLE 250;
BA_ "GenSigCycleTime" SG_ 856 BODY_ANGLE 250;
BA_ "GenSigCycleTime" SG_ 856 DOOR_FULLY_OPEN 250;
BA_ "GenSigCycleTime" SG_ 856 DOOR_FULLY_CLOSED 250;
BA_ "GenSigCycleTime" SG_ 856 BODY_FULLY_LOWERED 250;
BA_ "GenSigCycleTime" SG_ 856 BODY_FULLY_RAISED 250;

// TIPPER_BODY_AUX_RPT_01 ATTRIBUTES
BA_ "GenMsgCycleTime" BO_ 876 250;
BA_ "GenSigCycleTime" SG_ 876 DOOR_ANGLE 250;
BA_ "GenSigCycleTime" SG_ 876 BODY_ANGLE 250;
BA_ "GenSigCycleTime" SG_ 876 DOOR_FULLY_OPEN 250;
BA_ "GenSigCycleTime" SG_ 876 DOOR_FULLY_CLOSED 250;
BA_ "GenSigCycleTime" SG_ 876 BODY_FULLY_LOWERED 250;
BA_ "GenSigCycleTime" SG_ 876 BODY_FULLY_RAISED 250;

// TIPPER_BODY_AUX_RPT_02 ATTRIBUTES
BA_ "GenMsgCycleTime" BO_ 880 250;
BA_ "GenSigCycleTime" SG_ 880 DOOR_ANGLE 250;
BA_ "GenSigCycleTime" SG_ 880 BODY_ANGLE 250;
BA_ "GenSigCycleTime" SG_ 880 DOOR_FULLY_OPEN 250;
BA_ "GenSigCycleTime" SG_ 880 DOOR_FULLY_CLOSED 250;
BA_ "GenSigCycleTime" SG_ 880 BODY_FULLY_LOWERED 250;
BA_ "GenSigCycleTime" SG_ 880 BODY_FULLY_RAISED 250;

// TIPPER_BODY_CMD_00 ATTRIBUTES
BA_ "GenMsgCycleTime" BO_ 344 100;
BA_ "GenSigCycleTime" SG_ 344 ENABLE 100;
BA_ "GenSigCycleTime" SG_ 344 IGNORE_OVERRIDES 100;
BA_ "GenSigCycleTime" SG_ 344 CLEAR_OVERRIDE 100;
BA_ "GenSigCycleTime" SG_ 344 TIPPER_CONTROL_CMD 100;

// TIPPER_BODY_CMD_01 ATTRIBUTES
BA_ "GenMsgCycleTime" BO_ 364 100;
BA_ "GenSigCycleTime" SG_ 364 ENABLE 100;
BA_ "GenSigCycleTime" SG_ 364 IGNORE_OVERRIDES 100;
BA_ "GenSigCycleTime" SG_ 364 CLEAR_OVERRIDE 100;
BA_ "GenSigCycleTime" SG_ 364 TIPPER_CONTROL_CMD 100;

// TIPPER_BODY_CMD_02 ATTRIBUTES
BA_ "GenMsgCycleTime" BO_ 368 100;
BA_ "GenSigCycleTime" SG_ 368 ENABLE 100;
BA_ "GenSigCycleTime" SG_ 368 IGNORE_OVERRIDES 100;
BA_ "GenSigCycleTime" SG_ 368 CLEAR_OVERRIDE 100;
BA_ "GenSigCycleTime" SG_ 368 TIPPER_CONTROL_CMD 100;

// TIPPER_BODY_RPT_00 ATTRIBUTES
BA_ "GenMsgCycleTime" BO_ 600 100;
BA_ "GenSigCycleTime" SG_ 600 ENABLED 100;
BA_ "GenSigCycleTime" SG_ 600 OVERRIDE_ACTIVE 100;
BA_ "GenSigCycleTime" SG_ 600 COMMAND_OUTPUT_FAULT 100;
BA_ "GenSigCycleTime" SG_ 600 INPUT_OUTPUT_FAULT 100;
BA_ "GenSigCycleTime" SG_ 600 OUTPUT_REPORTED_FAULT 100;
BA_ "GenSigCycleTime" SG_ 600 PACMOD_FAULT 100;
BA_ "GenSigCycleTime" SG_ 600 VEHICLE_FAULT 100;
BA_ "GenSigCycleTime" SG_ 600 COMMAND_TIMEOUT 100;
BA_ "GenSigCycleTime" SG_ 600 MANUAL_INPUT 100;
BA_ "GenSigCycleTime" SG_ 600 COMMANDED_VALUE 100;
BA_ "GenSigCycleTime" SG_ 600 OUTPUT_VALUE 100;
BA_ "GenSigCycleTime" SG_ 600 CONTROL_STATUS 100;
BA_ "GenSigCycleTime" SG_ 600 CONTROLLING_SYSTEMS 100;
BA_ "GenSigCycleTime" SG_ 600 PERFORMANCE_STATUS 100;

// TIPPER_BODY_RPT_01 ATTRIBUTES
BA_ "GenMsgCycleTime" BO_ 620 100;
BA_ "GenSigCycleTime" SG_ 620 ENABLED 100;
BA_ "GenSigCycleTime" SG_ 620 OVERRIDE_ACTIVE 100;
BA_ "GenSigCycleTime" SG_ 620 COMMAND_OUTPUT_FAULT 100;
BA_ "GenSigCycleTime" SG_ 620 INPUT_OUTPUT_FAULT 100;
BA_ "GenSigCycleTime" SG_ 620 OUTPUT_REPORTED_FAULT 100;
BA_ "GenSigCycleTime" SG_ 620 PACMOD_FAULT 100;
BA_ "GenSigCycleTime" SG_ 620 VEHICLE_FAULT 100;
BA_ "GenSigCycleTime" SG_ 620 COMMAND_TIMEOUT 100;
BA_ "GenSigCycleTime" SG_ 620 MANUAL_INPUT 100;
BA_ "GenSigCycleTime" SG_ 620 COMMANDED_VALUE 100;
BA_ "GenSigCycleTime" SG_ 620 OUTPUT_VALUE 100;
BA_ "GenSigCycleTime" SG_ 620 CONTROL_STATUS 100;
BA_ "GenSigCycleTime" SG_ 620 CONTROLLING_SYSTEMS 100;
BA_ "GenSigCycleTime" SG_ 620 PERFORMANCE_STATUS 100;

// TIPPER_BODY_RPT_02 ATTRIBUTES
BA_ "GenMsgCycleTime" BO_ 624 100;
BA_ "GenSigCycleTime" SG_ 624 ENABLED 100;
BA_ "GenSigCycleTime" SG_ 624 OVERRIDE_ACTIVE 100;
BA_ "GenSigCycleTime" SG_ 624 COMMAND_OUTPUT_FAULT 100;
BA_ "GenSigCycleTime" SG_ 624 INPUT_OUTPUT_FAULT 100;
BA_ "GenSigCycleTime" SG_ 624 OUTPUT_REPORTED_FAULT 100;
BA_ "GenSigCycleTime" SG_ 624 PACMOD_FAULT 100;
BA_ "GenSigCycleTime" SG_ 624 VEHICLE_FAULT 100;
BA_ "GenSigCycleTime" SG_ 624 COMMAND_TIMEOUT 100;
BA_ "GenSigCycleTime" SG_ 624 MANUAL_INPUT 100;
BA_ "GenSigCycleTime" SG_ 624 COMMANDED_VALUE 100;
BA_ "GenSigCycleTime" SG_ 624 OUTPUT_VALUE 100;
BA_ "GenSigCycleTime" SG_ 624 CONTROL_STATUS 100;
BA_ "GenSigCycleTime" SG_ 624 CONTROLLING_SYSTEMS 100;
BA_ "GenSigCycleTime" SG_ 624 PERFORMANCE_STATUS 100;

// TIRE_PRESSURE_EXTENDED_RPT ATTRIBUTES
BA_ "GenMsgCycleTime" BO_ 1072 500;
BA_ "GenSigCycleTime" SG_ 1072 TIRE_CHASSIS_INDEX_1 500;
BA_ "GenSigCycleTime" SG_ 1072 TIRE_AXLE_1 500;
BA_ "GenSigCycleTime" SG_ 1072 TIRE_POSITION_1 500;
BA_ "GenSigCycleTime" SG_ 1072 TIRE_PRESSURE_1 500;
BA_ "GenSigCycleTime" SG_ 1072 TIRE_CHASSIS_INDEX_2 500;
BA_ "GenSigCycleTime" SG_ 1072 TIRE_AXLE_2 500;
BA_ "GenSigCycleTime" SG_ 1072 TIRE_POSITION_2 500;
BA_ "GenSigCycleTime" SG_ 1072 TIRE_PRESSURE_2 500;
BA_ "GenSigCycleTime" SG_ 1072 TIRE_CHASSIS_INDEX_3 500;
BA_ "GenSigCycleTime" SG_ 1072 TIRE_AXLE_3 500;
BA_ "GenSigCycleTime" SG_ 1072 TIRE_POSITION_3 500;
BA_ "GenSigCycleTime" SG_ 1072 TIRE_PRESSURE_3 500;

// TIRE_PRESSURE_EXTENDED_RPT_2 ATTRIBUTES
BA_ "GenMsgCycleTime" BO_ 1073 500;
BA_ "GenSigCycleTime" SG_ 1073 TIRE_CHASSIS_INDEX_1 500;
BA_ "GenSigCycleTime" SG_ 1073 TIRE_AXLE_1 500;
BA_ "GenSigCycleTime" SG_ 1073 TIRE_POSITION_1 500;
BA_ "GenSigCycleTime" SG_ 1073 TIRE_PRESSURE_1 500;
BA_ "GenSigCycleTime" SG_ 1073 TIRE_CHASSIS_INDEX_2 500;
BA_ "GenSigCycleTime" SG_ 1073 TIRE_AXLE_2 500;
BA_ "GenSigCycleTime" SG_ 1072 TIRE_POSITION_2 500;
BA_ "GenSigCycleTime" SG_ 1073 TIRE_PRESSURE_2 500;
BA_ "GenSigCycleTime" SG_ 1073 TIRE_CHASSIS_INDEX_3 500;
BA_ "GenSigCycleTime" SG_ 1073 TIRE_AXLE_3 500;
BA_ "GenSigCycleTime" SG_ 1073 TIRE_POSITION_3 500;
BA_ "GenSigCycleTime" SG_ 1073 TIRE_PRESSURE_3 500;

// TIRE_PRESSURE_RPT ATTRIBUTES
BA_ "GenMsgCycleTime" BO_ 1054 100;
BA_ "GenSigCycleTime" SG_ 1054 FRONT_LEFT_TIRE_PRESSURE 100;
BA_ "GenSigCycleTime" SG_ 1054 FRONT_RIGHT_TIRE_PRESSURE 100;
BA_ "GenSigCycleTime" SG_ 1054 REAR_LEFT_TIRE_PRESSURE 100;
BA_ "GenSigCycleTime" SG_ 1054 REAR_RIGHT_TIRE_PRESSURE 100;

// TIRE_TEMPERATURE_EXTENDED_RPT ATTRIBUTES
BA_ "GenMsgCycleTime" BO_ 1074 500;
BA_ "GenSigCycleTime" SG_ 1074 TIRE_CHASSIS_INDEX_1 500;
BA_ "GenSigCycleTime" SG_ 1074 TIRE_AXLE_1 500;
BA_ "GenSigCycleTime" SG_ 1074 TIRE_POSITION_1 500;
BA_ "GenSigCycleTime" SG_ 1074 TIRE_TEMPERATURE_1 500;
BA_ "GenSigCycleTime" SG_ 1074 TIRE_CHASSIS_INDEX_2 500;
BA_ "GenSigCycleTime" SG_ 1074 TIRE_AXLE_2 500;
BA_ "GenSigCycleTime" SG_ 1074 TIRE_POSITION_2 500;
BA_ "GenSigCycleTime" SG_ 1074 TIRE_TEMPERATURE_2 500;
BA_ "GenSigCycleTime" SG_ 1074 TIRE_CHASSIS_INDEX_3 500;
BA_ "GenSigCycleTime" SG_ 1074 TIRE_AXLE_3 500;
BA_ "GenSigCycleTime" SG_ 1074 TIRE_POSITION_3 500;
BA_ "GenSigCycleTime" SG_ 1074 TIRE_TEMPERATURE_3 500;

// TIRE_TEMPERATURE_EXTENDED_RPT_2 ATTRIBUTES
BA_ "GenMsgCycleTime" BO_ 1075 500;
BA_ "GenSigCycleTime" SG_ 1075 TIRE_CHASSIS_INDEX_1 500;
BA_ "GenSigCycleTime" SG_ 1075 TIRE_AXLE_1 500;
BA_ "GenSigCycleTime" SG_ 1075 TIRE_POSITION_1 500;
BA_ "GenSigCycleTime" SG_ 1075 TIRE_TEMPERATURE_1 500;
BA_ "GenSigCycleTime" SG_ 1075 TIRE_CHASSIS_INDEX_2 500;
BA_ "GenSigCycleTime" SG_ 1075 TIRE_AXLE_2 500;
BA_ "GenSigCycleTime" SG_ 1075 TIRE_POSITION_2 500;
BA_ "GenSigCycleTime" SG_ 1075 TIRE_TEMPERATURE_2 500;
BA_ "GenSigCycleTime" SG_ 1075 TIRE_CHASSIS_INDEX_3 500;
BA_ "GenSigCycleTime" SG_ 1075 TIRE_AXLE_3 500;
BA_ "GenSigCycleTime" SG_ 1075 TIRE_POSITION_3 500;
BA_ "GenSigCycleTime" SG_ 1075 TIRE_TEMPERATURE_3 500;

// TRAILER_BRAKE_PRESSURE_RPT_00 ATTRIBUTES
BA_ "GenMsgCycleTime" BO_ 1064 100;
BA_ "GenSigCycleTime" SG_ 1064 BRAKE_PRESSURE_AXLE_1_LEFT 100;
BA_ "GenSigCycleTime" SG_ 1064 BRAKE_PRESSURE_AXLE_1_RIGHT 100;
BA_ "GenSigCycleTime" SG_ 1064 BRAKE_PRESSURE_AXLE_2_LEFT 100;
BA_ "GenSigCycleTime" SG_ 1064 BRAKE_PRESSURE_AXLE_2_RIGHT 100;
BA_ "GenSigCycleTime" SG_ 1064 BRAKE_PRESSURE_AXLE_3_LEFT 100;
BA_ "GenSigCycleTime" SG_ 1064 BRAKE_PRESSURE_AXLE_3_RIGHT 100;
BA_ "GenSigCycleTime" SG_ 1064 PNEUMATIC_SUPPLY_PRESSURE 100;

// TRAILER_BRAKE_PRESSURE_RPT_01 ATTRIBUTES
BA_ "GenMsgCycleTime" BO_ 1065 100;
BA_ "GenSigCycleTime" SG_ 1065 BRAKE_PRESSURE_AXLE_1_LEFT 100;
BA_ "GenSigCycleTime" SG_ 1065 BRAKE_PRESSURE_AXLE_1_RIGHT 100;
BA_ "GenSigCycleTime" SG_ 1065 BRAKE_PRESSURE_AXLE_2_LEFT 100;
BA_ "GenSigCycleTime" SG_ 1065 BRAKE_PRESSURE_AXLE_2_RIGHT 100;
BA_ "GenSigCycleTime" SG_ 1065 BRAKE_PRESSURE_AXLE_3_LEFT 100;
BA_ "GenSigCycleTime" SG_ 1065 BRAKE_PRESSURE_AXLE_3_RIGHT 100;
BA_ "GenSigCycleTime" SG_ 1065 PNEUMATIC_SUPPLY_PRESSURE 100;

// TRAILER_BRAKE_PRESSURE_RPT_02 ATTRIBUTES
BA_ "GenMsgCycleTime" BO_ 1066 100;
BA_ "GenSigCycleTime" SG_ 1066 BRAKE_PRESSURE_AXLE_1_LEFT 100;
BA_ "GenSigCycleTime" SG_ 1066 BRAKE_PRESSURE_AXLE_1_RIGHT 100;
BA_ "GenSigCycleTime" SG_ 1066 BRAKE_PRESSURE_AXLE_2_LEFT 100;
BA_ "GenSigCycleTime" SG_ 1066 BRAKE_PRESSURE_AXLE_2_RIGHT 100;
BA_ "GenSigCycleTime" SG_ 1066 BRAKE_PRESSURE_AXLE_3_LEFT 100;
BA_ "GenSigCycleTime" SG_ 1066 BRAKE_PRESSURE_AXLE_3_RIGHT 100;
BA_ "GenSigCycleTime" SG_ 1066 PNEUMATIC_SUPPLY_PRESSURE 100;

// TRAILER_BRAKE_PRESSURE_RPT_03 ATTRIBUTES
BA_ "GenMsgCycleTime" BO_ 1067 100;
BA_ "GenSigCycleTime" SG_ 1067 BRAKE_PRESSURE_AXLE_1_LEFT 100;
BA_ "GenSigCycleTime" SG_ 1067 BRAKE_PRESSURE_AXLE_1_RIGHT 100;
BA_ "GenSigCycleTime" SG_ 1067 BRAKE_PRESSURE_AXLE_2_LEFT 100;
BA_ "GenSigCycleTime" SG_ 1067 BRAKE_PRESSURE_AXLE_2_RIGHT 100;
BA_ "GenSigCycleTime" SG_ 1067 BRAKE_PRESSURE_AXLE_3_LEFT 100;
BA_ "GenSigCycleTime" SG_ 1067 BRAKE_PRESSURE_AXLE_3_RIGHT 100;
BA_ "GenSigCycleTime" SG_ 1067 PNEUMATIC_SUPPLY_PRESSURE 100;

// TRAILER_BRAKE_PRESSURE_RPT_04 ATTRIBUTES
BA_ "GenMsgCycleTime" BO_ 1068 100;
BA_ "GenSigCycleTime" SG_ 1068 BRAKE_PRESSURE_AXLE_1_LEFT 100;
BA_ "GenSigCycleTime" SG_ 1068 BRAKE_PRESSURE_AXLE_1_RIGHT 100;
BA_ "GenSigCycleTime" SG_ 1068 BRAKE_PRESSURE_AXLE_2_LEFT 100;
BA_ "GenSigCycleTime" SG_ 1068 BRAKE_PRESSURE_AXLE_2_RIGHT 100;
BA_ "GenSigCycleTime" SG_ 1068 BRAKE_PRESSURE_AXLE_3_LEFT 100;
BA_ "GenSigCycleTime" SG_ 1068 BRAKE_PRESSURE_AXLE_3_RIGHT 100;
BA_ "GenSigCycleTime" SG_ 1068 PNEUMATIC_SUPPLY_PRESSURE 100;

// TRAILER_FAULT_RPT_00 ATTRIBUTES
BA_ "GenMsgCycleTime" BO_ 1084 100;
BA_ "GenSigCycleTime" SG_ 1084 SERVICE_BRAKE_STATUS 100;
BA_ "GenSigCycleTime" SG_ 1084 ABS_STATUS 100;
BA_ "GenSigCycleTime" SG_ 1084 ELECTRICAL_SUPPLY_STATUS 100;
BA_ "GenSigCycleTime" SG_ 1084 PNEUMATIC_SUPPLY_STATUS 100;
BA_ "GenSigCycleTime" SG_ 1084 AMBER_WARNING_LAMP_REQUEST 100;
BA_ "GenSigCycleTime" SG_ 1084 RED_WARNING_LAMP_REQUEST 100;

// TRAILER_FAULT_RPT_01 ATTRIBUTES
BA_ "GenMsgCycleTime" BO_ 1085 100;
BA_ "GenSigCycleTime" SG_ 1085 SERVICE_BRAKE_STATUS 100;
BA_ "GenSigCycleTime" SG_ 1085 ABS_STATUS 100;
BA_ "GenSigCycleTime" SG_ 1085 ELECTRICAL_SUPPLY_STATUS 100;
BA_ "GenSigCycleTime" SG_ 1085 PNEUMATIC_SUPPLY_STATUS 100;
BA_ "GenSigCycleTime" SG_ 1085 AMBER_WARNING_LAMP_REQUEST 100;
BA_ "GenSigCycleTime" SG_ 1085 RED_WARNING_LAMP_REQUEST 100;

// TRAILER_FAULT_RPT_02 ATTRIBUTES
BA_ "GenMsgCycleTime" BO_ 1086 100;
BA_ "GenSigCycleTime" SG_ 1086 SERVICE_BRAKE_STATUS 100;
BA_ "GenSigCycleTime" SG_ 1086 ABS_STATUS 100;
BA_ "GenSigCycleTime" SG_ 1086 ELECTRICAL_SUPPLY_STATUS 100;
BA_ "GenSigCycleTime" SG_ 1086 PNEUMATIC_SUPPLY_STATUS 100;
BA_ "GenSigCycleTime" SG_ 1086 AMBER_WARNING_LAMP_REQUEST 100;
BA_ "GenSigCycleTime" SG_ 1086 RED_WARNING_LAMP_REQUEST 100;

// TRAILER_FAULT_RPT_03 ATTRIBUTES
BA_ "GenMsgCycleTime" BO_ 1087 100;
BA_ "GenSigCycleTime" SG_ 1087 SERVICE_BRAKE_STATUS 100;
BA_ "GenSigCycleTime" SG_ 1087 ABS_STATUS 100;
BA_ "GenSigCycleTime" SG_ 1087 ELECTRICAL_SUPPLY_STATUS 100;
BA_ "GenSigCycleTime" SG_ 1087 PNEUMATIC_SUPPLY_STATUS 100;
BA_ "GenSigCycleTime" SG_ 1087 AMBER_WARNING_LAMP_REQUEST 100;
BA_ "GenSigCycleTime" SG_ 1087 RED_WARNING_LAMP_REQUEST 100;

// TRAILER_FAULT_RPT_04 ATTRIBUTES
BA_ "GenMsgCycleTime" BO_ 1088 100;
BA_ "GenSigCycleTime" SG_ 1088 SERVICE_BRAKE_STATUS 100;
BA_ "GenSigCycleTime" SG_ 1088 ABS_STATUS 100;
BA_ "GenSigCycleTime" SG_ 1088 ELECTRICAL_SUPPLY_STATUS 100;
BA_ "GenSigCycleTime" SG_ 1088 PNEUMATIC_SUPPLY_STATUS 100;
BA_ "GenSigCycleTime" SG_ 1088 AMBER_WARNING_LAMP_REQUEST 100;
BA_ "GenSigCycleTime" SG_ 1088 RED_WARNING_LAMP_REQUEST 100;

// TRAILER_IDENTIFIER_RPT_00 ATTRIBUTES
BA_ "GenMsgCycleTime" BO_ 1095 5000;
BA_ "GenSigCycleTime" SG_ 1095 TRAILER_IDENTIFIER 5000;

// TRAILER_IDENTIFIER_RPT_01 ATTRIBUTES
BA_ "GenMsgCycleTime" BO_ 1096 5000;
BA_ "GenSigCycleTime" SG_ 1096 TRAILER_IDENTIFIER 5000;

// TRAILER_IDENTIFIER_RPT_02 ATTRIBUTES
BA_ "GenMsgCycleTime" BO_ 1097 5000;
BA_ "GenSigCycleTime" SG_ 1097 TRAILER_IDENTIFIER 5000;

// TRAILER_IDENTIFIER_RPT_03 ATTRIBUTES
BA_ "GenMsgCycleTime" BO_ 1098 5000;
BA_ "GenSigCycleTime" SG_ 1098 TRAILER_IDENTIFIER 5000;

// TRAILER_IDENTIFIER_RPT_04 ATTRIBUTES
BA_ "GenMsgCycleTime" BO_ 1099 5000;
BA_ "GenSigCycleTime" SG_ 1099 TRAILER_IDENTIFIER 5000;

// TRAILER_IDENTIFIER_RPT_05 ATTRIBUTES
BA_ "GenMsgCycleTime" BO_ 1106 5000;
BA_ "GenSigCycleTime" SG_ 1106 TRAILER_IDENTIFIER 5000;

// TRAILER_PAYLOAD_RPT_00 ATTRIBUTES
BA_ "GenMsgCycleTime" BO_ 1078 250;
BA_ "GenSigCycleTime" SG_ 1078 PAYLOAD_00 250;
BA_ "GenSigCycleTime" SG_ 1078 TARE_00 250;
BA_ "GenSigCycleTime" SG_ 1078 PAYLOAD_01 250;
BA_ "GenSigCycleTime" SG_ 1078 TARE_01 250;

// TRAILER_PAYLOAD_RPT_01 ATTRIBUTES
BA_ "GenMsgCycleTime" BO_ 1079 250;
BA_ "GenSigCycleTime" SG_ 1079 PAYLOAD_00 250;
BA_ "GenSigCycleTime" SG_ 1079 TARE_00 250;
BA_ "GenSigCycleTime" SG_ 1079 PAYLOAD_01 250;
BA_ "GenSigCycleTime" SG_ 1079 TARE_01 250;

// TRAILER_PAYLOAD_RPT_02 ATTRIBUTES
BA_ "GenMsgCycleTime" BO_ 1079 250;
BA_ "GenSigCycleTime" SG_ 1079 PAYLOAD_00 250;
BA_ "GenSigCycleTime" SG_ 1079 TARE_00 250;
BA_ "GenSigCycleTime" SG_ 1079 PAYLOAD_01 250;
BA_ "GenSigCycleTime" SG_ 1079 TARE_01 250;

// TURN_AUX_RPT ATTRIBUTES
BA_ "GenMsgCycleTime" BO_ 816 100;
BA_ "GenSigCycleTime" SG_ 816 DRIVER_BLINKER_BULB_ON 100;
BA_ "GenSigCycleTime" SG_ 816 PASS_BLINKER_BULB_ON 100;
BA_ "GenSigCycleTime" SG_ 816 DRIVER_BLINKER_BULB_ON_AVAIL 100;
BA_ "GenSigCycleTime" SG_ 816 PASS_BLINKER_BULB_ON_AVAIL 100;

// TURN_CMD ATTRIBUTES
BA_ "GenMsgCycleTime" BO_ 304 100;
BA_ "GenSigCycleTime" SG_ 304 ENABLE 100;
BA_ "GenSigCycleTime" SG_ 304 IGNORE_OVERRIDES 100;
BA_ "GenSigCycleTime" SG_ 304 CLEAR_OVERRIDE 100;
BA_ "GenSigCycleTime" SG_ 304 TURN_SIGNAL_CMD 100;

// TURN_RPT ATTRIBUTES
BA_ "GenMsgCycleTime" BO_ 560 100;
BA_ "GenSigCycleTime" SG_ 560 ENABLED 100;
BA_ "GenSigCycleTime" SG_ 560 OVERRIDE_ACTIVE 100;
BA_ "GenSigCycleTime" SG_ 560 COMMAND_OUTPUT_FAULT 100;
BA_ "GenSigCycleTime" SG_ 560 INPUT_OUTPUT_FAULT 100;
BA_ "GenSigCycleTime" SG_ 560 OUTPUT_REPORTED_FAULT 100;
BA_ "GenSigCycleTime" SG_ 560 PACMOD_FAULT 100;
BA_ "GenSigCycleTime" SG_ 560 VEHICLE_FAULT 100;
BA_ "GenSigCycleTime" SG_ 560 COMMAND_TIMEOUT 100;
BA_ "GenSigCycleTime" SG_ 560 MANUAL_INPUT 100;
BA_ "GenSigCycleTime" SG_ 560 COMMANDED_VALUE 100;
BA_ "GenSigCycleTime" SG_ 560 OUTPUT_VALUE 100;

// USER_NOTIFICATION_CMD ATTRIBUTES
BA_ "GenMsgCycleTime" BO_ 1053 250;
BA_ "GenSigCycleTime" SG_ 1053 BUZZER_MUTE 250;
BA_ "GenSigCycleTime" SG_ 1053 LIGHT_COMMAND 250;
BA_ "GenSigCycleTime" SG_ 1053 BUZZER_ON 250;
BA_ "GenSigCycleTime" SG_ 1053 BUZZER_MUTE_INDICATOR 250;
BA_ "GenSigCycleTime" SG_ 1053 LED_BRIGHTNESS 250;
BA_ "GenSigCycleTime" SG_ 1053 LIGHT_STATUS_COMMAND 250;
BA_ "GenSigCycleTime" SG_ 1053 LIGHT_COMMAND_ALTERNATE 250;

// VEHICLE_FAULT_RPT_2 ATTRIBUTES
BA_ "GenMsgCycleTime" BO_ 1083 100;
BA_ "GenSigCycleTime" SG_ 1083 BRAKES_AMBER_LAMP 100;
BA_ "GenSigCycleTime" SG_ 1083 BRAKES_RED_LAMP 100;
BA_ "GenSigCycleTime" SG_ 1083 CHASSIS_AMBER_LAMP 100;
BA_ "GenSigCycleTime" SG_ 1083 CHASSIS_RED_LAMP 100;
BA_ "GenSigCycleTime" SG_ 1083 ELECTRONIC_BRAKES_AMBER_LAMP 100;
BA_ "GenSigCycleTime" SG_ 1083 ELECTRONIC_BRAKES_RED_LAMP 100;
BA_ "GenSigCycleTime" SG_ 1083 ENGINE_AMBER_LAMP 100;
BA_ "GenSigCycleTime" SG_ 1083 ENGINE_RED_LAMP 100;
BA_ "GenSigCycleTime" SG_ 1083 ENGINE_BRAKE_AMBER_LAMP 100;
BA_ "GenSigCycleTime" SG_ 1083 ENGINE_BRAKE_RED_LAMP 100;
BA_ "GenSigCycleTime" SG_ 1083 MANAGEMENT_ECU_AMBER_LAMP 100;
BA_ "GenSigCycleTime" SG_ 1083 MANAGEMENT_ECU_RED_LAMP 100;
BA_ "GenSigCycleTime" SG_ 1083 PNEUMATIC_AMBER_LAMP 100;
BA_ "GenSigCycleTime" SG_ 1083 PNEUMATIC_RED_LAMP 100;
BA_ "GenSigCycleTime" SG_ 1083 RESTRAINTS_AMBER_LAMP 100;
BA_ "GenSigCycleTime" SG_ 1083 RESTRAINTS_RED_LAMP 100;
BA_ "GenSigCycleTime" SG_ 1083 TRAILER_ABS_AMBER_LAMP 100;
BA_ "GenSigCycleTime" SG_ 1083 TRAILER_ABS_RED_LAMP 100;
BA_ "GenSigCycleTime" SG_ 1083 TRANSMISSION_AMBER_LAMP 100;
BA_ "GenSigCycleTime" SG_ 1083 TRANSMISSION_RED_LAMP 100;

// VIN_RPT ATTRIBUTES
BA_ "GenMsgCycleTime" BO_ 1044 1000;
BA_ "GenSigCycleTime" SG_ 1044 VEH_SERIAL 1000;
BA_ "GenSigCycleTime" SG_ 1044 VEH_MY_CODE 1000;
BA_ "GenSigCycleTime" SG_ 1044 VEH_MFG_CODE 1000;

// VIN_RPT_2 ATTRIBUTES
BA_ "GenMsgCycleTime" BO_ 1058 1000;
BA_ "GenSigCycleTime" SG_ 1058 VEHICLE_IDENTIFIER_SECTION_10 1000;
BA_ "GenSigCycleTime" SG_ 1058 VEHICLE_IDENTIFIER_SECTION_11 1000;
BA_ "GenSigCycleTime" SG_ 1058 VEHICLE_IDENTIFIER_SECTION_12 1000;
BA_ "GenSigCycleTime" SG_ 1058 VEHICLE_IDENTIFIER_SECTION_13 1000;
BA_ "GenSigCycleTime" SG_ 1058 VEHICLE_IDENTIFIER_SECTION_14 1000;
BA_ "GenSigCycleTime" SG_ 1058 VEHICLE_IDENTIFIER_SECTION_15 1000;
BA_ "GenSigCycleTime" SG_ 1058 VEHICLE_IDENTIFIER_SECTION_16 1000;
BA_ "GenSigCycleTime" SG_ 1058 VEHICLE_IDENTIFIER_SECTION_17 1000;

// WATCHDOG_RPT ATTRIBUTES
BA_ "GenMsgCycleTime" BO_ 1536 100;
BA_ "GenSigCycleTime" SG_ 1536 GLOBAL_ENABLE_FLAG 100;
BA_ "GenSigCycleTime" SG_ 1536 GLOBAL_OVERRIDE_ACTIVE 100;
BA_ "GenSigCycleTime" SG_ 1536 GLOBAL_COMMAND_TIMEOUT_ERROR 100;
BA_ "GenSigCycleTime" SG_ 1536 GLOBAL_PACMOD_SUBSYSTEM_TIMEOUT 100;
BA_ "GenSigCycleTime" SG_ 1536 GLOBAL_VEHICLE_CAN_TIMEOUT 100;
BA_ "GenSigCycleTime" SG_ 1536 GLOBAL_PACMOD_SYS_FAULT_ACTIVE 100;
BA_ "GenSigCycleTime" SG_ 1536 GLOBAL_CONFIG_FAULT_ACTIVE 100;
BA_ "GenSigCycleTime" SG_ 1536 GLOBAL_TIMEOUT 100;
BA_ "GenSigCycleTime" SG_ 1536 ACCEL_ENABLED 100;
BA_ "GenSigCycleTime" SG_ 1536 ACCEL_OVERRIDE_ACTIVE 100;
BA_ "GenSigCycleTime" SG_ 1536 ACCEL_COMMAND_OUTPUT_FAULT 100;
BA_ "GenSigCycleTime" SG_ 1536 ACCEL_INPUT_OUTPUT_FAULT 100;
BA_ "GenSigCycleTime" SG_ 1536 ACCEL_OUTPUT_REPORTED_FAULT 100;
BA_ "GenSigCycleTime" SG_ 1536 ACCEL_PACMOD_FAULT 100;
BA_ "GenSigCycleTime" SG_ 1536 ACCEL_VEHICLE_FAULT 100;
BA_ "GenSigCycleTime" SG_ 1536 ACCEL_TIMEOUT 100;
BA_ "GenSigCycleTime" SG_ 1536 BRAKE_ENABLED 100;
BA_ "GenSigCycleTime" SG_ 1536 BRAKE_OVERRIDE_ACTIVE 100;
BA_ "GenSigCycleTime" SG_ 1536 BRAKE_COMMAND_OUTPUT_FAULT 100;
BA_ "GenSigCycleTime" SG_ 1536 BRAKE_INPUT_OUTPUT_FAULT 100;
BA_ "GenSigCycleTime" SG_ 1536 BRAKE_OUTPUT_REPORTED_FAULT 100;
BA_ "GenSigCycleTime" SG_ 1536 BRAKE_PACMOD_FAULT 100;
BA_ "GenSigCycleTime" SG_ 1536 BRAKE_VEHICLE_FAULT 100;
BA_ "GenSigCycleTime" SG_ 1536 BRAKE_TIMEOUT 100;
BA_ "GenSigCycleTime" SG_ 1536 SHIFT_ENABLED 100;
BA_ "GenSigCycleTime" SG_ 1536 SHIFT_OVERRIDE_ACTIVE 100;
BA_ "GenSigCycleTime" SG_ 1536 SHIFT_COMMAND_OUTPUT_FAULT 100;
BA_ "GenSigCycleTime" SG_ 1536 SHIFT_INPUT_OUTPUT_FAULT 100;
BA_ "GenSigCycleTime" SG_ 1536 SHIFT_OUTPUT_REPORTED_FAULT 100;
BA_ "GenSigCycleTime" SG_ 1536 SHIFT_PACMOD_FAULT 100;
BA_ "GenSigCycleTime" SG_ 1536 SHIFT_VEHICLE_FAULT 100;
BA_ "GenSigCycleTime" SG_ 1536 SHIFT_TIMEOUT 100;
BA_ "GenSigCycleTime" SG_ 1536 STEER_ENABLED 100;
BA_ "GenSigCycleTime" SG_ 1536 STEER_OVERRIDE_ACTIVE 100;
BA_ "GenSigCycleTime" SG_ 1536 STEER_COMMAND_OUTPUT_FAULT 100;
BA_ "GenSigCycleTime" SG_ 1536 STEER_INPUT_OUTPUT_FAULT 100;
BA_ "GenSigCycleTime" SG_ 1536 STEER_OUTPUT_REPORTED_FAULT 100;
BA_ "GenSigCycleTime" SG_ 1536 STEER_PACMOD_FAULT 100;
BA_ "GenSigCycleTime" SG_ 1536 STEER_VEHICLE_FAULT 100;
BA_ "GenSigCycleTime" SG_ 1536 STEER_TIMEOUT 100;
BA_ "GenSigCycleTime" SG_ 1536 PACMOD1_CONFIG_FAULT 100;
BA_ "GenSigCycleTime" SG_ 1536 PACMOD1_CAN_TIMEOUT 100;
BA_ "GenSigCycleTime" SG_ 1536 PACMOD1_COUNTER_FAULT 100;
BA_ "GenSigCycleTime" SG_ 1536 PACMOD2_CONFIG_FAULT 100;
BA_ "GenSigCycleTime" SG_ 1536 PACMOD2_CAN_TIMEOUT 100;
BA_ "GenSigCycleTime" SG_ 1536 PACMOD2_COUNTER_FAULT 100;
BA_ "GenSigCycleTime" SG_ 1536 PACMOD3_CONFIG_FAULT 100;
BA_ "GenSigCycleTime" SG_ 1536 PACMOD3_CAN_TIMEOUT 100;
BA_ "GenSigCycleTime" SG_ 1536 PACMOD3_COUNTER_FAULT 100;
BA_ "GenSigCycleTime" SG_ 1536 PACMINI1_RPT_TIMEOUT 100;
BA_ "GenSigCycleTime" SG_ 1536 PACMINI1_CONFIG_FAULT 100;
BA_ "GenSigCycleTime" SG_ 1536 PACMINI1_CAN_TIMEOUT 100;
BA_ "GenSigCycleTime" SG_ 1536 PACMINI1_COUNTER_FAULT 100;
BA_ "GenSigCycleTime" SG_ 1536 PACMINI2_RPT_TIMEOUT 100;
BA_ "GenSigCycleTime" SG_ 1536 PACMINI2_CONFIG_FAULT 100;
BA_ "GenSigCycleTime" SG_ 1536 PACMINI2_CAN_TIMEOUT 100;
BA_ "GenSigCycleTime" SG_ 1536 PACMINI2_COUNTER_FAULT 100;
BA_ "GenSigCycleTime" SG_ 1536 PACMINI3_RPT_TIMEOUT 100;
BA_ "GenSigCycleTime" SG_ 1536 PACMINI3_CONFIG_FAULT 100;
BA_ "GenSigCycleTime" SG_ 1536 PACMINI3_CAN_TIMEOUT 100;
BA_ "GenSigCycleTime" SG_ 1536 PACMINI3_COUNTER_FAULT 100;
BA_ "GenSigCycleTime" SG_ 1536 PACMOD_SYSTEM_PRESENT_FAULT 100;
BA_ "GenSigCycleTime" SG_ 1536 PACMINI_SYSTEM_PRESENT_FAULT 100;
BA_ "GenSigCycleTime" SG_ 1536 GLOBAL_INT_POWER_SUPPLY_FAULT 100;

// WATCHDOG_RPT_2 ATTRIBUTES
BA_ "GenMsgCycleTime" BO_ 1057 1000;
BA_ "GenSigCycleTime" SG_ 1057 ACCEL_RPT_TIMEOUT 1000;
BA_ "GenSigCycleTime" SG_ 1057 BRAKE_RPT_TIMEOUT 1000;
BA_ "GenSigCycleTime" SG_ 1057 BRAKE_DECEL_RPT_TIMEOUT 1000;
BA_ "GenSigCycleTime" SG_ 1057 CABIN_CLIMATE_RPT_TIMEOUT 1000;
BA_ "GenSigCycleTime" SG_ 1057 CABIN_FAN_SPEED_RPT_TIMEOUT 1000;
BA_ "GenSigCycleTime" SG_ 1057 CABIN_TEMP_RPT_TIMEOUT 1000;
BA_ "GenSigCycleTime" SG_ 1057 CRUISE_CONTROL_RPT_TIMEOUT 1000;
BA_ "GenSigCycleTime" SG_ 1057 DASH_LEFT_RPT_TIMEOUT 1000;
BA_ "GenSigCycleTime" SG_ 1057 DASH_RIGHT_RPT_TIMEOUT 1000;
BA_ "GenSigCycleTime" SG_ 1057 ENGINE_BRAKE_RPT_TIMEOUT 1000;
BA_ "GenSigCycleTime" SG_ 1057 HAZARD_LIGHTS_RPT_TIMEOUT 1000;
BA_ "GenSigCycleTime" SG_ 1057 HEADLIGHT_RPT_TIMEOUT 1000;
BA_ "GenSigCycleTime" SG_ 1057 HORN_RPT_TIMEOUT 1000;
BA_ "GenSigCycleTime" SG_ 1057 MARKER_LAMP_RPT_TIMEOUT 1000;
BA_ "GenSigCycleTime" SG_ 1057 MEDIA_CONTROLS_RPT_TIMEOUT 1000;
BA_ "GenSigCycleTime" SG_ 1057 PARKING_BRAKE_RPT_TIMEOUT 1000;
BA_ "GenSigCycleTime" SG_ 1057 REAR_PASS_DOOR_RPT_TIMEOUT 1000;
BA_ "GenSigCycleTime" SG_ 1057 SHIFT_RPT_TIMEOUT 1000;
BA_ "GenSigCycleTime" SG_ 1057 SPRAYER_RPT_TIMEOUT 1000;
BA_ "GenSigCycleTime" SG_ 1057 STEERING_RPT_TIMEOUT 1000;
BA_ "GenSigCycleTime" SG_ 1057 TURN_RPT_TIMEOUT 1000;
BA_ "GenSigCycleTime" SG_ 1057 WIPER_RPT_TIMEOUT 1000;
BA_ "GenSigCycleTime" SG_ 1057 PACMOD1_SANITY_FAULT 1000;
BA_ "GenSigCycleTime" SG_ 1057 PACMOD2_SANITY_FAULT 1000;
BA_ "GenSigCycleTime" SG_ 1057 PACMOD3_SANITY_FAULT 1000;
BA_ "GenSigCycleTime" SG_ 1057 PACMINI1_SANITY_FAULT 1000;
BA_ "GenSigCycleTime" SG_ 1057 PACMINI2_SANITY_FAULT 1000;
BA_ "GenSigCycleTime" SG_ 1057 PACMINI3_SANITY_FAULT 1000;
BA_ "GenSigCycleTime" SG_ 1057 PACMOD1_COMPONENT_RPT_TIMEOUT 1000;
BA_ "GenSigCycleTime" SG_ 1057 PACMOD2_COMPONENT_RPT_TIMEOUT 1000;
BA_ "GenSigCycleTime" SG_ 1057 PACMOD3_COMPONENT_RPT_TIMEOUT 1000;
BA_ "GenSigCycleTime" SG_ 1057 PACMINI1_COMPONENT_RPT_TIMEOUT 1000;
BA_ "GenSigCycleTime" SG_ 1057 PACMINI2_COMPONENT_RPT_TIMEOUT 1000;
BA_ "GenSigCycleTime" SG_ 1057 PACMINI3_COMPONENT_RPT_TIMEOUT 1000;
BA_ "GenSigCycleTime" SG_ 1057 PACMOD1_SYSTEM_PRESENT_FAULT 1000;
BA_ "GenSigCycleTime" SG_ 1057 PACMOD2_SYSTEM_PRESENT_FAULT 1000;
BA_ "GenSigCycleTime" SG_ 1057 PACMOD3_SYSTEM_PRESENT_FAULT 1000;
BA_ "GenSigCycleTime" SG_ 1057 PACMINI1_SYSTEM_PRESENT_FAULT 1000;
BA_ "GenSigCycleTime" SG_ 1057 PACMINI2_SYSTEM_PRESENT_FAULT 1000;
BA_ "GenSigCycleTime" SG_ 1057 PACMINI3_SYSTEM_PRESENT_FAULT 1000;
BA_ "GenSigCycleTime" SG_ 1057 DRIVE_MODE_INVALID 1000;
BA_ "GenSigCycleTime" SG_ 1057 GLOBAL_CMD_SANITY_FAULT 1000;
BA_ "GenSigCycleTime" SG_ 1057 GLOBAL_CMD_TIMEOUT 1000;
BA_ "GenSigCycleTime" SG_ 1057 EXHAUST_BRAKE_RPT_TIMEOUT 1000;
BA_ "GenSigCycleTime" SG_ 1057 POWER_TAKE_OFF_RPT_TIMEOUT 1000;
BA_ "GenSigCycleTime" SG_ 1057 TIPPER_BODY_00_RPT_TIMEOUT 1000;
BA_ "GenSigCycleTime" SG_ 1057 TRAILER_AIR_SUPPLY_RPT_TIMEOUT 1000;
BA_ "GenSigCycleTime" SG_ 1057 TRAILER_BRAKE_RPT_TIMEOUT 1000;
BA_ "GenSigCycleTime" SG_ 1057 ENGINE_RPT_TIMEOUT 1000;
BA_ "GenSigCycleTime" SG_ 1057 TIPPER_BODY_01_RPT_TIMEOUT 1000;
BA_ "GenSigCycleTime" SG_ 1057 TIPPER_BODY_02_RPT_TIMEOUT 1000;
BA_ "GenSigCycleTime" SG_ 1057 DIFFERENTIAL_LOCKS_RPT_TIMEOUT 1000;

// WIPER_AUX_RPT ATTRIBUTES
BA_ "GenMsgCycleTime" BO_ 820 100;
BA_ "GenSigCycleTime" SG_ 820 FRONT_WIPING 100;
BA_ "GenSigCycleTime" SG_ 820 REAR_WIPING 100;

// WIPER_CMD ATTRIBUTES
BA_ "GenMsgCycleTime" BO_ 308 100;
BA_ "GenSigCycleTime" SG_ 308 ENABLE 100;
BA_ "GenSigCycleTime" SG_ 308 IGNORE_OVERRIDES 100;
BA_ "GenSigCycleTime" SG_ 308 CLEAR_OVERRIDE 100;
BA_ "GenSigCycleTime" SG_ 308 WIPER_CMD 100;

// WIPER_RPT ATTRIBUTES
BA_ "GenMsgCycleTime" BO_ 564 100;
BA_ "GenSigCycleTime" SG_ 564 ENABLED 100;
BA_ "GenSigCycleTime" SG_ 564 OVERRIDE_ACTIVE 100;
BA_ "GenSigCycleTime" SG_ 564 COMMAND_OUTPUT_FAULT 100;
BA_ "GenSigCycleTime" SG_ 564 INPUT_OUTPUT_FAULT 100;
BA_ "GenSigCycleTime" SG_ 564 OUTPUT_REPORTED_FAULT 100;
BA_ "GenSigCycleTime" SG_ 564 PACMOD_FAULT 100;
BA_ "GenSigCycleTime" SG_ 564 VEHICLE_FAULT 100;
BA_ "GenSigCycleTime" SG_ 564 COMMAND_TIMEOUT 100;
BA_ "GenSigCycleTime" SG_ 564 MANUAL_INPUT 100;
BA_ "GenSigCycleTime" SG_ 564 COMMANDED_VALUE 100;
BA_ "GenSigCycleTime" SG_ 564 OUTPUT_VALUE 100;

// SAFETY_FUNC_RPT VALUES
VAL_ 64 COMMANDED_VALUE 0 "NONE" 1 "AUTOMS_READY" 2 "AUTOMS" 3 "MANUAL_READY" 4 "CRITICAL_STOP1" 5 "CRITICAL_STOP2" ;
VAL_ 64 STATE 0 "MANUAL_BRAKED" 1 "MANUAL_UNBRAKED" 2 "AUTOMS_READY" 3 "AUTOMS_INACTIVE" 4 "AUTOMS_ACTIVE_BRAKED" 5 "AUTOMS_ACTIVE_UNBRAKED" 6 "MANUAL_READY" 7 "CRITICAL_STOP1" 8 "CRITICAL_STOP2" 9 "STARTUP" ;
VAL_ 64 AUTOMS_MAN_OPCTRL 0 "INVALID" 1 "MANUAL" 2 "AUTOMS" ;
VAL_ 64 CABIN_SAFETY_BRAKE_OPCTRL 0 "INVALID" 1 "APPLIED" 2 "UNAPPLIED" ;
VAL_ 64 REMOTE_STOP_STATUS 0 "INVALID" 1 "GO" 2 "STOP" ;
VAL_ 64 ENGINE_STATUS 0 "NOT_RUNNING" 1 "RUNNING" ;
VAL_ 64 PACMOD_SYSTEM_STATUS 0 "DISABLED" 1 "ENABLED" ;
VAL_ 64 USER_PC_FAULT 0 "OKAY" 1 "FAULT" 2 "TIMEOUT" ;
VAL_ 64 PACMOD_SYSTEM_FAULT 0 "OKAY" 1 "FAULT" 2 "TIMEOUT" ;
VAL_ 64 MANUAL_STATE_OBTAINABLE 0 "NOT_OBTAINABLE" 1 "OBTAINABLE";
VAL_ 64 AUTOMS_READY_STATE_OBTAINABLE 0 "NOT_OBTAINABLE" 1 "OBTAINABLE";
VAL_ 64 AUTOMS_STATE_OBTAINABLE 0 "NOT_OBTAINABLE" 1 "OBTAINABLE";
VAL_ 64 MANUAL_READY_STATE_OBTAINABLE 0 "NOT_OBTAINABLE" 1 "OBTAINABLE";
VAL_ 64 CRITICAL_STOP1_STATE_OBTAINABLE 0 "NOT_OBTAINABLE" 1 "OBTAINABLE";
VAL_ 64 CRITICAL_STOP2_STATE_OBTAINABLE 0 "NOT_OBTAINABLE" 1 "OBTAINABLE";

// SAFETY_FUNC_RPT_2 VALUES
VAL_ 67 COMMANDED_STATE 0 "NONE" 1 "AUTOMS_READY" 2 "AUTOMS" 3 "MANUAL_READY" ;
VAL_ 67 STATE 0 "NONE" 1 "AUTOMS_READY" 2 "AUTOMS" 3 "MANUAL_READY" 4 "MANUAL" 5 "STARTUP" ;
VAL_ 67 MANUAL_STATE_OBTAINABLE 0 "NOT_OBTAINABLE" 1 "OBTAINABLE" ;
VAL_ 67 AUTOMS_READY_STATE_OBTAINABLE 0 "NOT_OBTAINABLE" 1 "OBTAINABLE" ;
VAL_ 67 AUTOMS_STATE_OBTAINABLE 0 "NOT_OBTAINABLE" 1 "OBTAINABLE" ;
VAL_ 67 MANUAL_READY_STATE_OBTAINABLE 0 "NOT_OBTAINABLE" 1 "OBTAINABLE" ;
VAL_ 67 SELF_TEST_ALLOWED 0 "NOT_ALLOWED" 1 "ALLOWED" ;

// SAFETY_RESPONSE_RPT VALUES
VAL_ 68 SAFETY_RESPONSE 0 "RESERVED" 1 "SAFETY_RESPONSE_1" 2 "SAFETY_RESPONSE_2" 3 "SAFETY_RESPONSE_3" ;

// SHIFT_AUX_RPT VALUES
VAL_ 808 BETWEEN_GEARS 0 "NOT_BETWEEN_GEARS" 1 "BETWEEN_GEARS" ;
VAL_ 808 STAY_IN_NEUTRAL_MODE 0 "OFF" 1 "ON" ;
VAL_ 808 BRAKE_INTERLOCK_ACTIVE 0 "NOT_ACTIVE" 1 "ACTIVE" ;
VAL_ 808 SPEED_INTERLOCK_ACTIVE 0 "NOT_ACTIVE" 1 "ACTIVE" ;
VAL_ 808 WRITE_TO_CONFIG 0 "SILENT" 1 "BEEP";
VAL_ 808 CALIBRATION_STATUS 0 "INACTIVE" 1 "ACTIVE" 2 "COMPLETE" 3 "ERROR" ;
VAL_ 808 BETWEEN_GEARS_AVAIL 0 "NOT_AVAILABLE" 1 "AVAILABLE" ;
VAL_ 808 STAY_IN_NEUTRAL_MODE_AVAIL 0 "NOT_AVAILABLE" 1 "AVAILABLE" ;
VAL_ 808 BRAKE_INTERLOCK_ACTIVE_AVAIL 0 "NOT_AVAILABLE" 1 "AVAILABLE" ;
VAL_ 808 SPEED_INTERLOCK_ACTIVE_AVAIL 0 "NOT_AVAILABLE" 1 "AVAILABLE" ;
VAL_ 808 WRITE_TO_CONFIG_IS_VALID 0 "NOT_AVAILABLE" 1 "AVAILABLE" ;
VAL_ 808 SHIFT_MODE_AVAIL 0 "NOT_AVAILABLE" 1 "AVAILABLE" ;
VAL_ 808 GEAR_NUMBER_AVAIL 0 "NOT_AVAILABLE" 1 "AVAILABLE" ;
VAL_ 808 GEAR_NUMBER 59 "RESERVED" 60 "RESERVED" 61 "RESERVED" 62 "ERROR" 63 "NOT_AVAIL" ;
VAL_ 808 SHIFT_MODE 0 "STANDARD" 1 "SPORT" ;
VAL_ 808 SHIFT_IN_PROGRESS 0 "SHIFT_NOT_IN_PROGRESS" 1 "SHIFT_IN_PROGRESS" 2 "ERROR" ;
VAL_ 808 DRIVELINE_ENGAGED 0 "DRIVELINE_DISENGAGED" 1 "DRIVELINE_ENGAGED" 2 "ERROR" ;
VAL_ 808 ACTUAL_GEAR_RATIO 65531 "RESERVED" 65532 "RESERVED" 65533 "RESERVED" 65534 "ERROR" 65535 "NOT_AVAIL";

// SHIFT_CMD VALUES
VAL_ 296 ENABLE 0 "DISABLE" 1 "ENABLE" ;
VAL_ 296 IGNORE_OVERRIDES 0 "FALSE" 1 "TRUE" ;
VAL_ 296 CLEAR_OVERRIDE 0 "FALSE" 1 "TRUE" ;
VAL_ 296 SHIFT_CMD 0 "PARK" 1 "REVERSE" 2 "NEUTRAL" 3 "FORWARD/HIGH" 4 "LOW" 7 "NONE" 124 "REV_THIRD" 125 "REV_SECOND" 126 "REV_FIRST" 127 "RESERVED" 128 "FIRST" 129 "SECOND" 130 "THIRD" 131 "FOURTH" 132 "FIFTH" 133 "SIXTH" 134 "SEVENTH" 135 "EIGHTH" 136 "NINTH" 137 "TENTH" 138 "ELEVENTH" 139 "TWELFTH" 140 "THIRTEENTH" 141 "FOURTEENTH" 142 "FIFTEENTH" 143 "SIXTEENTH" 144 "SEVENTEENTH" 145 "EIGHTEENTH" 146 "NINETEENTH" 147 "TWENTIETH" 148 "TWENTY-FIRST" 149 "TWENTY-SECOND" 150 "TWENTY-THIRD" 151 "TWENTY-FOURTH" 152 "TWENTY-FIFTH" ;

// SHIFT_RPT VALUES
VAL_ 552 ENABLED 0 "FALSE" 1 "TRUE" ;
VAL_ 552 OVERRIDE_ACTIVE 0 "FALSE" 1 "TRUE" ;
VAL_ 552 COMMAND_OUTPUT_FAULT 0 "NO_FAULT" 1 "FAULT" ;
VAL_ 552 INPUT_OUTPUT_FAULT 0 "NO_FAULT" 1 "FAULT" ;
VAL_ 552 OUTPUT_REPORTED_FAULT 0 "NO_FAULT" 1 "FAULT" ;
VAL_ 552 PACMOD_FAULT 0 "NO_FAULT" 1 "FAULT" ;
VAL_ 552 VEHICLE_FAULT 0 "NO_FAULT" 1 "FAULT" ;
VAL_ 552 COMMAND_TIMEOUT 0 "NO_TIMEOUT" 1 "TIMEOUT" ;
VAL_ 552 MANUAL_INPUT 0 "PARK" 1 "REVERSE" 2 "NEUTRAL" 3 "FORWARD/HIGH" 4 "LOW" 5 "BETWEEN_GEARS" 6 "ERROR" 7 "NONE" 124 "REV_THIRD" 125 "REV_SECOND" 126 "REV_FIRST" 127 "RESERVED" 128 "FIRST" 129 "SECOND" 130 "THIRD" 131 "FOURTH" 132 "FIFTH" 133 "SIXTH" 134 "SEVENTH" 135 "EIGHTH" 136 "NINTH" 137 "TENTH" 138 "ELEVENTH" 139 "TWELFTH" 140 "THIRTEENTH" 141 "FOURTEENTH" 142 "FIFTEENTH" 143 "SIXTEENTH" 144 "SEVENTEENTH" 145 "EIGHTEENTH" 146 "NINETEENTH" 147 "TWENTIETH" 148 "TWENTY-FIRST" 149 "TWENTY-SECOND" 150 "TWENTY-THIRD" 151 "TWENTY-FOURTH" 152 "TWENTY-FIFTH" 251 "RESERVED" 252 "RESERVED" 253 "RESERVED" 254 "ERROR" 255 "NOT_AVAIL" ;
VAL_ 552 COMMANDED_VALUE 0 "PARK" 1 "REVERSE" 2 "NEUTRAL" 3 "FORWARD/HIGH" 4 "LOW" 7 "NONE" 124 "REV_THIRD" 125 "REV_SECOND" 126 "REV_FIRST" 127 "RESERVED" 128 "FIRST" 129 "SECOND" 130 "THIRD" 131 "FOURTH" 132 "FIFTH" 133 "SIXTH" 134 "SEVENTH" 135 "EIGHTH" 136 "NINTH" 137 "TENTH" 138 "ELEVENTH" 139 "TWELFTH" 140 "THIRTEENTH" 141 "FOURTEENTH" 142 "FIFTEENTH" 143 "SIXTEENTH" 144 "SEVENTEENTH" 145 "EIGHTEENTH" 146 "NINETEENTH" 147 "TWENTIETH" 148 "TWENTY-FIRST" 149 "TWENTY-SECOND" 150 "TWENTY-THIRD" 151 "TWENTY-FOURTH" 152 "TWENTY-FIFTH" 251 "RESERVED" 252 "RESERVED" 253 "RESERVED" 254 "ERROR" 255 "NOT_AVAIL" ;
VAL_ 552 OUTPUT_VALUE 0 "PARK" 1 "REVERSE" 2 "NEUTRAL" 3 "FORWARD/HIGH" 4 "LOW" 5 "BETWEEN_GEARS" 6 "ERROR" 7 "NONE" 124 "REV_THIRD" 125 "REV_SECOND" 126 "REV_FIRST" 127 "RESERVED" 128 "FIRST" 129 "SECOND" 130 "THIRD" 131 "FOURTH" 132 "FIFTH" 133 "SIXTH" 134 "SEVENTH" 135 "EIGHTH" 136 "NINTH" 137 "TENTH" 138 "ELEVENTH" 139 "TWELFTH" 140 "THIRTEENTH" 141 "FOURTEENTH" 142 "FIFTEENTH" 143 "SIXTEENTH" 144 "SEVENTEENTH" 145 "EIGHTEENTH" 146 "NINETEENTH" 147 "TWENTIETH" 148 "TWENTY-FIRST" 149 "TWENTY-SECOND" 150 "TWENTY-THIRD" 151 "TWENTY-FOURTH" 152 "TWENTY-FIFTH" 251 "RESERVED" 252 "RESERVED" 253 "RESERVED" 254 "ERROR" 255 "NOT_AVAIL" ;
VAL_ 552 CONTROL_STATUS 0 "SAFE" 1 "AVAILABLE" ;
VAL_ 552 PERFORMANCE_STATUS 0 "NONE" 1 "CMD_TRACKING_FAILURE" 2 "APPOACHING_OPERATIONAL_LIMITS" 3 "LIMITING_ACTIVE" 4 "LIMITING_IMMINENT" ;

// SPRAYER_CMD VALUES
VAL_ 312 ENABLE 0 "DISABLE" 1 "ENABLE" ;
VAL_ 312 IGNORE_OVERRIDES 0 "FALSE" 1 "TRUE" ;
VAL_ 312 CLEAR_OVERRIDE 0 "FALSE" 1 "TRUE" ;
VAL_ 312 SPRAYER_CMD 0 "NOT_SPRAYING" 1 "SPRAYING";

// SPRAYER_RPT VALUES
VAL_ 568 ENABLED 0 "FALSE" 1 "TRUE" ;
VAL_ 568 OVERRIDE_ACTIVE 0 "FALSE" 1 "TRUE" ;
VAL_ 568 COMMAND_OUTPUT_FAULT 0 "FALSE" 1 "TRUE" ;
VAL_ 568 INPUT_OUTPUT_FAULT 0 "NO_FAULT" 1 "FAULT" ;
VAL_ 568 OUTPUT_REPORTED_FAULT 0 "NO_FAULT" 1 "FAULT" ;
VAL_ 568 PACMOD_FAULT 0 "NO_FAULT" 1 "FAULT" ;
VAL_ 568 VEHICLE_FAULT 0 "NO_FAULT" 1 "FAULT" ;
VAL_ 568 COMMAND_TIMEOUT 0 "NO_TIMEOUT" 1 "TIMEOUT" ;
VAL_ 568 MANUAL_INPUT 0 "NOT_SPRAYING" 1 "SPRAYING" 251 "RESERVED" 252 "RESERVED" 253 "RESERVED" 254 "ERROR" 255 "NOT_AVAIL" ;
VAL_ 568 COMMANDED_VALUE 0 "NOT_SPRAYING" 1 "SPRAYING" 251 "RESERVED" 252 "RESERVED" 253 "RESERVED" 254 "ERROR" 255 "NOT_AVAIL" ;
VAL_ 568 OUTPUT_VALUE 0 "NOT_SPRAYING" 1 "SPRAYING" 251 "RESERVED" 252 "RESERVED" 253 "RESERVED" 254 "ERROR" 255 "NOT_AVAIL" ;

// STEERING_AUX_RPT VALUES
VAL_ 812 STEERING_FLUID_PRESSURE 65531 "RESERVED" 65532 "RESERVED" 65533 "RESERVED" 65534 "ERROR" 65535 "NOT_AVAIL" ;
VAL_ 812 STEERING_TORQUE 65531 "RESERVED" 65532 "RESERVED" 65533 "RESERVED" 65534 "ERROR" 65535 "NOT_AVAIL";
VAL_ 812 ROTATION_RATE 65531 "RESERVED" 65532 "RESERVED" 65533 "RESERVED" 65534 "ERROR" 65535 "NOT_AVAIL";
VAL_ 812 OPERATOR_INTERACTION 0 "NO_INTERACTION" 1 "INTERACTION";
VAL_ 812 ROTATION_RATE_SIGN 0 "POSITIVE" 1 "NEGATIVE";
VAL_ 812 VEHICLE_ANGLE_CALIB_STATUS 0 "NOT_CALIBRATED" 1 "CALIBRATED";
VAL_ 812 STEERING_LIMITING_ACTIVE 0 "NOT_ACTIVE" 1 "ACTIVE";
VAL_ 812 CALIBRATION_STATUS 0 "INACTIVE" 1 "ACTIVE" 2 "COMPLETE" 3 "ERROR" ;
VAL_ 812 STEERING_CONTROLLER_TYPE 0 "LOW_SPEED" 1 "HIGH_SPEED" ;
VAL_ 812 STEERING_TORQUE_AVAIL 0 "NOT_AVAILABLE" 1 "AVAILABLE" ;
VAL_ 812 ROTATION_RATE_AVAIL 0 "NOT_AVAILABLE" 1 "AVAILABLE" ;
VAL_ 812 OPERATOR_INTERACTION_AVAIL 0 "NOT_AVAILABLE" 1 "AVAILABLE" ;
VAL_ 812 ROTATION_RATE_SIGN_AVAIL 0 "NOT_AVAILABLE" 1 "AVAILABLE" ;
VAL_ 812 VEHICLE_ANGLE_CALIB_STATUS_AVAIL 0 "NOT_AVAILABLE" 1 "AVAILABLE" ;
VAL_ 812 STEERING_LIMITING_ACTIVE_AVAIL 0 "NOT_AVAILABLE" 1 "AVAILABLE" ;
VAL_ 812 STEERING_CONTROLLER_TYPE_AVAIL 0 "NOT_AVAILABLE" 1 "AVAILABLE" ;

// STEERING_AUX_RPT_2 VALUES
VAL_ 814 STEERING_FLUID_PRESSURE 65531 "RESERVED" 65532 "RESERVED" 65533 "RESERVED" 65534 "ERROR" 65535 "NOT_AVAIL" ;
VAL_ 814 STEERING_TORQUE 65531 "RESERVED" 65532 "RESERVED" 65533 "RESERVED" 65534 "ERROR" 65535 "NOT_AVAIL";
VAL_ 812 ROTATION_RATE 65531 "RESERVED" 65532 "RESERVED" 65533 "RESERVED" 65534 "ERROR" 65535 "NOT_AVAIL";
VAL_ 814 OPERATOR_INTERACTION 0 "NO_INTERACTION" 1 "INTERACTION";
VAL_ 814 ROTATION_RATE_SIGN 0 "POSITIVE" 1 "NEGATIVE";
VAL_ 814 VEHICLE_ANGLE_CALIB_STATUS 0 "NOT_CALIBRATED" 1 "CALIBRATED";
VAL_ 814 STEERING_LIMITING_ACTIVE 0 "NOT_ACTIVE" 1 "ACTIVE";
VAL_ 814 CALIBRATION_STATUS 0 "INACTIVE" 1 "ACTIVE" 2 "COMPLETE" 3 "ERROR" ;
VAL_ 814 STEERING_CONTROLLER_TYPE 0 "LOW_SPEED" 1 "HIGH_SPEED" ;
VAL_ 814 STEERING_TORQUE_AVAIL 0 "NOT_AVAILABLE" 1 "AVAILABLE" ;
VAL_ 814 ROTATION_RATE_AVAIL 0 "NOT_AVAILABLE" 1 "AVAILABLE" ;
VAL_ 814 OPERATOR_INTERACTION_AVAIL 0 "NOT_AVAILABLE" 1 "AVAILABLE" ;
VAL_ 814 ROTATION_RATE_SIGN_AVAIL 0 "NOT_AVAILABLE" 1 "AVAILABLE" ;
VAL_ 814 VEHICLE_ANGLE_CALIB_STATUS_AVAIL 0 "NOT_AVAILABLE" 1 "AVAILABLE" ;
VAL_ 814 STEERING_LIMITING_ACTIVE_AVAIL 0 "NOT_AVAILABLE" 1 "AVAILABLE" ;
VAL_ 814 STEERING_CONTROLLER_TYPE_AVAIL 0 "NOT_AVAILABLE" 1 "AVAILABLE" ;

// STEERING_CMD VALUES
VAL_ 300 ENABLE 0 "DISABLE" 1 "ENABLE" ;
VAL_ 300 IGNORE_OVERRIDES 0 "FALSE" 1 "TRUE" ;
VAL_ 300 CLEAR_OVERRIDE 0 "FALSE" 1 "TRUE" ;

// STEERING_RPT VALUES
VAL_ 556 ENABLED 0 "FALSE" 1 "TRUE" ;
VAL_ 556 OVERRIDE_ACTIVE 0 "FALSE" 1 "TRUE" ;
VAL_ 556 COMMAND_OUTPUT_FAULT 0 "NO_FAULT" 1 "FAULT" ;
VAL_ 556 INPUT_OUTPUT_FAULT 0 "NO_FAULT" 1 "FAULT" ;
VAL_ 556 OUTPUT_REPORTED_FAULT 0 "NO_FAULT" 1 "FAULT" ;
VAL_ 556 PACMOD_FAULT 0 "NO_FAULT" 1 "FAULT" ;
VAL_ 556 VEHICLE_FAULT 0 "NO_FAULT" 1 "FAULT" ;
VAL_ 556 COMMAND_TIMEOUT 0 "NO_TIMEOUT" 1 "TIMEOUT" ;
VAL_ 556 MANUAL_INPUT 32763 "RESERVED" 32764 "RESERVED" 32765 "RESERVED" 32766 "ERROR" 32767 "NOT_AVAIL" ;
VAL_ 556 COMMANDED_VALUE 32763 "RESERVED" 32764 "RESERVED" 32765 "RESERVED"32766 "ERROR" 32767 "NOT_AVAIL" ;
VAL_ 556 OUTPUT_VALUE 32763 "RESERVED" 32764 "RESERVED" 32765 "RESERVED"32766 "ERROR" 32767 "NOT_AVAIL" ;
VAL_ 556 CONTROL_STATUS 0 "SAFE" 1 "AVAILABLE" ;
VAL_ 556 PERFORMANCE_STATUS 0 "NONE" 1 "CMD_TRACKING_FAILURE" 2 "APPOACHING_OPERATIONAL_LIMITS" 3 "LIMITING_ACTIVE" 4 "LIMITING_IMMINENT" ;
VAL_ 556 SELF_TEST_STATUS 0 "NOT_RUNNING" 1 "IN_PROGRESS" 2 "ERROR" 3 "NOT_AVAIL" ;

// STEERING_RPT_2 VALUES
VAL_ 558 ENABLED 0 "FALSE" 1 "TRUE" ;
VAL_ 558 OVERRIDE_ACTIVE 0 "FALSE" 1 "TRUE" ;
VAL_ 558 COMMAND_OUTPUT_FAULT 0 "NO_FAULT" 1 "FAULT" ;
VAL_ 558 INPUT_OUTPUT_FAULT 0 "NO_FAULT" 1 "FAULT" ;
VAL_ 558 OUTPUT_REPORTED_FAULT 0 "NO_FAULT" 1 "FAULT" ;
VAL_ 558 PACMOD_FAULT 0 "NO_FAULT" 1 "FAULT" ;
VAL_ 558 VEHICLE_FAULT 0 "NO_FAULT" 1 "FAULT" ;
VAL_ 558 COMMAND_TIMEOUT 0 "NO_TIMEOUT" 1 "TIMEOUT" ;
VAL_ 558 MANUAL_INPUT 32763 "RESERVED" 32764 "RESERVED" 32765 "RESERVED" 32766 "ERROR" 32767 "NOT_AVAIL" ;
VAL_ 558 COMMANDED_VALUE 32763 "RESERVED" 32764 "RESERVED" 32765 "RESERVED" 32766 "ERROR" 32767 "NOT_AVAIL" ;
VAL_ 558 OUTPUT_VALUE 32763 "RESERVED" 32764 "RESERVED" 32765 "RESERVED" 32766 "ERROR" 32767 "NOT_AVAIL" ;
VAL_ 558 CONTROL_STATUS 0 "SAFE" 1 "AVAILABLE" ;
VAL_ 558 PERFORMANCE_STATUS 0 "NONE" 1 "CMD_TRACKING_FAILURE" 2 "APPOACHING_OPERATIONAL_LIMITS" 3 "LIMITING_ACTIVE" 4 "LIMITING_IMMINENT" ;
VAL_ 558 SELF_TEST_STATUS 0 "NOT_RUNNING" 1 "IN_PROGRESS" 2 "ERROR" 3 "NOT_AVAIL" ;

// SUPERVISORY_CTRL VALUES
VAL_ 129 ENABLE 0 "DISABLE_ALL_SYSTEMS" 1 "ALLOW_ENABLE" ;

// TIPPER_BODY_AUX_RPT_00
VAL_ 856 DOOR_ANGLE 32763 "RESERVED"  32764 "RESERVED"  32765 "RESERVED"  32766 "ERROR" 32767 "NOT_AVAIL" ;
VAL_ 856 BODY_ANGLE 32763 "RESERVED"  32764 "RESERVED"  32765 "RESERVED"  32766 "ERROR" 32767 "NOT_AVAIL" ;
VAL_ 856 DOOR_FULLY_OPEN 0 "FALSE" 1 "TRUE" 2 "ERROR" 3 "NOT_AVAIL" ;
VAL_ 856 DOOR_FULLY_CLOSED 0 "FALSE" 1 "TRUE" 2 "ERROR" 3 "NOT_AVAIL" ;
VAL_ 856 BODY_FULLY_LOWERED 0 "FALSE" 1 "TRUE" 2 "ERROR" 3 "NOT_AVAIL" ;
VAL_ 856 BODY_FULLY_RAISED 0 "FALSE" 1 "TRUE" 2 "ERROR" 3 "NOT_AVAIL" ;

// TIPPER_BODY_AUX_RPT_01
VAL_ 876 DOOR_ANGLE 32763 "RESERVED"  32764 "RESERVED"  32765 "RESERVED"  32766 "ERROR" 32767 "NOT_AVAIL" ;
VAL_ 876 BODY_ANGLE 32763 "RESERVED"  32764 "RESERVED"  32765 "RESERVED"  32766 "ERROR" 32767 "NOT_AVAIL" ;
VAL_ 876 DOOR_FULLY_OPEN 0 "FALSE" 1 "TRUE" 2 "ERROR" 3 "NOT_AVAIL" ;
VAL_ 876 DOOR_FULLY_CLOSED 0 "FALSE" 1 "TRUE" 2 "ERROR" 3 "NOT_AVAIL" ;
VAL_ 876 BODY_FULLY_LOWERED 0 "FALSE" 1 "TRUE" 2 "ERROR" 3 "NOT_AVAIL" ;
VAL_ 856 BODY_FULLY_RAISED 0 "FALSE" 1 "TRUE" 2 "ERROR" 3 "NOT_AVAIL" ;

// TIPPER_BODY_AUX_RPT_02
VAL_ 880 DOOR_ANGLE 32763 "RESERVED"  32764 "RESERVED"  32765 "RESERVED"  32766 "ERROR" 32767 "NOT_AVAIL" ;
VAL_ 880 BODY_ANGLE 32763 "RESERVED"  32764 "RESERVED"  32765 "RESERVED"  32766 "ERROR" 32767 "NOT_AVAIL" ;
VAL_ 880 DOOR_FULLY_OPEN 0 "FALSE" 1 "TRUE" 2 "ERROR" 3 "NOT_AVAIL" ;
VAL_ 880 DOOR_FULLY_CLOSED 0 "FALSE" 1 "TRUE" 2 "ERROR" 3 "NOT_AVAIL" ;
VAL_ 880 BODY_FULLY_LOWERED 0 "FALSE" 1 "TRUE" 2 "ERROR" 3 "NOT_AVAIL" ;
VAL_ 880 BODY_FULLY_RAISED 0 "FALSE" 1 "TRUE" 2 "ERROR" 3 "NOT_AVAIL" ;

// TIPPER_BODY_CMD_00 VALUES
VAL_ 344 ENABLE 0 "DISABLE" 1 "ENABLE" ;
VAL_ 344 IGNORE_OVERRIDES 0 "FALSE" 1 "TRUE" ;
VAL_ 344 CLEAR_OVERRIDE 0 "FALSE" 1 "TRUE" ;
VAL_ 344 TIPPER_CONTROL_CMD 0 "NO_ACTION" 1 "RAISE" 2 "LOWER" ;

// TIPPER_BODY_CMD_01 VALUES
VAL_ 364 ENABLE 0 "DISABLE" 1 "ENABLE" ;
VAL_ 364 IGNORE_OVERRIDES 0 "FALSE" 1 "TRUE" ;
VAL_ 364 CLEAR_OVERRIDE 0 "FALSE" 1 "TRUE" ;
VAL_ 364 TIPPER_CONTROL_CMD 0 "NO_ACTION" 1 "RAISE" 2 "LOWER" ;

// TIPPER_BODY_CMD_02 VALUES
VAL_ 368 ENABLE 0 "DISABLE" 1 "ENABLE" ;
VAL_ 368 IGNORE_OVERRIDES 0 "FALSE" 1 "TRUE" ;
VAL_ 368 CLEAR_OVERRIDE 0 "FALSE" 1 "TRUE" ;
VAL_ 368 TIPPER_CONTROL_CMD 0 "NO_ACTION" 1 "RAISE" 2 "LOWER" ;

// TIPPER_BODY_RPT_00 VALUES
VAL_ 600 ENABLED 0 "FALSE" 1 "TRUE" ;
VAL_ 600 OVERRIDE_ACTIVE 0 "FALSE" 1 "TRUE" ;
VAL_ 600 COMMAND_OUTPUT_FAULT 0 "NO_FAULT" 1 "FAULT" ;
VAL_ 600 INPUT_OUTPUT_FAULT 0 "NO_FAULT" 1 "FAULT" ;
VAL_ 600 OUTPUT_REPORTED_FAULT 0 "NO_FAULT" 1 "FAULT" ;
VAL_ 600 PACMOD_FAULT 0 "NO_FAULT" 1 "FAULT" ;
VAL_ 600 VEHICLE_FAULT 0 "NO_FAULT" 1 "FAULT" ;
VAL_ 600 COMMAND_TIMEOUT 0 "NO_TIMEOUT" 1 "TIMEOUT" ;
VAL_ 600 MANUAL_INPUT 0 "NO_ACTION" 1 "RAISE" 2 "LOWER" 251 "RESERVED" 252 "RESERVED" 253 "RESERVED" 254 "ERROR" 255 "NOT_AVAIL" ;
VAL_ 600 COMMANDED_VALUE 0 "NO_ACTION" 1 "RAISE" 2 "LOWER" 251 "RESERVED" 252 "RESERVED" 253 "RESERVED" 254 "ERROR" 255 "NOT_AVAIL" ;
VAL_ 600 OUTPUT_VALUE 0 "NO_ACTION" 1 "RAISE" 2 "LOWER" 251 "RESERVED" 252 "RESERVED" 253 "RESERVED" 254 "ERROR" 255 "NOT_AVAIL" ;
VAL_ 600 CONTROL_STATUS 0 "SAFE" 1 "AVAILABLE" ;
VAL_ 600 PERFORMANCE_STATUS 0 "NONE" 1 "CMD_TRACKING_FAILURE" 2 "APPOACHING_OPERATIONAL_LIMITS" 3 "LIMITING_ACTIVE" 4 "LIMITING_IMMINENT" ;

// TIPPER_BODY_RPT_01 VALUES
VAL_ 620 ENABLED 0 "FALSE" 1 "TRUE" ;
VAL_ 620 OVERRIDE_ACTIVE 0 "FALSE" 1 "TRUE" ;
VAL_ 620 COMMAND_OUTPUT_FAULT 0 "NO_FAULT" 1 "FAULT" ;
VAL_ 620 INPUT_OUTPUT_FAULT 0 "NO_FAULT" 1 "FAULT" ;
VAL_ 620 OUTPUT_REPORTED_FAULT 0 "NO_FAULT" 1 "FAULT" ;
VAL_ 620 PACMOD_FAULT 0 "NO_FAULT" 1 "FAULT" ;
VAL_ 620 VEHICLE_FAULT 0 "NO_FAULT" 1 "FAULT" ;
VAL_ 620 COMMAND_TIMEOUT 0 "NO_TIMEOUT" 1 "TIMEOUT" ;
VAL_ 620 MANUAL_INPUT 0 "NO_ACTION" 1 "RAISE" 2 "LOWER" 251 "RESERVED" 252 "RESERVED" 253 "RESERVED" 254 "ERROR" 255 "NOT_AVAIL" ;
VAL_ 620 COMMANDED_VALUE 0 "NO_ACTION" 1 "RAISE" 2 "LOWER" 251 "RESERVED" 252 "RESERVED" 253 "RESERVED" 254 "ERROR" 255 "NOT_AVAIL" ;
VAL_ 620 OUTPUT_VALUE 0 "NO_ACTION" 1 "RAISE" 2 "LOWER" 251 "RESERVED" 252 "RESERVED" 253 "RESERVED" 254 "ERROR" 255 "NOT_AVAIL" ;
VAL_ 620 CONTROL_STATUS 0 "SAFE" 1 "AVAILABLE" ;
VAL_ 620 PERFORMANCE_STATUS 0 "NONE" 1 "CMD_TRACKING_FAILURE" 2 "APPOACHING_OPERATIONAL_LIMITS" 3 "LIMITING_ACTIVE" 4 "LIMITING_IMMINENT" ;

// TIPPER_BODY_RPT_02 VALUES
VAL_ 624 ENABLED 0 "FALSE" 1 "TRUE" ;
VAL_ 624 OVERRIDE_ACTIVE 0 "FALSE" 1 "TRUE" ;
VAL_ 624 COMMAND_OUTPUT_FAULT 0 "NO_FAULT" 1 "FAULT" ;
VAL_ 624 INPUT_OUTPUT_FAULT 0 "NO_FAULT" 1 "FAULT" ;
VAL_ 624 OUTPUT_REPORTED_FAULT 0 "NO_FAULT" 1 "FAULT" ;
VAL_ 624 PACMOD_FAULT 0 "NO_FAULT" 1 "FAULT" ;
VAL_ 624 VEHICLE_FAULT 0 "NO_FAULT" 1 "FAULT" ;
VAL_ 624 COMMAND_TIMEOUT 0 "NO_TIMEOUT" 1 "TIMEOUT" ;
VAL_ 624 MANUAL_INPUT 0 "NO_ACTION" 1 "RAISE" 2 "LOWER" 251 "RESERVED" 252 "RESERVED" 253 "RESERVED" 254 "ERROR" 255 "NOT_AVAIL" ;
VAL_ 624 COMMANDED_VALUE 0 "NO_ACTION" 1 "RAISE" 2 "LOWER" 251 "RESERVED" 252 "RESERVED" 253 "RESERVED" 254 "ERROR" 255 "NOT_AVAIL" ;
VAL_ 624 OUTPUT_VALUE 0 "NO_ACTION" 1 "RAISE" 2 "LOWER" 251 "RESERVED" 252 "RESERVED" 253 "RESERVED" 254 "ERROR" 255 "NOT_AVAIL" ;
VAL_ 624 CONTROL_STATUS 0 "SAFE" 1 "AVAILABLE" ;
VAL_ 624 PERFORMANCE_STATUS 0 "NONE" 1 "CMD_TRACKING_FAILURE" 2 "APPOACHING_OPERATIONAL_LIMITS" 3 "LIMITING_ACTIVE" 4 "LIMITING_IMMINENT" ;

// TIRE_PRESSURE_EXTENDED_RPT VALUES
VAL_ 1072 TIRE_PRESSURE_1 251 "RESERVED" 252 "RESERVED" 253 "RESERVED" 254 "ERROR" 255 "NOT_ACTIVE" ;
VAL_ 1072 TIRE_PRESSURE_2 251 "RESERVED" 252 "RESERVED" 253 "RESERVED" 254 "ERROR" 255 "NOT_ACTIVE" ;
VAL_ 1072 TIRE_PRESSURE_3 251 "RESERVED" 252 "RESERVED" 253 "RESERVED" 254 "ERROR" 255 "NOT_ACTIVE" ;

// TIRE_PRESSURE_EXTENDED_RPT_2 VALUES
VAL_ 1073 TIRE_PRESSURE_1 251 "RESERVED" 252 "RESERVED" 253 "RESERVED" 254 "ERROR" 255 "NOT_ACTIVE" ;
VAL_ 1073 TIRE_PRESSURE_2 251 "RESERVED" 252 "RESERVED" 253 "RESERVED" 254 "ERROR" 255 "NOT_ACTIVE" ;
VAL_ 1073 TIRE_PRESSURE_3 251 "RESERVED" 252 "RESERVED" 253 "RESERVED" 254 "ERROR" 255 "NOT_ACTIVE" ;

// TIRE_TEMPERATURE_EXTENDED_RPT VALUES
VAL_ 1074 TIRE_TEMPERATURE_1 251 "RESERVED" 252 "RESERVED" 253 "RESERVED" 254 "ERROR" 255 "NOT_ACTIVE" ;
VAL_ 1074 TIRE_TEMPERATURE_2 251 "RESERVED" 252 "RESERVED" 253 "RESERVED" 254 "ERROR" 255 "NOT_ACTIVE" ;
VAL_ 1074 TIRE_TEMPERATURE_3 251 "RESERVED" 252 "RESERVED" 253 "RESERVED" 254 "ERROR" 255 "NOT_ACTIVE" ;

// TIRE_TEMPERATURE_EXTENDED_RPT_2 VALUES
VAL_ 1075 TIRE_TEMPERATURE_1 251 "RESERVED" 252 "RESERVED" 253 "RESERVED" 254 "ERROR" 255 "NOT_ACTIVE" ;
VAL_ 1075 TIRE_TEMPERATURE_2 251 "RESERVED" 252 "RESERVED" 253 "RESERVED" 254 "ERROR" 255 "NOT_ACTIVE" ;
VAL_ 1075 TIRE_TEMPERATURE_3 251 "RESERVED" 252 "RESERVED" 253 "RESERVED" 254 "ERROR" 255 "NOT_ACTIVE" ;

// TRAILER_AIR_SUPPLY_CMD VALUES
VAL_ 356 ENABLE 0 "DISABLE" 1 "ENABLE" ;
VAL_ 356 IGNORE_OVERRIDES 0 "FALSE" 1 "TRUE" ;
VAL_ 356 CLEAR_OVERRIDE 0 "FALSE" 1 "TRUE" ;
VAL_ 356 TRAILER_AIR_SUPPLY_CMD 0 "OFF" 1 "ON" ;

// TRAILER_AIR_SUPPLY_RPT VALUES
VAL_ 612 ENABLED 0 "FALSE" 1 "TRUE" ;
VAL_ 612 OVERRIDE_ACTIVE 0 "FALSE" 1 "TRUE" ;
VAL_ 612 COMMAND_OUTPUT_FAULT 0 "NO_FAULT" 1 "FAULT" ;
VAL_ 612 INPUT_OUTPUT_FAULT 0 "NO_FAULT" 1 "FAULT" ;
VAL_ 612 OUTPUT_REPORTED_FAULT 0 "NO_FAULT" 1 "FAULT" ;
VAL_ 612 PACMOD_FAULT 0 "NO_FAULT" 1 "FAULT" ;
VAL_ 612 VEHICLE_FAULT 0 "NO_FAULT" 1 "FAULT" ;
VAL_ 612 COMMAND_TIMEOUT 0 "NO_TIMEOUT" 1 "TIMEOUT" ;
VAL_ 612 MANUAL_INPUT 0 "OFF" 1 "ON" 251 "RESERVED" 252 "RESERVED" 253 "RESERVED" 254 "ERROR" 255 "NOT_AVAIL" ;
VAL_ 612 COMMANDED_VALUE 0 "OFF" 1 "ON" 251 "RESERVED" 252 "RESERVED" 253 "RESERVED" 254 "ERROR" 255 "NOT_AVAIL" ;
VAL_ 612 OUTPUT_VALUE 0 "OFF" 1 "ON" 251 "RESERVED" 252 "RESERVED" 253 "RESERVED" 254 "ERROR" 255 "NOT_AVAIL" ;
VAL_ 612 CONTROL_STATUS 0 "SAFE" 1 "AVAILABLE" ;
VAL_ 612 PERFORMANCE_STATUS 0 "NONE" 1 "CMD_TRACKING_FAILURE" 2 "APPOACHING_OPERATIONAL_LIMITS" 3 "LIMITING_ACTIVE" 4 "LIMITING_IMMINENT" ;
VAL_ 612 SELF_TEST_STATUS 0 "NOT_RUNNING" 1 "IN_PROGRESS" 2 "ERROR" 3 "NOT_AVAIL" ;

// TRAILER_AIR_SUPPLY_RPT_2 VALUES
VAL_ 614 ENABLED 0 "FALSE" 1 "TRUE" ;
VAL_ 614 OVERRIDE_ACTIVE 0 "FALSE" 1 "TRUE" ;
VAL_ 614 COMMAND_OUTPUT_FAULT 0 "NO_FAULT" 1 "FAULT" ;
VAL_ 614 INPUT_OUTPUT_FAULT 0 "NO_FAULT" 1 "FAULT" ;
VAL_ 614 OUTPUT_REPORTED_FAULT 0 "NO_FAULT" 1 "FAULT" ;
VAL_ 614 PACMOD_FAULT 0 "NO_FAULT" 1 "FAULT" ;
VAL_ 614 VEHICLE_FAULT 0 "NO_FAULT" 1 "FAULT" ;
VAL_ 614 COMMAND_TIMEOUT 0 "NO_TIMEOUT" 1 "TIMEOUT" ;
VAL_ 614 MANUAL_INPUT 0 "OFF" 1 "ON" 251 "RESERVED" 252 "RESERVED" 253 "RESERVED" 254 "ERROR" 255 "NOT_AVAIL" ;
VAL_ 614 COMMANDED_VALUE 0 "OFF" 1 "ON" 251 "RESERVED" 252 "RESERVED" 253 "RESERVED" 254 "ERROR" 255 "NOT_AVAIL" ;
VAL_ 614 OUTPUT_VALUE 0 "OFF" 1 "ON" 251 "RESERVED" 252 "RESERVED" 253 "RESERVED" 254 "ERROR" 255 "NOT_AVAIL" ;
VAL_ 614 CONTROL_STATUS 0 "SAFE" 1 "AVAILABLE" ;
VAL_ 614 PERFORMANCE_STATUS 0 "NONE" 1 "CMD_TRACKING_FAILURE" 2 "APPOACHING_OPERATIONAL_LIMITS" 3 "LIMITING_ACTIVE" 4 "LIMITING_IMMINENT" ;
VAL_ 614 SELF_TEST_STATUS 0 "NOT_RUNNING" 1 "IN_PROGRESS" 2 "ERROR" 3 "NOT_AVAIL" ;

// TRAILER_BRAKE_CMD VALUES
VAL_ 352 ENABLE 0 "DISABLE" 1 "ENABLE" ;
VAL_ 352 IGNORE_OVERRIDES 0 "FALSE" 1 "TRUE" ;
VAL_ 352 CLEAR_OVERRIDE 0 "FALSE" 1 "TRUE" ;

// TRAILER_BRAKE_PRESSURE_RPT_00 VALUES
VAL_ 1064 BRAKE_PRESSURE_AXLE_1_LEFT 251 "RESERVED"  252 "RESERVED"  253 "RESERVED"  254 "ERROR" 255 "NOT_AVAIL" ;
VAL_ 1064 BRAKE_PRESSURE_AXLE_1_RIGHT 251 "RESERVED"  252 "RESERVED"  253 "RESERVED"  254 "ERROR" 255 "NOT_AVAIL" ;
VAL_ 1064 BRAKE_PRESSURE_AXLE_2_LEFT 251 "RESERVED"  252 "RESERVED"  253 "RESERVED"  254 "ERROR" 255 "NOT_AVAIL" ;
VAL_ 1064 BRAKE_PRESSURE_AXLE_2_RIGHT 251 "RESERVED"  252 "RESERVED"  253 "RESERVED"  254 "ERROR" 255 "NOT_AVAIL" ;
VAL_ 1064 BRAKE_PRESSURE_AXLE_3_LEFT 251 "RESERVED"  252 "RESERVED"  253 "RESERVED"  254 "ERROR" 255 "NOT_AVAIL" ;
VAL_ 1064 BRAKE_PRESSURE_AXLE_3_RIGHT 251 "RESERVED"  252 "RESERVED"  253 "RESERVED"  254 "ERROR" 255 "NOT_AVAIL" ;
VAL_ 1064 PNEUMATIC_SUPPLY_PRESSURE 251 "RESERVED"  252 "RESERVED"  253 "RESERVED"  254 "ERROR" 255 "NOT_AVAIL" ;

// TRAILER_BRAKE_PRESSURE_RPT_01 VALUES
VAL_ 1065 BRAKE_PRESSURE_AXLE_1_LEFT 251 "RESERVED"  252 "RESERVED"  253 "RESERVED"  254 "ERROR" 255 "NOT_AVAIL" ;
VAL_ 1065 BRAKE_PRESSURE_AXLE_1_RIGHT 251 "RESERVED"  252 "RESERVED"  253 "RESERVED"  254 "ERROR" 255 "NOT_AVAIL" ;
VAL_ 1065 BRAKE_PRESSURE_AXLE_2_LEFT 251 "RESERVED"  252 "RESERVED"  253 "RESERVED"  254 "ERROR" 255 "NOT_AVAIL" ;
VAL_ 1065 BRAKE_PRESSURE_AXLE_2_RIGHT 251 "RESERVED"  252 "RESERVED"  253 "RESERVED"  254 "ERROR" 255 "NOT_AVAIL" ;
VAL_ 1065 BRAKE_PRESSURE_AXLE_3_LEFT 251 "RESERVED"  252 "RESERVED"  253 "RESERVED"  254 "ERROR" 255 "NOT_AVAIL" ;
VAL_ 1065 BRAKE_PRESSURE_AXLE_3_RIGHT 251 "RESERVED"  252 "RESERVED"  253 "RESERVED"  254 "ERROR" 255 "NOT_AVAIL" ;
VAL_ 1065 PNEUMATIC_SUPPLY_PRESSURE 251 "RESERVED"  252 "RESERVED"  253 "RESERVED"  254 "ERROR" 255 "NOT_AVAIL" ;

// TRAILER_BRAKE_PRESSURE_RPT_02 VALUES
VAL_ 1066 BRAKE_PRESSURE_AXLE_1_LEFT 251 "RESERVED"  252 "RESERVED"  253 "RESERVED"  254 "ERROR" 255 "NOT_AVAIL" ;
VAL_ 1066 BRAKE_PRESSURE_AXLE_1_RIGHT 251 "RESERVED"  252 "RESERVED"  253 "RESERVED"  254 "ERROR" 255 "NOT_AVAIL" ;
VAL_ 1066 BRAKE_PRESSURE_AXLE_2_LEFT 251 "RESERVED"  252 "RESERVED"  253 "RESERVED"  254 "ERROR" 255 "NOT_AVAIL" ;
VAL_ 1066 BRAKE_PRESSURE_AXLE_2_RIGHT 251 "RESERVED"  252 "RESERVED"  253 "RESERVED"  254 "ERROR" 255 "NOT_AVAIL" ;
VAL_ 1066 BRAKE_PRESSURE_AXLE_3_LEFT 251 "RESERVED"  252 "RESERVED"  253 "RESERVED"  254 "ERROR" 255 "NOT_AVAIL" ;
VAL_ 1066 BRAKE_PRESSURE_AXLE_3_RIGHT 251 "RESERVED"  252 "RESERVED"  253 "RESERVED"  254 "ERROR" 255 "NOT_AVAIL" ;
VAL_ 1066 PNEUMATIC_SUPPLY_PRESSURE 251 "RESERVED"  252 "RESERVED"  253 "RESERVED"  254 "ERROR" 255 "NOT_AVAIL" ;

// TRAILER_BRAKE_PRESSURE_RPT_03 VALUES
VAL_ 1067 BRAKE_PRESSURE_AXLE_1_LEFT 251 "RESERVED"  252 "RESERVED"  253 "RESERVED"  254 "ERROR" 255 "NOT_AVAIL" ;
VAL_ 1067 BRAKE_PRESSURE_AXLE_1_RIGHT 251 "RESERVED"  252 "RESERVED"  253 "RESERVED"  254 "ERROR" 255 "NOT_AVAIL" ;
VAL_ 1067 BRAKE_PRESSURE_AXLE_2_LEFT 251 "RESERVED"  252 "RESERVED"  253 "RESERVED"  254 "ERROR" 255 "NOT_AVAIL" ;
VAL_ 1067 BRAKE_PRESSURE_AXLE_2_RIGHT 251 "RESERVED"  252 "RESERVED"  253 "RESERVED"  254 "ERROR" 255 "NOT_AVAIL" ;
VAL_ 1067 BRAKE_PRESSURE_AXLE_3_LEFT 251 "RESERVED"  252 "RESERVED"  253 "RESERVED"  254 "ERROR" 255 "NOT_AVAIL" ;
VAL_ 1067 BRAKE_PRESSURE_AXLE_3_RIGHT 251 "RESERVED"  252 "RESERVED"  253 "RESERVED"  254 "ERROR" 255 "NOT_AVAIL" ;
VAL_ 1067 PNEUMATIC_SUPPLY_PRESSURE 251 "RESERVED"  252 "RESERVED"  253 "RESERVED"  254 "ERROR" 255 "NOT_AVAIL" ;

// TRAILER_BRAKE_PRESSURE_RPT_04 VALUES
VAL_ 1068 BRAKE_PRESSURE_AXLE_1_LEFT 251 "RESERVED"  252 "RESERVED"  253 "RESERVED"  254 "ERROR" 255 "NOT_AVAIL" ;
VAL_ 1068 BRAKE_PRESSURE_AXLE_1_RIGHT 251 "RESERVED"  252 "RESERVED"  253 "RESERVED"  254 "ERROR" 255 "NOT_AVAIL" ;
VAL_ 1068 BRAKE_PRESSURE_AXLE_2_LEFT 251 "RESERVED"  252 "RESERVED"  253 "RESERVED"  254 "ERROR" 255 "NOT_AVAIL" ;
VAL_ 1068 BRAKE_PRESSURE_AXLE_2_RIGHT 251 "RESERVED"  252 "RESERVED"  253 "RESERVED"  254 "ERROR" 255 "NOT_AVAIL" ;
VAL_ 1068 BRAKE_PRESSURE_AXLE_3_LEFT 251 "RESERVED"  252 "RESERVED"  253 "RESERVED"  254 "ERROR" 255 "NOT_AVAIL" ;
VAL_ 1068 BRAKE_PRESSURE_AXLE_3_RIGHT 251 "RESERVED"  252 "RESERVED"  253 "RESERVED"  254 "ERROR" 255 "NOT_AVAIL" ;
VAL_ 1068 PNEUMATIC_SUPPLY_PRESSURE 251 "RESERVED"  252 "RESERVED"  253 "RESERVED"  254 "ERROR" 255 "NOT_AVAIL" ;

// TRAILER_BRAKE_RPT VALUES
VAL_ 608 ENABLED 0 "FALSE" 1 "TRUE" ;
VAL_ 608 OVERRIDE_ACTIVE 0 "FALSE" 1 "TRUE" ;
VAL_ 608 COMMAND_OUTPUT_FAULT 0 "NO_FAULT" 1 "FAULT" ;
VAL_ 608 INPUT_OUTPUT_FAULT 0 "NO_FAULT" 1 "FAULT" ;
VAL_ 608 OUTPUT_REPORTED_FAULT 0 "NO_FAULT" 1 "FAULT" ;
VAL_ 608 PACMOD_FAULT 0 "NO_FAULT" 1 "FAULT" ;
VAL_ 608 VEHICLE_FAULT 0 "NO_FAULT" 1 "FAULT" ;
VAL_ 608 COMMAND_TIMEOUT 0 "NO_TIMEOUT" 1 "TIMEOUT" ;
VAL_ 608 MANUAL_INPUT 65531 "RESERVED" 65532 "RESERVED" 65533 "RESERVED" 65534 "ERROR" 65535 "NOT_AVAIL" ;
VAL_ 608 COMMANDED_VALUE 65531 "RESERVED" 65532 "RESERVED" 65533 "RESERVED" 65534 "ERROR" 65535 "NOT_AVAIL" ;
VAL_ 608 OUTPUT_VALUE 65531 "RESERVED" 65532 "RESERVED" 65533 "RESERVED" 65534 "ERROR" 65535 "NOT_AVAIL" ;

// TRAILER_FAULT_RPT_00 VALUES
VAL_ 1084 SERVICE_BRAKE_STATUS 0 "PASSIVE" 1 "ACTIVE" 2 "ERROR" 3 "NOT_AVAIL" ;
VAL_ 1084 ABS_STATUS 0 "PASSIVE" 1 "ACTIVE" 2 "ERROR" 3 "NOT_AVAIL" ;
VAL_ 1084 ELECTRICAL_SUPPLY_STATUS 0 "INSUFFICIENT" 1 "SUFFICIENT" 2 "ERROR" 3 "NOT_AVAIL" ;
VAL_ 1084 PNEUMATIC_SUPPLY_STATUS 0 "INSUFFICIENT" 1 "SUFFICIENT" 2 "ERROR" 3 "NOT_AVAIL" ;
VAL_ 1084 AMBER_WARNING_LAMP_REQUEST 0 "LAMP_OFF"  1 "LAMP_ON"  2 "ERROR" 3 "NOT_AVAIL" ;
VAL_ 1084 RED_WARNING_LAMP_REQUEST 0 "LAMP_OFF"  1 "LAMP_ON"  2 "ERROR" 3 "NOT_AVAIL" ;

// TRAILER_FAULT_RPT_01 VALUES
VAL_ 1085 SERVICE_BRAKE_STATUS 0 "PASSIVE" 1 "ACTIVE" 2 "ERROR" 3 "NOT_AVAIL" ;
VAL_ 1085 ABS_STATUS 0 "PASSIVE" 1 "ACTIVE" 2 "ERROR" 3 "NOT_AVAIL" ;
VAL_ 1085 ELECTRICAL_SUPPLY_STATUS 0 "INSUFFICIENT" 1 "SUFFICIENT" 2 "ERROR" 3 "NOT_AVAIL" ;
VAL_ 1085 PNEUMATIC_SUPPLY_STATUS 0 "INSUFFICIENT" 1 "SUFFICIENT" 2 "ERROR" 3 "NOT_AVAIL" ;
VAL_ 1085 AMBER_WARNING_LAMP_REQUEST 0 "LAMP_OFF"  1 "LAMP_ON"  2 "ERROR" 3 "NOT_AVAIL" ;
VAL_ 1085 RED_WARNING_LAMP_REQUEST 0 "LAMP_OFF"  1 "LAMP_ON"  2 "ERROR" 3 "NOT_AVAIL" ;

// TRAILER_FAULT_RPT_02 VALUES
VAL_ 1086 SERVICE_BRAKE_STATUS 0 "PASSIVE" 1 "ACTIVE" 2 "ERROR" 3 "NOT_AVAIL" ;
VAL_ 1086 ABS_STATUS 0 "PASSIVE" 1 "ACTIVE" 2 "ERROR" 3 "NOT_AVAIL" ;
VAL_ 1086 ELECTRICAL_SUPPLY_STATUS 0 "INSUFFICIENT" 1 "SUFFICIENT" 2 "ERROR" 3 "NOT_AVAIL" ;
VAL_ 1086 PNEUMATIC_SUPPLY_STATUS 0 "INSUFFICIENT" 1 "SUFFICIENT" 2 "ERROR" 3 "NOT_AVAIL" ;
VAL_ 1086 AMBER_WARNING_LAMP_REQUEST 0 "LAMP_OFF"  1 "LAMP_ON"  2 "ERROR" 3 "NOT_AVAIL" ;
VAL_ 1086 RED_WARNING_LAMP_REQUEST 0 "LAMP_OFF"  1 "LAMP_ON"  2 "ERROR" 3 "NOT_AVAIL" ;

// TRAILER_FAULT_RPT_03 VALUES
VAL_ 1087 SERVICE_BRAKE_STATUS 0 "PASSIVE" 1 "ACTIVE" 2 "ERROR" 3 "NOT_AVAIL" ;
VAL_ 1087 ABS_STATUS 0 "PASSIVE" 1 "ACTIVE" 2 "ERROR" 3 "NOT_AVAIL" ;
VAL_ 1087 ELECTRICAL_SUPPLY_STATUS 0 "INSUFFICIENT" 1 "SUFFICIENT" 2 "ERROR" 3 "NOT_AVAIL" ;
VAL_ 1087 PNEUMATIC_SUPPLY_STATUS 0 "INSUFFICIENT" 1 "SUFFICIENT" 2 "ERROR" 3 "NOT_AVAIL" ;
VAL_ 1087 AMBER_WARNING_LAMP_REQUEST 0 "LAMP_OFF"  1 "LAMP_ON"  2 "ERROR" 3 "NOT_AVAIL" ;
VAL_ 1087 RED_WARNING_LAMP_REQUEST 0 "LAMP_OFF"  1 "LAMP_ON"  2 "ERROR" 3 "NOT_AVAIL" ;

// TRAILER_FAULT_RPT_04 VALUES
VAL_ 1088 SERVICE_BRAKE_STATUS 0 "PASSIVE" 1 "ACTIVE" 2 "ERROR" 3 "NOT_AVAIL" ;
VAL_ 1088 ABS_STATUS 0 "PASSIVE" 1 "ACTIVE" 2 "ERROR" 3 "NOT_AVAIL" ;
VAL_ 1088 ELECTRICAL_SUPPLY_STATUS 0 "INSUFFICIENT" 1 "SUFFICIENT" 2 "ERROR" 3 "NOT_AVAIL" ;
VAL_ 1088 PNEUMATIC_SUPPLY_STATUS 0 "INSUFFICIENT" 1 "SUFFICIENT" 2 "ERROR" 3 "NOT_AVAIL" ;
VAL_ 1088 AMBER_WARNING_LAMP_REQUEST 0 "LAMP_OFF"  1 "LAMP_ON"  2 "ERROR" 3 "NOT_AVAIL" ;
VAL_ 1088 RED_WARNING_LAMP_REQUEST 0 "LAMP_OFF"  1 "LAMP_ON"  2 "ERROR" 3 "NOT_AVAIL" ;

// TRAILER_PAYLOAD_RPT_00 VALUES
VAL_ 1078 PAYLOAD_00 32763 "RESERVED" 32764 "RESERVED"  32765 "RESERVED"  32766 "ERROR" 32767 "NOT_AVAIL" ;
VAL_ 1078 TARE_00 65531 "RESERVED" 65532 "RESERVED" 65533 "RESERVED" 65534 "ERROR" 65535 "NOT_AVAIL" ;
VAL_ 1078 PAYLOAD_01 32763 "RESERVED" 32764 "RESERVED"  32765 "RESERVED"  32766 "ERROR" 32767 "NOT_AVAIL" ;
VAL_ 1078 TARE_01 65531 "RESERVED" 65532 "RESERVED" 65533 "RESERVED" 65534 "ERROR" 65535 "NOT_AVAIL" ;

// TRAILER_IDENTIFIER_RPT_00 VALUES
VAL_ 1095 TRAILER_IDENTIFIER 4294967291 "RESERVED"  4294967292 "RESERVED" 4294967293 "RESERVED" 4294967294 "ERROR" 4294967295 "NOT_AVAIL" ;

// TRAILER_IDENTIFIER_RPT_01 VALUES
VAL_ 1096 TRAILER_IDENTIFIER 4294967291 "RESERVED"  4294967292 "RESERVED" 4294967293 "RESERVED" 4294967294 "ERROR" 4294967295 "NOT_AVAIL" ;

// TRAILER_IDENTIFIER_RPT_02 VALUES
VAL_ 1097 TRAILER_IDENTIFIER 4294967291 "RESERVED"  4294967292 "RESERVED" 4294967293 "RESERVED" 4294967294 "ERROR" 4294967295 "NOT_AVAIL" ;

// TRAILER_IDENTIFIER_RPT_03 VALUES
VAL_ 1098 TRAILER_IDENTIFIER 4294967291 "RESERVED"  4294967292 "RESERVED" 4294967293 "RESERVED" 4294967294 "ERROR" 4294967295 "NOT_AVAIL" ;

// TRAILER_IDENTIFIER_RPT_04 VALUES
VAL_ 1099 TRAILER_IDENTIFIER 4294967291 "RESERVED"  4294967292 "RESERVED" 4294967293 "RESERVED" 4294967294 "ERROR" 4294967295 "NOT_AVAIL" ;

// TRAILER_IDENTIFIER_RPT_05 VALUES
VAL_ 1106 TRAILER_IDENTIFIER 4294967291 "RESERVED"  4294967292 "RESERVED" 4294967293 "RESERVED" 4294967294 "ERROR" 4294967295 "NOT_AVAIL" ;

// TRAILER_PAYLOAD_RPT_01 VALUES
VAL_ 1079 PAYLOAD_00 32763 "RESERVED" 32764 "RESERVED"  32765 "RESERVED"  32766 "ERROR" 32767 "NOT_AVAIL" ;
VAL_ 1079 TARE_00 65531 "RESERVED" 65532 "RESERVED" 65533 "RESERVED" 65534 "ERROR" 65535 "NOT_AVAIL" ;
VAL_ 1079 PAYLOAD_01 32763 "RESERVED" 32764 "RESERVED"  32765 "RESERVED"  32766 "ERROR" 32767 "NOT_AVAIL" ;
VAL_ 1079 TARE_01 65531 "RESERVED" 65532 "RESERVED" 65533 "RESERVED" 65534 "ERROR" 65535 "NOT_AVAIL" ;

// TRAILER_PAYLOAD_RPT_02 VALUES
VAL_ 1080 PAYLOAD_00 32763 "RESERVED" 32764 "RESERVED"  32765 "RESERVED"  32766 "ERROR" 32767 "NOT_AVAIL" ;
VAL_ 1080 TARE_00 65531 "RESERVED" 65532 "RESERVED" 65533 "RESERVED" 65534 "ERROR" 65535 "NOT_AVAIL" ;
VAL_ 1080 PAYLOAD_01 32763 "RESERVED" 32764 "RESERVED"  32765 "RESERVED"  32766 "ERROR" 32767 "NOT_AVAIL" ;
VAL_ 1080 TARE_01 65531 "RESERVED" 65532 "RESERVED" 65533 "RESERVED" 65534 "ERROR" 65535 "NOT_AVAIL" ;

// TRAILER_WHEEL_SPEED_RPT_00
VAL_ 1069 WHEEL_BASED_VEHICLE_SPEED 65531 "RESERVED" 65532 "RESERVED" 65533 "RESERVED" 65534 "ERROR" 65535 "NOT_AVAIL" ;
VAL_ 1069 WHEEL_SPEED_DIFFERENCE_MAIN_AXLE 65531 "RESERVED" 65532 "RESERVED" 65533 "RESERVED" 65534 "ERROR" 65535 "NOT_AVAIL" ;

// TURN_AUX_RPT VALUES
VAL_ 816 DRIVER_BLINKER_BULB_ON 0 "OFF" 1 "ON" ;
VAL_ 816 PASS_BLINKER_BULB_ON 0 "OFF" 1 "ON" ;
VAL_ 816 DRIVER_BLINKER_BULB_ON_AVAIL 0 "NOT_AVAILABLE" 1 "AVAILABLE" ;
VAL_ 816 PASS_BLINKER_BULB_ON_AVAIL 0 "NOT_AVAILABLE" 1 "AVAILABLE" ;

// TURN_CMD VALUES
VAL_ 304 ENABLE 0 "DISABLE" 1 "ENABLE" ;
VAL_ 304 IGNORE_OVERRIDES 0 "FALSE" 1 "TRUE" ;
VAL_ 304 CLEAR_OVERRIDE 0 "FALSE" 1 "TRUE" ;
VAL_ 304 TURN_SIGNAL_CMD 0 "RIGHT" 1 "NONE" 2 "LEFT" 3 "HAZARD" ;

// TURN_RPT VALUES
VAL_ 560 ENABLED 0 "FALSE" 1 "TRUE" ;
VAL_ 560 OVERRIDE_ACTIVE 0 "FALSE" 1 "TRUE" ;
VAL_ 560 COMMAND_OUTPUT_FAULT 0 "NO_FAULT" 1 "FAULT" ;
VAL_ 560 INPUT_OUTPUT_FAULT 0 "NO_FAULT" 1 "FAULT" ;
VAL_ 560 OUTPUT_REPORTED_FAULT 0 "NO_FAULT" 1 "FAULT" ;
VAL_ 560 PACMOD_FAULT 0 "NO_FAULT" 1 "FAULT" ;
VAL_ 560 VEHICLE_FAULT 0 "NO_FAULT" 1 "FAULT" ;
VAL_ 560 COMMAND_TIMEOUT 0 "NO_TIMEOUT" 1 "TIMEOUT" ;
VAL_ 560 MANUAL_INPUT 0 "RIGHT" 1 "NONE" 2 "LEFT" 3 "HAZARD" 251 "RESERVED" 252 "RESERVED" 253 "RESERVED" 254 "ERROR" 255 "NOT_AVAIL" ;
VAL_ 560 COMMANDED_VALUE 0 "RIGHT" 1 "NONE" 2 "LEFT" 3 "HAZARD" 251 "RESERVED" 252 "RESERVED" 253 "RESERVED" 254 "ERROR" 255 "NOT_AVAIL" ;
VAL_ 560 OUTPUT_VALUE 0 "RIGHT" 1 "NONE" 2 "LEFT" 3 "HAZARD" 251 "RESERVED" 252 "RESERVED" 253 "RESERVED" 254 "ERROR" 255 "NOT_AVAIL" ;

// USER_NOTIFICATION_CMD VALUES
VAL_ 1053 BUZZER_MUTE 0 "NOT_MUTED" 1 "MUTED" ;
VAL_ 1053 LIGHT_COMMAND 0 "NO_ACTION" 1 "WHITE" 2 "RED" 3 "GREEN" 4 "BLUE" 5 "PURPLE" 6 "ORANGE" 7 "YELLOW" 8 "TEAL" 9 "PINK" 10 "OFF" ;
VAL_ 1053 BUZZER_ON 0 "NO_ACTION" 1 "BUZZER_ON" ;
VAL_ 1053 BUZZER_MUTE_INDICATOR 0 "ENABLED" 1 "DISABLED" ;
VAL_ 1053 LED_BRIGHTNESS 0 "NO_ACTION" 1 "MIN_BRIGHTNESS" 2 "LEVEL_1" 3 "LEVEL_2" 4 "LEVEL_3" 5 "LEVEL_4" 6 "LEVEL_5" 7 "LEVEL_6" 8 "LEVEL_7" 9 "LEVEL_8" 10 "LEVEL_9" 11 "LEVEL_10" 12 "LEVEL_11" 13 "MAX_BRIGHTNESS" ;
VAL_ 1053 LIGHT_STATUS_COMMAND 0 "NO_ACTION" 1 "NO_BLINK" 2 "BLINK" 3 "ALTERNATE" ;
VAL_ 1053 LIGHT_COMMAND_ALTERNATE 0 "NO_ACTION" 1 "WHITE" 2 "RED" 3 "GREEN" 4 "BLUE" 5 "PURPLE" 6 "ORANGE" 7 "YELLOW" 8 "TEAL" 9 "PINK" 10 "OFF" ;

// USER_PC_HEALTH_RPT_00 VALUES
VAL_ 37 USER_PC_APPLICATION_FAULT  0 "NO_FAULT" 1 "FAULT" ;

// USER_PC_HEALTH_RPT_01 VALUES
VAL_ 38 USER_PC_APPLICATION_FAULT  0 "NO_FAULT" 1 "FAULT" ;

// VEHICLE_FAULT_RPT VALUES
VAL_ 66 ENGINE_CHECK_LIGHT 0 "FALSE" 1 "TRUE";
VAL_ 66 ENGINE_CHECK_LIGHT_AVAIL 0 "NOT_AVAILABLE" 1 "AVAILABLE";
VAL_ 66 TRC_FAULT_LIGHT 0 "FALSE" 1 "TRUE";
VAL_ 66 TRC_FAULT_LIGHT_AVAIL 0 "NOT_AVAILABLE" 1 "AVAILABLE";
VAL_ 66 TRC_OFF_FAULT_LIGHT 0 "FALSE" 1 "TRUE";
VAL_ 66 TRC_OFF_FAULT_LIGHT_AVAIL 0 "NOT_AVAILABLE" 1 "AVAILABLE";
VAL_ 66 ANTILOCK_BRAKE_FAULT_LIGHT 0 "FALSE" 1 "TRUE";
VAL_ 66 ANTILOCK_BRAKE_FAULT_LIGHT_AVAIL 0 "NOT_AVAILABLE" 1 "AVAILABLE";
VAL_ 66 TIRE_FAULT_LIGHT 0 "FALSE" 1 "TRUE";
VAL_ 66 TIRE_FAULT_LIGHT_AVAIL 0 "NOT_AVAILABLE" 1 "AVAILABLE";
VAL_ 66 AIR_BAGS_FAULT_LIGHT 0 "FALSE" 1 "TRUE";
VAL_ 66 AIR_BAGS_FAULT_LIGHT_AVAIL 0 "NOT_AVAILABLE" 1 "AVAILABLE";
VAL_ 66 LOW_ENGINE_OIL_PRESSURE 0 "FALSE" 1 "TRUE";
VAL_ 66 LOW_ENGINE_OIL_PRESSURE_AVAIL 0 "NOT_AVAILABLE" 1 "AVAILABLE";
VAL_ 66 BRAKE_FAULT 0 "FALSE" 1 "TRUE";
VAL_ 66 BRAKE_FAULT_AVAIL 0 "NOT_AVAILABLE" 1 "AVAILABLE";
VAL_ 66 BRK_APPLIED_POWER_REDUCED 0 "FALSE" 1 "TRUE";
VAL_ 66 BRK_APPLIED_POWER_REDUCED_AVAIL 0 "NOT_AVAILABLE" 1 "AVAILABLE";
VAL_ 66 STEERING_LOSS_STOP_SAFELY 0 "FALSE" 1 "TRUE";
VAL_ 66 STEERING_LOSS_STOP_SAFELY_AVAIL 0 "NOT_AVAILABLE" 1 "AVAILABLE";
VAL_ 66 STEERING_FAULT_SERVICE_NOW 0 "FALSE" 1 "TRUE";
VAL_ 66 STEERING_FAULT_SERVICE_NOW_AVAIL 0 "NOT_AVAILABLE" 1 "AVAILABLE";
VAL_ 66 XMSN_FAULT_SERVICE_NOW 0 "FALSE" 1 "TRUE";
VAL_ 66 XMSN_FAULT_SERVICE_NOW_AVAIL 0 "NOT_AVAILABLE" 1 "AVAILABLE";
VAL_ 66 XMSN_OVER_TEMP_STOP_SAFELY 0 "FALSE" 1 "TRUE";
VAL_ 66 XMSN_OVER_TEMP_STOP_SAFELY_AVAIL 0 "NOT_AVAILABLE" 1 "AVAILABLE";
VAL_ 66 LOW_BATTERY_FEATURES_OFF 0 "FALSE" 1 "TRUE";
VAL_ 66 LOW_BATTERY_FEATURES_OFF_AVAIL 0 "NOT_AVAILABLE" 1 "AVAILABLE";
VAL_ 66 CHARGING_SYSTEM_FAULT 0 "FALSE" 1 "TRUE";
VAL_ 66 CHARGING_SYSTEM_FAULT_AVAIL 0 "NOT_AVAILABLE" 1 "AVAILABLE";

// VEHICLE_FAULT_RPT_2 VALUES
VAL_ 1083 BRAKES_AMBER_LAMP 0 "LAMP_OFF"  1 "LAMP_ON" 2 "ERROR" 3 "NOT_AVAIL" ;
VAL_ 1083 BRAKES_RED_LAMP 0 "LAMP_OFF"  1 "LAMP_ON" 2 "ERROR" 3 "NOT_AVAIL" ;
VAL_ 1083 CHASSIS_AMBER_LAMP 0 "LAMP_OFF"  1 "LAMP_ON" 2 "ERROR" 3 "NOT_AVAIL" ;
VAL_ 1083 CHASSIS_RED_LAMP 0 "LAMP_OFF"  1 "LAMP_ON" 2 "ERROR" 3 "NOT_AVAIL" ;
VAL_ 1083 ELECTRONIC_BRAKES_AMBER_LAMP  0 "LAMP_OFF"  1 "LAMP_ON" 2 "ERROR" 3 "NOT_AVAIL" ;
VAL_ 1083 ELECTRONIC_BRAKES_RED_LAMP 0 "LAMP_OFF"  1 "LAMP_ON" 2 "ERROR" 3 "NOT_AVAIL" ;
VAL_ 1083 ENGINE_AMBER_LAMP 0 "LAMP_OFF"  1 "LAMP_ON" 2 "ERROR" 3 "NOT_AVAIL" ;
VAL_ 1083 ENGINE_RED_LAMP 0 "LAMP_OFF"  1 "LAMP_ON" 2 "ERROR" 3 "NOT_AVAIL" ;
VAL_ 1083 ENGINE_BRAKE_AMBER_LAMP 0 "LAMP_OFF"  1 "LAMP_ON" 2 "ERROR" 3 "NOT_AVAIL" ;
VAL_ 1083 ENGINE_BRAKE_RED_LAMP 0 "LAMP_OFF"  1 "LAMP_ON" 2 "ERROR" 3 "NOT_AVAIL" ;
VAL_ 1083 MANAGEMENT_ECU_AMBER_LAMP 0 "LAMP_OFF"  1 "LAMP_ON" 2 "ERROR" 3 "NOT_AVAIL" ;
VAL_ 1083 MANAGEMENT_ECU_RED_LAMP 0 "LAMP_OFF"  1 "LAMP_ON" 2 "ERROR" 3 "NOT_AVAIL" ;
VAL_ 1083 PNEUMATIC_AMBER_LAMP 0 "LAMP_OFF"  1 "LAMP_ON" 2 "ERROR" 3 "NOT_AVAIL" ;
VAL_ 1083 PNEUMATIC_RED_LAMP 0 "LAMP_OFF"  1 "LAMP_ON" 2 "ERROR" 3 "NOT_AVAIL" ;
VAL_ 1083 RESTRAINTS_AMBER_LAMP 0 "LAMP_OFF"  1 "LAMP_ON" 2 "ERROR" 3 "NOT_AVAIL" ;
VAL_ 1083 RESTRAINTS_RED_LAMP 0 "LAMP_OFF"  1 "LAMP_ON" 2 "ERROR" 3 "NOT_AVAIL" ;
VAL_ 1083 TRAILER_ABS_AMBER_LAMP 0 "LAMP_OFF"  1 "LAMP_ON" 2 "ERROR" 3 "NOT_AVAIL" ;
VAL_ 1083 TRAILER_ABS_RED_LAMP 0 "LAMP_OFF"  1 "LAMP_ON" 2 "ERROR" 3 "NOT_AVAIL" ;
VAL_ 1083 TRANSMISSION_AMBER_LAMP 0 "LAMP_OFF"  1 "LAMP_ON" 2 "ERROR" 3 "NOT_AVAIL" ;
VAL_ 1083 TRANSMISSION_RED_LAMP 0 "LAMP_OFF"  1 "LAMP_ON" 2 "ERROR" 3 "NOT_AVAIL" ;

// VEHICLE_SPEED_RPT VALUES
VAL_ 1024 VEHICLE_SPEED 32763 "RESERVED" 32764 "RESERVED" 32765 "RESERVED" 32766 "ERROR" 32767 "NOT_AVAIL" ;

// WATCHDOG_RPT VALUES
VAL_ 1536 GLOBAL_ENABLE_FLAG 0 "FALSE" 1 "TRUE" ;
VAL_ 1536 GLOBAL_OVERRIDE_ACTIVE 0 "FALSE" 1 "TRUE" ;
VAL_ 1536 GLOBAL_COMMAND_TIMEOUT_ERROR 0 "FALSE" 1 "TRUE" ;
VAL_ 1536 GLOBAL_PACMOD_SUBSYSTEM_TIMEOUT 0 "FALSE" 1 "TRUE" ;
VAL_ 1536 GLOBAL_VEHICLE_CAN_TIMEOUT 0 "FALSE" 1 "TRUE" ;
VAL_ 1536 GLOBAL_PACMOD_SYS_FAULT_ACTIVE 0 "FALSE" 1 "TRUE" ;
VAL_ 1536 GLOBAL_CONFIG_FAULT_ACTIVE 0 "FALSE" 1 "TRUE" ;
VAL_ 1536 GLOBAL_TIMEOUT 0 "FALSE" 1 "TRUE" ;
VAL_ 1536 ACCEL_ENABLED 0 "FALSE" 1 "TRUE" ;
VAL_ 1536 ACCEL_OVERRIDE_ACTIVE 0 "FALSE" 1 "TRUE" ;
VAL_ 1536 ACCEL_COMMAND_OUTPUT_FAULT 0 "FALSE" 1 "TRUE" ;
VAL_ 1536 ACCEL_INPUT_OUTPUT_FAULT 0 "FALSE" 1 "TRUE" ;
VAL_ 1536 ACCEL_OUTPUT_REPORTED_FAULT 0 "FALSE" 1 "TRUE" ;
VAL_ 1536 ACCEL_PACMOD_FAULT 0 "FALSE" 1 "TRUE" ;
VAL_ 1536 ACCEL_VEHICLE_FAULT 0 "FALSE" 1 "TRUE" ;
VAL_ 1536 ACCEL_TIMEOUT 0 "FALSE" 1 "TRUE" ;
VAL_ 1536 BRAKE_ENABLED 0 "FALSE" 1 "TRUE" ;
VAL_ 1536 BRAKE_OVERRIDE_ACTIVE 0 "FALSE" 1 "TRUE" ;
VAL_ 1536 BRAKE_COMMAND_OUTPUT_FAULT 0 "FALSE" 1 "TRUE" ;
VAL_ 1536 BRAKE_INPUT_OUTPUT_FAULT 0 "FALSE" 1 "TRUE" ;
VAL_ 1536 BRAKE_OUTPUT_REPORTED_FAULT 0 "FALSE" 1 "TRUE" ;
VAL_ 1536 BRAKE_PACMOD_FAULT 0 "FALSE" 1 "TRUE" ;
VAL_ 1536 BRAKE_VEHICLE_FAULT 0 "FALSE" 1 "TRUE" ;
VAL_ 1536 BRAKE_TIMEOUT 0 "FALSE" 1 "TRUE" ;
VAL_ 1536 SHIFT_ENABLED 0 "FALSE" 1 "TRUE" ;
VAL_ 1536 SHIFT_OVERRIDE_ACTIVE 0 "FALSE" 1 "TRUE" ;
VAL_ 1536 SHIFT_COMMAND_OUTPUT_FAULT 0 "FALSE" 1 "TRUE" ;
VAL_ 1536 SHIFT_INPUT_OUTPUT_FAULT 0 "FALSE" 1 "TRUE" ;
VAL_ 1536 SHIFT_OUTPUT_REPORTED_FAULT 0 "FALSE" 1 "TRUE" ;
VAL_ 1536 SHIFT_PACMOD_FAULT 0 "FALSE" 1 "TRUE" ;
VAL_ 1536 SHIFT_VEHICLE_FAULT 0 "FALSE" 1 "TRUE" ;
VAL_ 1536 SHIFT_TIMEOUT 0 "FALSE" 1 "TRUE" ;
VAL_ 1536 STEER_ENABLED 0 "FALSE" 1 "TRUE" ;
VAL_ 1536 STEER_OVERRIDE_ACTIVE 0 "FALSE" 1 "TRUE" ;
VAL_ 1536 STEER_COMMAND_OUTPUT_FAULT 0 "FALSE" 1 "TRUE" ;
VAL_ 1536 STEER_INPUT_OUTPUT_FAULT 0 "FALSE" 1 "TRUE" ;
VAL_ 1536 STEER_OUTPUT_REPORTED_FAULT 0 "FALSE" 1 "TRUE" ;
VAL_ 1536 STEER_PACMOD_FAULT 0 "FALSE" 1 "TRUE" ;
VAL_ 1536 STEER_VEHICLE_FAULT 0 "FALSE" 1 "TRUE" ;
VAL_ 1536 STEER_TIMEOUT 0 "FALSE" 1 "TRUE" ;
VAL_ 1536 PACMOD1_CONFIG_FAULT 0 "FALSE" 1 "TRUE" ;
VAL_ 1536 PACMOD1_CAN_TIMEOUT 0 "FALSE" 1 "TRUE" ;
VAL_ 1536 PACMOD1_COUNTER_FAULT 0 "FALSE" 1 "TRUE" ;
VAL_ 1536 PACMOD2_CONFIG_FAULT 0 "FALSE" 1 "TRUE" ;
VAL_ 1536 PACMOD2_CAN_TIMEOUT 0 "FALSE" 1 "TRUE" ;
VAL_ 1536 PACMOD2_COUNTER_FAULT 0 "FALSE" 1 "TRUE" ;
VAL_ 1536 PACMOD3_CONFIG_FAULT 0 "FALSE" 1 "TRUE" ;
VAL_ 1536 PACMOD3_CAN_TIMEOUT 0 "FALSE" 1 "TRUE" ;
VAL_ 1536 PACMOD3_COUNTER_FAULT 0 "FALSE" 1 "TRUE" ;
VAL_ 1536 PACMINI1_RPT_TIMEOUT 0 "FALSE" 1 "TRUE" ;
VAL_ 1536 PACMINI1_CONFIG_FAULT 0 "FALSE" 1 "TRUE" ;
VAL_ 1536 PACMINI1_CAN_TIMEOUT 0 "FALSE" 1 "TRUE" ;
VAL_ 1536 PACMINI1_COUNTER_FAULT 0 "FALSE" 1 "TRUE" ;
VAL_ 1536 PACMINI2_RPT_TIMEOUT 0 "FALSE" 1 "TRUE" ;
VAL_ 1536 PACMINI2_CONFIG_FAULT 0 "FALSE" 1 "TRUE" ;
VAL_ 1536 PACMINI2_CAN_TIMEOUT 0 "FALSE" 1 "TRUE" ;
VAL_ 1536 PACMINI2_COUNTER_FAULT 0 "FALSE" 1 "TRUE" ;
VAL_ 1536 PACMINI3_RPT_TIMEOUT 0 "FALSE" 1 "TRUE" ;
VAL_ 1536 PACMINI3_CONFIG_FAULT 0 "FALSE" 1 "TRUE" ;
VAL_ 1536 PACMINI3_CAN_TIMEOUT 0 "FALSE" 1 "TRUE" ;
VAL_ 1536 PACMINI3_COUNTER_FAULT 0 "FALSE" 1 "TRUE" ;
VAL_ 1536 PACMOD_SYSTEM_PRESENT_FAULT 0 "FALSE" 1 "TRUE" ;
VAL_ 1536 PACMINI_SYSTEM_PRESENT_FAULT 0 "FALSE" 1 "TRUE" ;
VAL_ 1536 GLOBAL_INT_POWER_SUPPLY_FAULT 0 "FALSE" 1 "TRUE" ;

// WATCHDOG_RPT_2 VALUES
VAL_ 1057 ACCEL_RPT_TIMEOUT 0 "FALSE" 1 "TRUE" ;
VAL_ 1057 BRAKE_RPT_TIMEOUT 0 "FALSE" 1 "TRUE" ;
VAL_ 1057 BRAKE_DECEL_RPT_TIMEOUT 0 "FALSE" 1 "TRUE" ;
VAL_ 1057 CABIN_CLIMATE_RPT_TIMEOUT 0 "FALSE" 1 "TRUE" ;
VAL_ 1057 CABIN_FAN_SPEED_RPT_TIMEOUT 0 "FALSE" 1 "TRUE" ;
VAL_ 1057 CABIN_TEMP_RPT_TIMEOUT 0 "FALSE" 1 "TRUE" ;
VAL_ 1057 CRUISE_CONTROL_RPT_TIMEOUT 0 "FALSE" 1 "TRUE" ;
VAL_ 1057 DASH_LEFT_RPT_TIMEOUT 0 "FALSE" 1 "TRUE" ;
VAL_ 1057 DASH_RIGHT_RPT_TIMEOUT 0 "FALSE" 1 "TRUE" ;
VAL_ 1057 ENGINE_BRAKE_RPT_TIMEOUT 0 "FALSE" 1 "TRUE" ;
VAL_ 1057 HAZARD_LIGHTS_RPT_TIMEOUT 0 "FALSE" 1 "TRUE" ;
VAL_ 1057 HEADLIGHT_RPT_TIMEOUT 0 "FALSE" 1 "TRUE" ;
VAL_ 1057 HORN_RPT_TIMEOUT 0 "FALSE" 1 "TRUE" ;
VAL_ 1057 MARKER_LAMP_RPT_TIMEOUT 0 "FALSE" 1 "TRUE" ;
VAL_ 1057 MEDIA_CONTROLS_RPT_TIMEOUT 0 "FALSE" 1 "TRUE" ;
VAL_ 1057 PARKING_BRAKE_RPT_TIMEOUT 0 "FALSE" 1 "TRUE" ;
VAL_ 1057 REAR_PASS_DOOR_RPT_TIMEOUT 0 "FALSE" 1 "TRUE" ;
VAL_ 1057 SHIFT_RPT_TIMEOUT 0 "FALSE" 1 "TRUE" ;
VAL_ 1057 SPRAYER_RPT_TIMEOUT 0 "FALSE" 1 "TRUE" ;
VAL_ 1057 STEERING_RPT_TIMEOUT 0 "FALSE" 1 "TRUE" ;
VAL_ 1057 TURN_RPT_TIMEOUT 0 "FALSE" 1 "TRUE" ;
VAL_ 1057 WIPER_RPT_TIMEOUT 0 "FALSE" 1 "TRUE" ;
VAL_ 1057 PACMOD1_SANITY_FAULT 0 "FALSE" 1 "TRUE" ;
VAL_ 1057 PACMOD2_SANITY_FAULT 0 "FALSE" 1 "TRUE" ;
VAL_ 1057 PACMOD3_SANITY_FAULT 0 "FALSE" 1 "TRUE" ;
VAL_ 1057 PACMINI1_SANITY_FAULT 0 "FALSE" 1 "TRUE" ;
VAL_ 1057 PACMINI2_SANITY_FAULT 0 "FALSE" 1 "TRUE" ;
VAL_ 1057 PACMINI3_SANITY_FAULT 0 "FALSE" 1 "TRUE" ;
VAL_ 1057 PACMOD1_COMPONENT_RPT_TIMEOUT 0 "FALSE" 1 "TRUE" ;
VAL_ 1057 PACMOD2_COMPONENT_RPT_TIMEOUT 0 "FALSE" 1 "TRUE" ;
VAL_ 1057 PACMOD3_COMPONENT_RPT_TIMEOUT 0 "FALSE" 1 "TRUE" ;
VAL_ 1057 PACMINI1_COMPONENT_RPT_TIMEOUT 0 "FALSE" 1 "TRUE" ;
VAL_ 1057 PACMINI2_COMPONENT_RPT_TIMEOUT 0 "FALSE" 1 "TRUE" ;
VAL_ 1057 PACMINI3_COMPONENT_RPT_TIMEOUT 0 "FALSE" 1 "TRUE" ;
VAL_ 1057 PACMOD1_SYSTEM_PRESENT_FAULT 0 "FALSE" 1 "TRUE" ;
VAL_ 1057 PACMOD2_SYSTEM_PRESENT_FAULT 0 "FALSE" 1 "TRUE" ;
VAL_ 1057 PACMOD3_SYSTEM_PRESENT_FAULT 0 "FALSE" 1 "TRUE" ;
VAL_ 1057 PACMINI1_SYSTEM_PRESENT_FAULT 0 "FALSE" 1 "TRUE" ;
VAL_ 1057 PACMINI2_SYSTEM_PRESENT_FAULT 0 "FALSE" 1 "TRUE" ;
VAL_ 1057 PACMINI3_SYSTEM_PRESENT_FAULT 0 "FALSE" 1 "TRUE" ;
VAL_ 1057 DRIVE_MODE_INVALID 0 "FALSE" 1 "TRUE" ;
VAL_ 1057 GLOBAL_CMD_SANITY_FAULT 0 "FALSE" 1 "TRUE" ;
VAL_ 1057 GLOBAL_CMD_TIMEOUT 0 "FALSE" 1 "TRUE" ;
VAL_ 1057 EXHAUST_BRAKE_RPT_TIMEOUT 0 "FALSE" 1 "TRUE" ;
VAL_ 1057 POWER_TAKE_OFF_RPT_TIMEOUT 0 "FALSE" 1 "TRUE" ;
VAL_ 1057 TIPPER_BODY_00_RPT_TIMEOUT 0 "FALSE" 1 "TRUE" ;
VAL_ 1057 TRAILER_AIR_SUPPLY_RPT_TIMEOUT 0 "FALSE" 1 "TRUE" ;
VAL_ 1057 TRAILER_BRAKE_RPT_TIMEOUT 0 "FALSE" 1 "TRUE" ;
VAL_ 1057 ENGINE_RPT_TIMEOUT 0 "FALSE" 1 "TRUE" ;
VAL_ 1057 TIPPER_BODY_01_RPT_TIMEOUT 0 "FALSE" 1 "TRUE" ;
VAL_ 1057 TIPPER_BODY_02_RPT_TIMEOUT 0 "FALSE" 1 "TRUE" ;
VAL_ 1057 DIFFERENTIAL_LOCKS_RPT_TIMEOUT 0 "FALSE" 1 "TRUE" ;

// WHEEL_SPEED_RPT VALUES
VAL_ 1031 WHEEL_SPD_AXLE_1_LEFT 65531 "RESERVED" 65532 "RESERVED" 65533 "RESERVED" 65534 "ERROR" 65535 "NOT_AVAIL";
VAL_ 1031 WHEEL_SPD_AXLE_1_RIGHT 65531 "RESERVED" 65532 "RESERVED" 65533 "RESERVED" 65534 "ERROR" 65535 "NOT_AVAIL";
VAL_ 1031 WHEEL_SPD_AXLE_2_LEFT 65531 "RESERVED" 65532 "RESERVED" 65533 "RESERVED" 65534 "ERROR" 65535 "NOT_AVAIL";
VAL_ 1031 WHEEL_SPD_AXLE_2_RIGHT 65531 "RESERVED" 65532 "RESERVED" 65533 "RESERVED" 65534 "ERROR" 65535 "NOT_AVAIL";

// WHEEL_SPEED_RPT_2 VALUES
VAL_ 1062 WHEEL_SPD_AXLE_3_LEFT 65531 "RESERVED" 65532 "RESERVED" 65533 "RESERVED" 65534 "ERROR" 65535 "NOT_AVAIL";
VAL_ 1062 WHEEL_SPD_AXLE_3_RIGHT 65531 "RESERVED" 65532 "RESERVED" 65533 "RESERVED" 65534 "ERROR" 65535 "NOT_AVAIL";
VAL_ 1062 WHEEL_SPD_AXLE_4_LEFT 65531 "RESERVED" 65532 "RESERVED" 65533 "RESERVED" 65534 "ERROR" 65535 "NOT_AVAIL";
VAL_ 1062 WHEEL_SPD_AXLE_4_RIGHT 65531 "RESERVED" 65532 "RESERVED" 65533 "RESERVED" 65534 "ERROR" 65535 "NOT_AVAIL";

// WIPER_AUX_RPT VALUES
VAL_ 820 FRONT_WIPING 0 "NOT_WIPING" 1 "WIPING" 2 "ERROR" 3 "NOT_AVAIL" ;
VAL_ 820 REAR_WIPING 0 "NOT_WIPING" 1 "WIPING" 2 "ERROR" 3 "NOT_AVAIL" ;

// WIPER_CMD VALUES
VAL_ 308 ENABLE 0 "DISABLE" 1 "ENABLE" ;
VAL_ 308 IGNORE_OVERRIDES 0 "FALSE" 1 "TRUE" ;
VAL_ 308 CLEAR_OVERRIDE 0 "FALSE" 1 "TRUE" ;
VAL_ 308 WIPER_CMD 255 "HIGH" 254 "MEDIUM" 253 "LOW" 10 "INTERMITTENT_10" 9 "INTERMITTENT_9" 8 "INTERMITTENT_8" 7 "INTERMITTENT_7" 6 "INTERMITTENT_6" 5 "INTERMITTENT_5" 4 "INTERMITTENT_4" 3 "INTERMITTENT_3" 2 "INTERMITTENT_2" 1 "INTERMITTENT_1" 0 "WIPERS_OFF" ;

// WIPER_RPT VALUES
VAL_ 564 ENABLED 0 "FALSE" 1 "TRUE" ;
VAL_ 564 OVERRIDE_ACTIVE 0 "FALSE" 1 "TRUE" ;
VAL_ 564 COMMAND_OUTPUT_FAULT 0 "NO_FAULT" 1 "FAULT" ;
VAL_ 564 INPUT_OUTPUT_FAULT 0 "NO_FAULT" 1 "FAULT" ;
VAL_ 564 OUTPUT_REPORTED_FAULT 0 "NO_FAULT" 1 "FAULT" ;
VAL_ 564 PACMOD_FAULT 0 "NO_FAULT" 1 "FAULT" ;
VAL_ 564 VEHICLE_FAULT 0 "NO_FAULT" 1 "FAULT" ;
VAL_ 564 COMMAND_TIMEOUT 0 "NO_TIMEOUT" 1 "TIMEOUT" ;
VAL_ 564 OUTPUT_VALUE 0 "WIPERS_OFF" 1 "INTERMITTENT_1" 2 "INTERMITTENT_2" 3 "INTERMITTENT_3" 4 "INTERMITTENT_4" 5 "INTERMITTENT_5" 6 "INTERMITTENT_6" 7 "INTERMITTENT_7" 8 "INTERMITTENT_8" 9 "INTERMITTENT_9" 10 "INTERMITTENT_10" 248 "LOW" 249 "MEDIUM" 250 "HIGH" 251 "RESERVED" 252 "RESERVED" 253 "RESERVED" 254 "ERROR" 255 "NOT_AVAIL" ;
VAL_ 564 COMMANDED_VALUE 0 "WIPERS_OFF" 1 "INTERMITTENT_1" 2 "INTERMITTENT_2" 3 "INTERMITTENT_3" 4 "INTERMITTENT_4" 5 "INTERMITTENT_5" 6 "INTERMITTENT_6" 7 "INTERMITTENT_7" 8 "INTERMITTENT_8" 9 "INTERMITTENT_9" 10 "INTERMITTENT_10" 248 "LOW" 249 "MEDIUM" 250 "HIGH" 251 "RESERVED" 252 "RESERVED" 253 "RESERVED" 254 "ERROR" 255 "NOT_AVAIL" ;
VAL_ 564 MANUAL_INPUT 0 "WIPERS_OFF" 1 "INTERMITTENT_1" 2 "INTERMITTENT_2" 3 "INTERMITTENT_3" 4 "INTERMITTENT_4" 5 "INTERMITTENT_5" 6 "INTERMITTENT_6" 7 "INTERMITTENT_7" 8 "INTERMITTENT_8" 9 "INTERMITTENT_9" 10 "INTERMITTENT_10" 248 "LOW" 249 "MEDIUM" 250 "HIGH" 251 "RESERVED" 252 "RESERVED" 253 "RESERVED" 254 "ERROR" 255 "NOT_AVAIL" ;
